VERSION ""

NS_ :

BS_:

BU_: SBW iBooster IMG ESB EBB TM ACC SRS SMART NAVI AHU FCM EPS HDS SS30 METER CVT STR ENG ABS VSA EAT RTC PUH EPT2 EPT1 EPB ASC ACM BCM E4WD ANC TPMS APS

BO_ 3221225472 VECTOR__INDEPENDENT_SIG_MSG: 0 Vector__XXX
 SG_ VSA_MAC_FVSTYLE1_1EF8AA15_1 : 0|4@0+ (1,0) [0|15] "" Vector__XXX
 SG_ SRS_RESET_FLAG_05E_1 : 0|1@0+ (1,0) [0|1] "-" Vector__XXX
 SG_ VSA_FAIL_MC_PRESS_SENSOR_05D_1 : 0|1@1- (1,0) [0|0] "" Vector__XXX
 SG_ VSA_ACC_INHBIT_ACC_BRK_PAD_TMP_1 : 0|1@0+ (1,0) [0|1] "" Vector__XXX
 SG_ VSA_INH_MODE6_1 : 0|1@0+ (1,0) [0|1] "" Vector__XXX
 SG_ VSA_INH_MODE5_1 : 0|1@0+ (1,0) [0|1] "" Vector__XXX
 SG_ VSA_INH_MODE4_1 : 0|1@0+ (1,0) [0|1] "" Vector__XXX
 SG_ VSA_CHECKSUM_1E8_1 : 0|4@0+ (1,0) [0|15] "" Vector__XXX
 SG_ VSA_ALIVE_COUNTER_1E8_1 : 0|2@0+ (1,0) [0|3] "" Vector__XXX
 SG_ VSA_INH_MODE_CHANGE_1 : 0|1@0+ (1,0) [0|1] "" Vector__XXX
 SG_ VSA_INH_MODE0_1 : 0|1@0+ (1,0) [0|1] "" Vector__XXX
 SG_ VSA_INH_MODE1_1 : 0|1@0+ (1,0) [0|1] "" Vector__XXX
 SG_ VSA_INH_MODE2_1 : 0|1@0+ (1,0) [0|1] "" Vector__XXX
 SG_ VSA_INH_MODE3_1 : 0|1@0+ (1,0) [0|1] "" Vector__XXX
 SG_ VSA_INH_MODE7_1 : 0|1@0+ (1,0) [0|1] "" Vector__XXX
 SG_ ENG_CAS_REQ_1 : 0|1@0+ (1,0) [0|1] "" Vector__XXX
 SG_ IMG_REQ_BRKRELAY_STATUS_1 : 0|1@0+ (1,0) [0|1] "" Vector__XXX

BO_ 2209174799 VSA_03AD550F_CH1: 3 VSA
 SG_ VSA_ALIVE_COUNTER_03AD550F_1 : 21|2@0+ (1,0) [0|3] ""  EPS
 SG_ VSA_CHECKSUM_03AD550F_1 : 19|4@0+ (1,0) [0|15] ""  EPS
 SG_ VSA_MAC_stRegMacKey_1 : 15|3@0+ (1,0) [0|7] ""  EPS
 SG_ VSA_MAC_stGenMac_1 : 2|3@0+ (1,0) [0|7] ""  EPS
 SG_ VSA_MAC_stCompMacCont_1 : 5|3@0+ (1,0) [0|7] ""  EPS
 SG_ VSA_MAC_stCompMacAccum_1 : 7|2@0+ (1,0) [0|3] ""  EPS

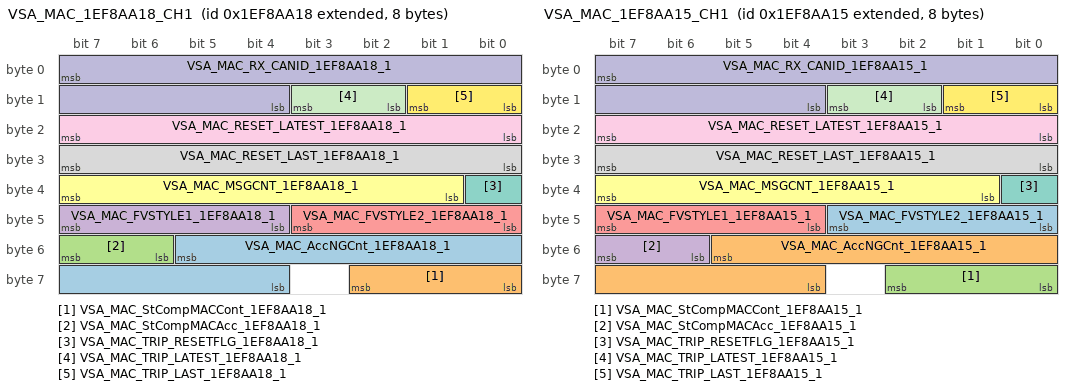
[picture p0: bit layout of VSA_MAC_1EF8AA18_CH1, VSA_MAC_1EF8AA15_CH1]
BO_ 2667096600 VSA_MAC_1EF8AA18_CH1: 8 Vector__XXX
 SG_ VSA_MAC_AccNGCnt_1EF8AA18_1 : 53|10@0+ (1,0) [0|1023] "" Vector__XXX
 SG_ VSA_MAC_StCompMACCont_1EF8AA18_1 : 58|3@0+ (1,0) [0|7] "" Vector__XXX
 SG_ VSA_MAC_StCompMACAcc_1EF8AA18_1 : 55|2@0+ (1,0) [0|3] "" Vector__XXX
 SG_ VSA_MAC_FVSTYLE1_1EF8AA18_1 : 47|4@0+ (1,0) [0|15] "" Vector__XXX
 SG_ VSA_MAC_FVSTYLE2_1EF8AA18_1 : 43|4@0+ (1,0) [0|15] "" Vector__XXX
 SG_ VSA_MAC_MSGCNT_1EF8AA18_1 : 39|7@0+ (1,0) [0|127] "" Vector__XXX
 SG_ VSA_MAC_TRIP_RESETFLG_1EF8AA18_1 : 32|1@0+ (1,0) [0|1] "" Vector__XXX
 SG_ VSA_MAC_RESET_LAST_1EF8AA18_1 : 31|8@0+ (1,0) [0|255] "" Vector__XXX
 SG_ VSA_MAC_RESET_LATEST_1EF8AA18_1 : 23|8@0+ (1,0) [0|255] "" Vector__XXX
 SG_ VSA_MAC_RX_CANID_1EF8AA18_1 : 7|12@0+ (1,0) [0|4095] "" Vector__XXX
 SG_ VSA_MAC_TRIP_LATEST_1EF8AA18_1 : 11|2@0+ (1,0) [0|3] "" Vector__XXX
 SG_ VSA_MAC_TRIP_LAST_1EF8AA18_1 : 9|2@0+ (1,0) [0|3] "" Vector__XXX

BO_ 2667096597 VSA_MAC_1EF8AA15_CH1: 8 Vector__XXX
 SG_ VSA_MAC_FVSTYLE2_1EF8AA15_1 : 43|4@0+ (1,0) [0|15] "" Vector__XXX
 SG_ VSA_MAC_AccNGCnt_1EF8AA15_1 : 53|10@0+ (1,0) [0|1023] "" Vector__XXX
 SG_ VSA_MAC_StCompMACCont_1EF8AA15_1 : 58|3@0+ (1,0) [0|7] "" Vector__XXX
 SG_ VSA_MAC_StCompMACAcc_1EF8AA15_1 : 55|2@0+ (1,0) [0|3] "" Vector__XXX
 SG_ VSA_MAC_FVSTYLE1_1EF8AA15_1 : 47|4@0+ (1,0) [0|15] "" Vector__XXX
 SG_ VSA_MAC_MSGCNT_1EF8AA15_1 : 39|7@0+ (1,0) [0|127] "" Vector__XXX
 SG_ VSA_MAC_TRIP_RESETFLG_1EF8AA15_1 : 32|1@0+ (1,0) [0|1] "" Vector__XXX
 SG_ VSA_MAC_RESET_LAST_1EF8AA15_1 : 31|8@0+ (1,0) [0|255] "" Vector__XXX
 SG_ VSA_MAC_RESET_LATEST_1EF8AA15_1 : 23|8@0+ (1,0) [0|255] "" Vector__XXX
 SG_ VSA_MAC_RX_CANID_1EF8AA15_1 : 7|12@0+ (1,0) [0|4095] "" Vector__XXX
 SG_ VSA_MAC_TRIP_LATEST_1EF8AA15_1 : 11|2@0+ (1,0) [0|3] "" Vector__XXX
 SG_ VSA_MAC_TRIP_LAST_1EF8AA15_1 : 9|2@0+ (1,0) [0|3] "" Vector__XXX

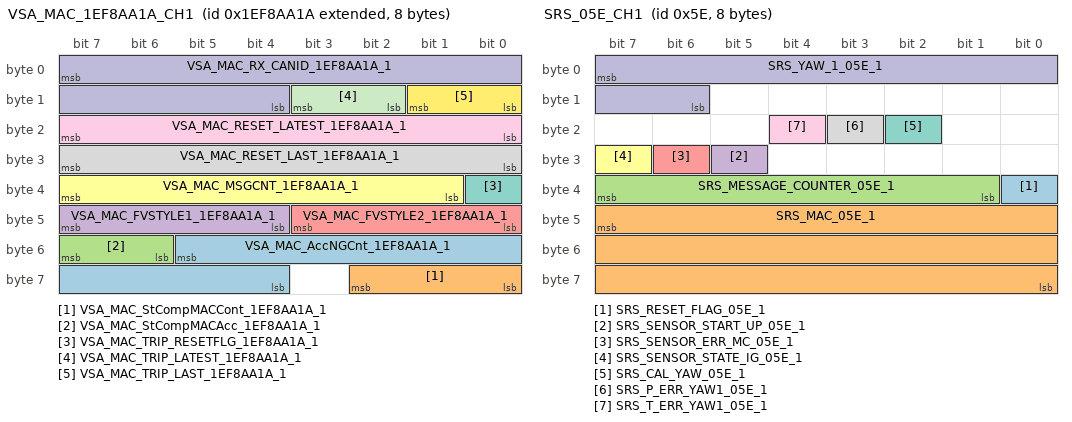
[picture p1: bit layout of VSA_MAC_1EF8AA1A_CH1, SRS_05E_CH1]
BO_ 2667096602 VSA_MAC_1EF8AA1A_CH1: 8 Vector__XXX
 SG_ VSA_MAC_AccNGCnt_1EF8AA1A_1 : 53|10@0+ (1,0) [0|1023] "" Vector__XXX
 SG_ VSA_MAC_StCompMACCont_1EF8AA1A_1 : 58|3@0+ (1,0) [0|7] "" Vector__XXX
 SG_ VSA_MAC_StCompMACAcc_1EF8AA1A_1 : 55|2@0+ (1,0) [0|3] "" Vector__XXX
 SG_ VSA_MAC_FVSTYLE1_1EF8AA1A_1 : 47|4@0+ (1,0) [0|15] "" Vector__XXX
 SG_ VSA_MAC_FVSTYLE2_1EF8AA1A_1 : 43|4@0+ (1,0) [0|15] "" Vector__XXX
 SG_ VSA_MAC_MSGCNT_1EF8AA1A_1 : 39|7@0+ (1,0) [0|127] "" Vector__XXX
 SG_ VSA_MAC_TRIP_RESETFLG_1EF8AA1A_1 : 32|1@0+ (1,0) [0|1] "" Vector__XXX
 SG_ VSA_MAC_RESET_LAST_1EF8AA1A_1 : 31|8@0+ (1,0) [0|255] "" Vector__XXX
 SG_ VSA_MAC_RESET_LATEST_1EF8AA1A_1 : 23|8@0+ (1,0) [0|255] "" Vector__XXX
 SG_ VSA_MAC_RX_CANID_1EF8AA1A_1 : 7|12@0+ (1,0) [0|4095] "" Vector__XXX
 SG_ VSA_MAC_TRIP_LATEST_1EF8AA1A_1 : 11|2@0+ (1,0) [0|3] "" Vector__XXX
 SG_ VSA_MAC_TRIP_LAST_1EF8AA1A_1 : 9|2@0+ (1,0) [0|3] "" Vector__XXX

BO_ 94 SRS_05E_CH1: 8 SRS
 SG_ SRS_RESET_FLAG_05E_1 : 32|1@0+ (1,0) [0|1] "-"  VSA
 SG_ SRS_MAC_05E_1 : 47|24@0+ (1,0) [0|16777215] ""  VSA
 SG_ SRS_MESSAGE_COUNTER_05E_1 : 39|7@0+ (1,0) [0|127] "-"  VSA
 SG_ SRS_SENSOR_START_UP_05E_1 : 29|1@0+ (1,0) [0|1] ""  VSA
 SG_ SRS_SENSOR_ERR_MC_05E_1 : 30|1@0+ (1,0) [0|1] "-"  VSA
 SG_ SRS_SENSOR_STATE_IG_05E_1 : 31|1@0+ (1,0) [0|1] ""  VSA
 SG_ SRS_CAL_YAW_05E_1 : 18|1@0+ (1,0) [0|1] "-"  VSA
 SG_ SRS_P_ERR_YAW1_05E_1 : 19|1@0+ (1,0) [0|1] "-"  VSA
 SG_ SRS_T_ERR_YAW1_05E_1 : 20|1@0+ (1,0) [0|1] "-"  VSA
 SG_ SRS_YAW_1_05E_1 : 7|10@0+ (0.244140625,-125) [0|1024] "deg/sec"  VSA

BO_ 524 EBB_20C_CH1: 8 iBooster
 SG_ EBB_MAC_20C_1 : 47|24@0+ (1,0) [0|16777216] ""  VSA
 SG_ EBB_MESSAGE_COUNTER_20C_1 : 39|7@0+ (1,0) [0|127] ""  VSA
 SG_ EBB_RESET_FLAG_20C_1 : 32|1@0+ (1,0) [0|1] "" Vector__XXX
 SG_ EBB_TARGET_PRESSURE_1 : 15|10@0+ (1,0) [0|1023] ""  VSA
 SG_ EBB_BRKMODE_STATUS_20C_1 : 7|3@0+ (1,0) [0|7] ""  VSA
 SG_ EBB_STATUS_20C_1 : 2|3@0+ (1,0) [0|7] ""  VSA

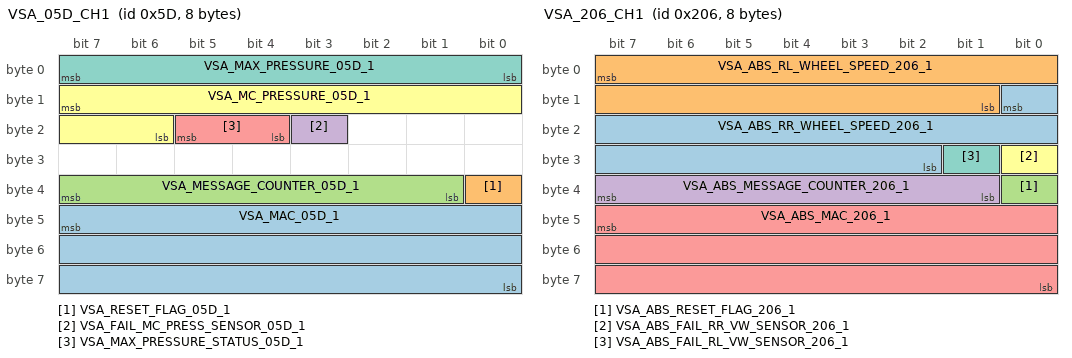
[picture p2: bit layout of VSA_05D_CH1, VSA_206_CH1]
BO_ 93 VSA_05D_CH1: 8 VSA
 SG_ VSA_MAC_05D_1 : 47|24@0+ (1,0) [0|0] "" Vector__XXX
 SG_ VSA_RESET_FLAG_05D_1 : 32|1@0+ (1,0) [0|0] ""  iBooster
 SG_ VSA_MESSAGE_COUNTER_05D_1 : 39|7@0+ (1,0) [0|127] ""  iBooster
 SG_ VSA_FAIL_MC_PRESS_SENSOR_05D_1 : 19|1@0+ (1,0) [0|1] ""  iBooster
 SG_ VSA_MAX_PRESSURE_STATUS_05D_1 : 21|2@0+ (1,0) [0|3] ""  iBooster
 SG_ VSA_MC_PRESSURE_05D_1 : 15|10@0+ (30,-3000) [-3000|27690] "KPa"  iBooster
 SG_ VSA_MAX_PRESSURE_05D_1 : 7|8@0+ (100,0) [0|25500] ""  iBooster

BO_ 777 METER_309_CH1: 8 METER
 SG_ METER_ALIVE_COUNTER_309_1 : 61|2@0+ (1,0) [0|0] ""  VSA
 SG_ METER_CHECKSUM_309_1 : 59|4@0+ (1,0) [0|0] ""  VSA
 SG_ METER_SPEED_UNIT_1 : 63|1@0+ (1,0) [0|0] ""  VSA
 SG_ METER_DIGITAL_SPEED_DISPLAY_1 : 31|8@0+ (1,0) [0|0] "km/h or mph"  VSA

BO_ 2588256839 VSA_1A45AA47_CH1: 8 VSA
 SG_ VSA_SUBRECO_UPDATE_1 : 19|2@0+ (1,0) [0|3] "" Vector__XXX
 SG_ VSA_OBS_UPDATE_1 : 3|2@0+ (1,0) [0|3] "" Vector__XXX
 SG_ VSA_FREEZE_UPDATE_1 : 17|2@0+ (1,0) [0|0] "" Vector__XXX
 SG_ VSA_DTC_UPDATE_1 : 1|2@0+ (1,0) [0|3] "" Vector__XXX
 SG_ VSA_CHECKSUM_1A45AA47_1 : 59|4@0+ (1,0) [0|15] "" Vector__XXX
 SG_ VSA_ALIVE_COUNTER_1A45AA47_1 : 61|2@0+ (1,0) [0|3] "" Vector__XXX

BO_ 315 ENG_13B_CH1: 7 ENG
 SG_ VSA_CHECKSUM_13B_1 : 51|4@0+ (1,0) [0|15] ""  VSA
 SG_ VSA_ALIVE_COUNTER_13B_1 : 53|2@0+ (1,0) [0|3] ""  VSA
 SG_ ENG_POWER_PLANT_SPEED_1 : 7|15@0+ (1,0) [0|32767] "rpm"  VSA

BO_ 179 IMG_0B3_CH1: 8 IMG
 SG_ IMG_CHECKSUM_0B3_1 : 59|4@0+ (1,0) [0|15] ""  VSA
 SG_ IMG_ALIVE_COUNTER_0B3_1 : 61|2@0+ (1,0) [0|4] ""  VSA
 SG_ EBB_BRKMODE_STATUS_0B3_1 : 12|3@0+ (1,0) [0|8] ""  VSA
 SG_ EBB_TARGET_PRESSURE_0B3_1 : 7|10@0+ (25,0) [0|25575] "Kpa"  VSA

BO_ 780 ACC_30C_CH1: 8 ACC
 SG_ ACC_CHECKSUM_30C_1 : 59|4@0+ (1,0) [0|15] ""  VSA
 SG_ ACC_ALIVE_COUNTER_30C_1 : 61|2@0+ (1,0) [0|3] ""  VSA
 SG_ ACC_INFO_IND_ACCLSF_ENGAGE_1 : 32|1@0+ (1,0) [0|1] ""  VSA

BO_ 856 SBW_358_CH1: 7 SBW
 SG_ SBW_CHECKSUM_358_1 : 51|4@0+ (1,0) [0|15] ""  VSA
 SG_ SBW_ALIVE_COUNTER_358_1 : 53|2@0+ (1,0) [0|3] ""  VSA
 SG_ SBW_MID_N_HOLD_1 : 20|1@0+ (1,0) [0|1] ""  VSA

BO_ 669 VSA_29D_CH1: 8 VSA
 SG_ VSA_RESET_COUNTER_29D_1 : 7|24@0+ (1,0) [0|16777215] "-" Vector__XXX
 SG_ VSA_MAC_29D_1 : 31|40@0+ (1,0) [0|1099511627775] "-" Vector__XXX

BO_ 668 VSA_29C_CH1: 8 VSA
 SG_ VSA_TRIP_COUNTER_29C_1 : 7|24@0+ (1,0) [0|16777215] "-" Vector__XXX
 SG_ VSA_MAC_29C_1 : 31|40@0+ (1,0) [0|1099511627775] "-" Vector__XXX

BO_ 518 VSA_206_CH1: 8 VSA
 SG_ VSA_ABS_RR_WHEEL_SPEED_206_1 : 8|15@0+ (0.01,0) [0|327.67] "km/h" Vector__XXX
 SG_ VSA_ABS_RL_WHEEL_SPEED_206_1 : 7|15@0+ (0.01,0) [0|327.67] "km/h" Vector__XXX
 SG_ VSA_ABS_RESET_FLAG_206_1 : 32|1@0+ (1,0) [0|1] "" Vector__XXX
 SG_ VSA_ABS_MESSAGE_COUNTER_206_1 : 39|7@0+ (1,0) [0|127] "" Vector__XXX
 SG_ VSA_ABS_MAC_206_1 : 47|24@0+ (1,0) [0|16777215] "" Vector__XXX
 SG_ VSA_ABS_FAIL_RR_VW_SENSOR_206_1 : 24|1@0+ (1,0) [0|1] "" Vector__XXX
 SG_ VSA_ABS_FAIL_RL_VW_SENSOR_206_1 : 25|1@0+ (1,0) [0|1] "" Vector__XXX

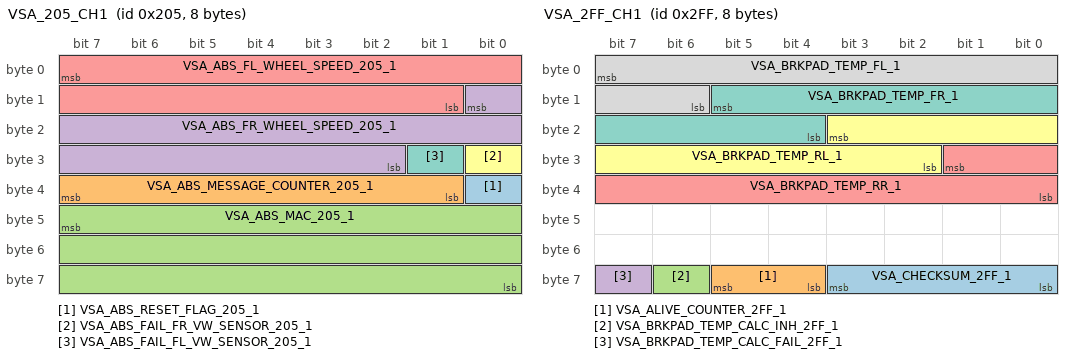
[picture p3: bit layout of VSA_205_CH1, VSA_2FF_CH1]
BO_ 517 VSA_205_CH1: 8 VSA
 SG_ VSA_ABS_RESET_FLAG_205_1 : 32|1@0+ (1,0) [0|1] "-" Vector__XXX
 SG_ VSA_ABS_MESSAGE_COUNTER_205_1 : 39|7@0+ (1,0) [0|127] "" Vector__XXX
 SG_ VSA_ABS_MAC_205_1 : 47|24@0+ (1,0) [0|16777215] "-" Vector__XXX
 SG_ VSA_ABS_FR_WHEEL_SPEED_205_1 : 8|15@0+ (0.01,0) [0|327.67] "km/h" Vector__XXX
 SG_ VSA_ABS_FL_WHEEL_SPEED_205_1 : 7|15@0+ (0.01,0) [0|327.67] "" Vector__XXX
 SG_ VSA_ABS_FAIL_FR_VW_SENSOR_205_1 : 24|1@0+ (1,0) [0|1] "" Vector__XXX
 SG_ VSA_ABS_FAIL_FL_VW_SENSOR_205_1 : 25|1@0+ (1,0) [0|1] "" Vector__XXX

BO_ 425 VSA_1A9_CH1: 8 VSA
 SG_ VSA_FZR_LIM_B_1 : 0|1@0+ (1,0) [0|1] ""  E4WD
 SG_ VSA_FZR_CTCS_B_1 : 4|1@0+ (1,0) [0|1] ""  E4WD
 SG_ VSA_E4WD_TRQ_UP_REQ_1 : 31|8@0+ (10,0) [0|2550] "Nm"  E4WD
 SG_ VSA_E4WD_TRQ_LIMITER_REQ_1 : 15|8@0+ (10,0) [0|2550] "Nm"  E4WD
 SG_ VSA_CHECKSUM_1A9_1 : 59|4@0+ (1,0) [0|15] ""  E4WD
 SG_ VSA_ALIVE_COUNTER_1A9_1 : 61|2@0+ (1,0) [0|3] ""  E4WD

BO_ 332 ESB_14C_CH1: 8 ESB
 SG_ ESB_RESET_FLAG_14C_1 : 32|1@0+ (1,0) [0|1] ""  VSA
 SG_ ESB_REQ_HBC_14C_1 : 7|1@0+ (1,0) [0|1] ""  VSA
 SG_ ESB_MESSAGE_COUNTER_14C_1 : 39|7@0+ (1,0) [0|127] ""  VSA
 SG_ ESB_MAC_14C_1 : 47|24@0+ (1,0) [0|16777215] ""  VSA

BO_ 767 VSA_2FF_CH1: 8 VSA
 SG_ VSA_CHECKSUM_2FF_1 : 59|4@0+ (1,0) [0|15] "" Vector__XXX
 SG_ VSA_ALIVE_COUNTER_2FF_1 : 61|2@0+ (1,0) [0|3] "" Vector__XXX
 SG_ VSA_BRKPAD_TEMP_CALC_INH_2FF_1 : 62|1@0+ (1,0) [0|1] "" Vector__XXX
 SG_ VSA_BRKPAD_TEMP_CALC_FAIL_2FF_1 : 63|1@0+ (1,0) [0|1] "" Vector__XXX
 SG_ VSA_BRKPAD_TEMP_RR_1 : 25|10@0+ (1,0) [0|1023] "degc" Vector__XXX
 SG_ VSA_BRKPAD_TEMP_RL_1 : 19|10@0+ (1,0) [0|1023] "degc" Vector__XXX
 SG_ VSA_BRKPAD_TEMP_FR_1 : 13|10@0+ (1,0) [0|1023] "degc" Vector__XXX
 SG_ VSA_BRKPAD_TEMP_FL_1 : 7|10@0+ (1,0) [0|1023] "degc" Vector__XXX

BO_ 555 IMG_22B_CH1: 8 IMG
 SG_ IMG_CHECKSUM_22B_1 : 59|4@0+ (1,0) [0|15] ""  VSA
 SG_ IMG_ALIVE_COUNTER_22B_1 : 61|2@0+ (1,0) [0|3] ""  VSA
 SG_ IMG_IDS_GRP_A3_MODE_1 : 15|4@0+ (1,0) [0|15] ""  VSA

BO_ 562 APS_232_CH1: 4 APS
 SG_ APS_ALIVE_COUNTER_232_1 : 29|2@0+ (1,0) [0|3] "" Vector__XXX
 SG_ APS_CHECKSUM_232_1 : 27|4@0+ (1,0) [0|16] "" Vector__XXX
 SG_ APS_SYSTEM_ACTIVE_1 : 2|1@0+ (1,0) [0|1] "" Vector__XXX

BO_ 1646 VSA_66E_CH1: 8 VSA
 SG_ VSA_CHECKSUM_66E_1 : 59|4@0+ (1,0) [0|15] ""  NAVI
 SG_ VSA_ALIVE_COUNTER_66E_1 : 61|2@0+ (1,0) [0|3] ""  NAVI
 SG_ VSA_OBS_OVERWRITE_1 : 62|1@0+ (1,0) [0|1] ""  NAVI
 SG_ VSA_OBS_TRIGGER_1 : 63|1@0+ (1,0) [0|1] ""  NAVI
 SG_ VSA_MCPS_OFFSET_1 : 35|4@0+ (100,-700) [0|0] ""  NAVI
 SG_ VSA_CALIB_STATUS_STR_1 : 36|1@0+ (1,0) [0|1] ""  NAVI
 SG_ VSA_CALIB_STATUS_LONG_1 : 37|1@0+ (1,0) [0|1] ""  NAVI
 SG_ VSA_CALIB_STATUS_LATG_1 : 38|1@0+ (1,0) [0|1] ""  NAVI
 SG_ VSA_CALIB_STATUS_YAW_1 : 39|1@0+ (1,0) [0|1] ""  NAVI
 SG_ VSA_ADDFUNC_ACT_1 : 27|4@0+ (1,0) [0|15] ""  NAVI
 SG_ VSA_MAINFUNC_ACT_AHA_1 : 31|1@0+ (1,0) [0|1] ""  NAVI
 SG_ VSA_MAINFUNC_ACT_ABH_1 : 16|1@0+ (1,0) [0|1] ""  NAVI
 SG_ VSA_MAINFUNC_ACT_HSA_1 : 17|1@0+ (1,0) [0|1] ""  NAVI
 SG_ VSA_MAINFUNC_ACT_AYC_1 : 18|1@0+ (1,0) [0|1] ""  NAVI
 SG_ VSA_MAINFUNC_ACT_ETCS_1 : 19|1@0+ (1,0) [0|1] ""  NAVI
 SG_ VSA_MAINFUNC_ACT_BTCS_1 : 20|1@0+ (1,0) [0|1] ""  NAVI
 SG_ VSA_MAINFUNC_ACT_BAS_1 : 21|1@0+ (1,0) [0|1] ""  NAVI
 SG_ VSA_MAINFUNC_ACT_ABS_1 : 22|1@0+ (1,0) [0|1] ""  NAVI
 SG_ VSA_MAINFUNC_ACT_EBD_1 : 23|1@0+ (1,0) [0|1] ""  NAVI
 SG_ VSA_OFFMODE_INFO_1 : 11|2@0+ (1,0) [0|3] ""  NAVI
 SG_ VSA_VEHICLE_MODE_INFO_1 : 15|4@0+ (1,0) [0|15] ""  NAVI
 SG_ VSA_IG_VOLTAGE_1 : 7|8@0+ (0.1,0) [0|25.5] ""  NAVI

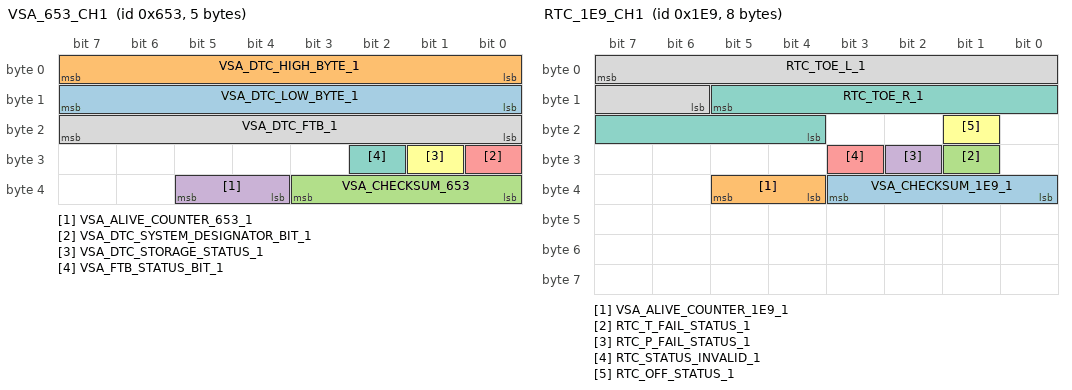
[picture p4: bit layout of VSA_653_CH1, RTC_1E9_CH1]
BO_ 1619 VSA_653_CH1: 5 VSA
 SG_ VSA_DTC_LOW_BYTE_1 : 15|8@0+ (1,0) [0|0] "" Vector__XXX
 SG_ VSA_DTC_HIGH_BYTE_1 : 7|8@0+ (1,0) [0|0] "" Vector__XXX
 SG_ VSA_CHECKSUM_653 : 35|4@0+ (1,0) [0|15] "" Vector__XXX
 SG_ VSA_ALIVE_COUNTER_653_1 : 37|2@0+ (1,0) [0|3] "" Vector__XXX
 SG_ VSA_DTC_SYSTEM_DESIGNATOR_BIT_1 : 24|1@0+ (1,0) [0|1] "" Vector__XXX
 SG_ VSA_DTC_STORAGE_STATUS_1 : 25|1@0+ (1,0) [0|1] "" Vector__XXX
 SG_ VSA_FTB_STATUS_BIT_1 : 26|1@0+ (1,0) [0|1] "" Vector__XXX
 SG_ VSA_DTC_FTB_1 : 23|8@0+ (1,0) [0|0] "" Vector__XXX

BO_ 546 METER_222_CH1: 3 METER
 SG_ METER_CHECKSUM_222_1 : 19|4@0+ (1,0) [0|15] ""  VSA
 SG_ METER_ALIVE_COUNTER_222 : 21|2@0+ (1,0) [0|3] ""  VSA
 SG_ METER_IDS_MODE_1 : 7|2@0+ (1,0) [0|3] ""  VSA

BO_ 845 VSA_34D_CH1: 2 VSA
 SG_ VSA_CHECKSUM_34D_1 : 11|4@0+ (1,0) [0|15] "" Vector__XXX
 SG_ VSA_ALIVE_COUNTER_34D_1 : 13|2@0+ (1,0) [0|3] "" Vector__XXX
 SG_ VSA_VSA_MODE_STATUS_1 : 2|3@0+ (1,0) [0|7] "" Vector__XXX

BO_ 489 RTC_1E9_CH1: 8 RTC
 SG_ VSA_CHECKSUM_1E9_1 : 35|4@0+ (1,0) [0|15] ""  VSA
 SG_ VSA_ALIVE_COUNTER_1E9_1 : 37|2@0+ (1,0) [0|3] ""  VSA
 SG_ RTC_T_FAIL_STATUS_1 : 25|1@0+ (1,0) [0|1] ""  VSA
 SG_ RTC_P_FAIL_STATUS_1 : 26|1@0+ (1,0) [0|1] ""  VSA
 SG_ RTC_STATUS_INVALID_1 : 27|1@0+ (1,0) [0|1] ""  VSA
 SG_ RTC_OFF_STATUS_1 : 17|1@0+ (1,0) [0|1] ""  VSA
 SG_ RTC_TOE_R_1 : 13|10@0- (0.0043,0) [-2.2016|2.2016] "deg"  VSA
 SG_ RTC_TOE_L_1 : 7|10@0- (0.0043,0) [-2.2016|2.2016] "deg"  VSA

BO_ 493 ENG_1ED_CH1: 8 ENG
 SG_ ENG_CHECKSUM_1ED_1 : 43|4@0+ (1,0) [0|15] ""  VSA
 SG_ ENG_ALIVE_COUNTER_1ED_1 : 45|2@0+ (1,0) [0|3] ""  VSA
 SG_ ENG_POWER_PLANT_SPEED_1 : 29|15@0+ (1,0) [0|32767] "rpm"  VSA

BO_ 446 EBB_1BE_CH1: 3 EBB
 SG_ EBB_BRAKE_PEDAL_ON_STATUS : 3|2@0+ (1,0) [0|0] "" Vector__XXX
 SG_ EBB_IG_ON_1 : 1|1@0+ (1,0) [0|1] ""  VSA
 SG_ EBB_BRAKE_PEDAL_ON : 4|1@0+ (1,0) [0|1] ""  VSA
 SG_ EBB_CHECKSUM_1BE_1 : 19|4@0+ (1,0) [0|15] ""  VSA
 SG_ EBB_ALIVE_COUNTER_1BE_1 : 21|2@0+ (1,0) [0|3] ""  VSA
 SG_ EBB_STATUS_1BE_1 : 7|3@0+ (1,0) [0|7] ""  VSA

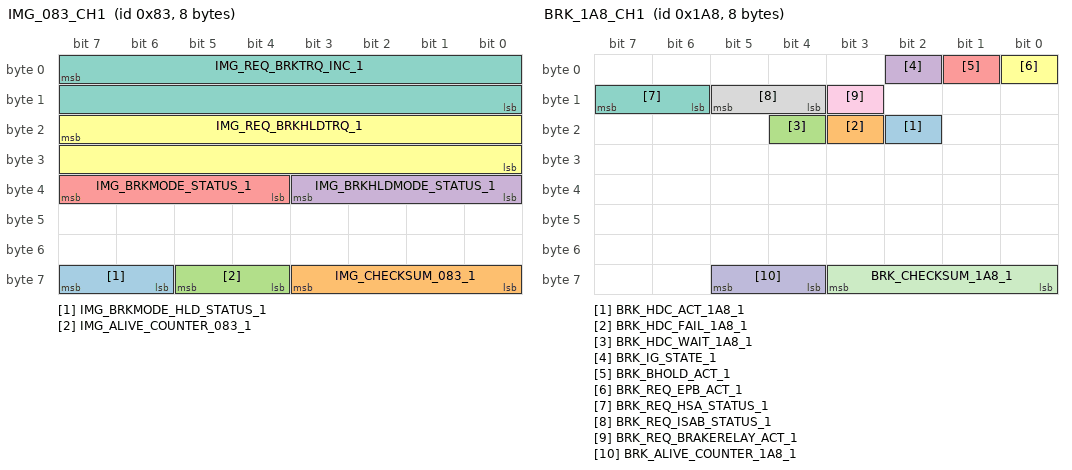
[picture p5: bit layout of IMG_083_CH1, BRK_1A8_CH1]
BO_ 131 IMG_083_CH1: 8 IMG
 SG_ IMG_BRKMODE_HLD_STATUS_1 : 63|2@0+ (1,0) [0|3] ""  VSA
 SG_ IMG_CHECKSUM_083_1 : 59|4@0+ (1,0) [0|15] ""  VSA
 SG_ IMG_ALIVE_COUNTER_083_1 : 61|2@0+ (1,0) [0|3] ""  VSA
 SG_ IMG_BRKHLDMODE_STATUS_1 : 35|4@0+ (1,0) [0|15] ""  VSA
 SG_ IMG_BRKMODE_STATUS_1 : 39|4@0+ (1,0) [0|15] ""  VSA
 SG_ IMG_REQ_BRKHLDTRQ_1 : 23|16@0+ (0.1,0) [0|6553.5] "Nm"  VSA
 SG_ IMG_REQ_BRKTRQ_INC_1 : 7|16@0+ (1,0) [0|65535] "Nm"  VSA

BO_ 424 BRK_1A8_CH1: 8 IMG
 SG_ BRK_HDC_ACT_1A8_1 : 18|1@0+ (1,0) [0|1] "" Vector__XXX
 SG_ BRK_HDC_FAIL_1A8_1 : 19|1@0+ (1,0) [0|1] "" Vector__XXX
 SG_ BRK_HDC_WAIT_1A8_1 : 20|1@0+ (1,0) [0|1] "" Vector__XXX
 SG_ BRK_IG_STATE_1 : 2|1@0+ (1,0) [0|1] ""  VSA
 SG_ BRK_BHOLD_ACT_1 : 1|1@0+ (1,0) [0|1] ""  VSA
 SG_ BRK_REQ_EPB_ACT_1 : 0|1@0+ (1,0) [0|1] ""  VSA
 SG_ BRK_REQ_HSA_STATUS_1 : 15|2@0+ (1,0) [0|3] ""  VSA
 SG_ BRK_REQ_ISAB_STATUS_1 : 13|2@0+ (1,0) [0|3] ""  VSA
 SG_ BRK_REQ_BRAKERELAY_ACT_1 : 11|1@0+ (1,0) [0|1] ""  VSA
 SG_ BRK_ALIVE_COUNTER_1A8_1 : 61|2@0+ (1,0) [0|3] ""  VSA
 SG_ BRK_CHECKSUM_1A8_1 : 59|4@0+ (1,0) [0|15] ""  VSA

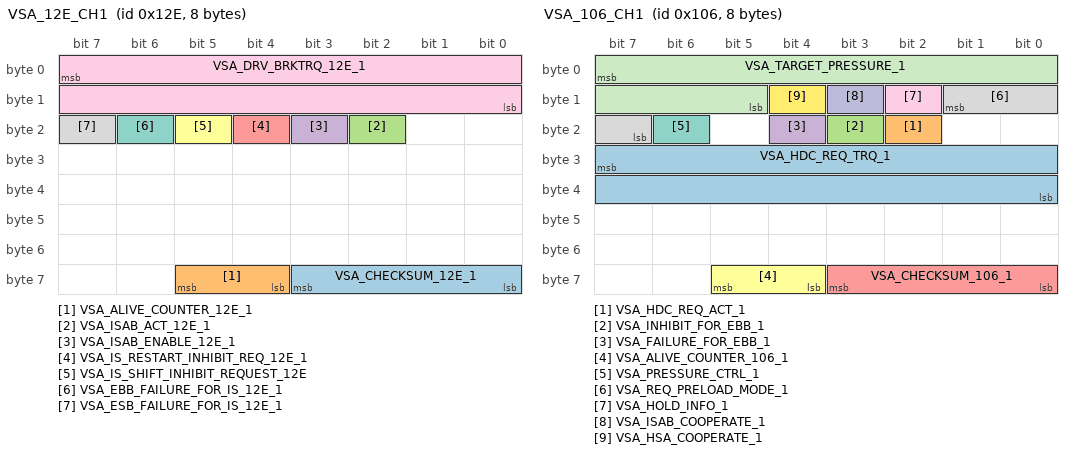
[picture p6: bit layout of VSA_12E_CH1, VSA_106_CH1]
BO_ 302 VSA_12E_CH1: 8 VSA
 SG_ VSA_CHECKSUM_12E_1 : 59|4@0+ (1,0) [0|15] "" Vector__XXX
 SG_ VSA_ALIVE_COUNTER_12E_1 : 61|2@0+ (1,0) [0|3] "" Vector__XXX
 SG_ VSA_ISAB_ACT_12E_1 : 18|1@0+ (1,0) [0|1] "" Vector__XXX
 SG_ VSA_ISAB_ENABLE_12E_1 : 19|1@0+ (1,0) [0|1] "" Vector__XXX
 SG_ VSA_IS_RESTART_INHIBIT_REQ_12E_1 : 20|1@0+ (1,0) [0|1] "" Vector__XXX
 SG_ VSA_IS_SHIFT_INHIBIT_REQUEST_12E : 21|1@0+ (1,0) [0|1] "" Vector__XXX
 SG_ VSA_EBB_FAILURE_FOR_IS_12E_1 : 22|1@0+ (1,0) [0|1] "" Vector__XXX
 SG_ VSA_ESB_FAILURE_FOR_IS_12E_1 : 23|1@0+ (1,0) [0|1] "" Vector__XXX
 SG_ VSA_DRV_BRKTRQ_12E_1 : 7|16@0+ (1,0) [0|65535] "Nm" Vector__XXX

BO_ 262 VSA_106_CH1: 8 VSA
 SG_ VSA_HDC_REQ_TRQ_1 : 31|16@0+ (1,0) [0|65535] "" Vector__XXX
 SG_ VSA_HDC_REQ_ACT_1 : 18|1@0+ (1,0) [0|1] "" Vector__XXX
 SG_ VSA_INHIBIT_FOR_EBB_1 : 19|1@0+ (1,0) [0|1] "" Vector__XXX
 SG_ VSA_FAILURE_FOR_EBB_1 : 20|1@0+ (1,0) [0|1] "" Vector__XXX
 SG_ VSA_CHECKSUM_106_1 : 59|4@0+ (1,0) [0|15] "" Vector__XXX
 SG_ VSA_ALIVE_COUNTER_106_1 : 61|2@0+ (1,0) [0|3] "" Vector__XXX
 SG_ VSA_PRESSURE_CTRL_1 : 22|1@0+ (1,0) [0|1] "" Vector__XXX
 SG_ VSA_REQ_PRELOAD_MODE_1 : 9|3@0+ (1,0) [0|7] "" Vector__XXX
 SG_ VSA_HOLD_INFO_1 : 10|1@0+ (1,0) [0|1] "" Vector__XXX
 SG_ VSA_ISAB_COOPERATE_1 : 11|1@0+ (1,0) [0|1] "" Vector__XXX
 SG_ VSA_TARGET_PRESSURE_1 : 7|11@0+ (23.96,0) [0|49046.12] "kPa" Vector__XXX
 SG_ VSA_HSA_COOPERATE_1 : 12|1@0+ (1,0) [0|1] "" Vector__XXX

BO_ 1108 ENG_454_CH1: 8 ENG
 SG_ ENG_CHECKSUM_454_1 : 59|4@0+ (1,0) [0|15] ""  VSA
 SG_ ENG_ALIVE_COUNTER_454_1 : 61|2@0+ (1,0) [0|3] ""  VSA
 SG_ ENG_FAIL_PA_1 : 20|1@0+ (1,0) [0|1] ""  VSA
 SG_ ENG_ATMOSPHERIC_PRESSURE_1 : 15|8@0+ (2.685,91.4) [91.4|776.075] "mmHg"  VSA

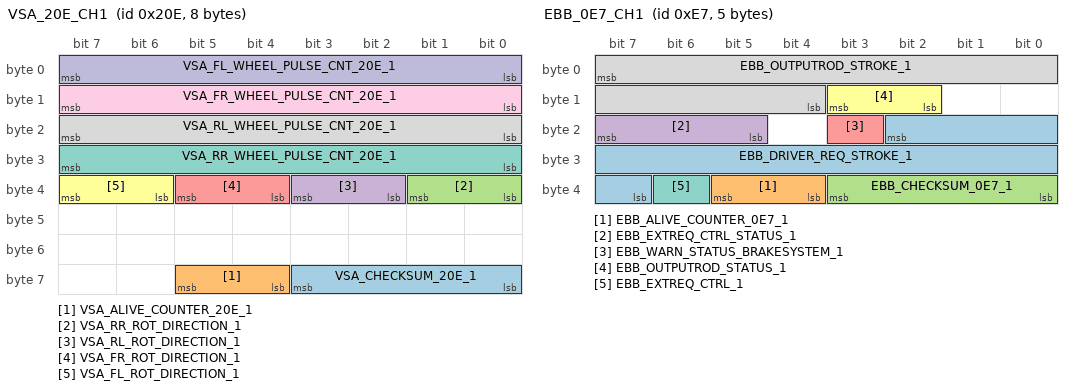
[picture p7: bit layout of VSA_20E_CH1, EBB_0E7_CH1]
BO_ 526 VSA_20E_CH1: 8 VSA
 SG_ VSA_CHECKSUM_20E_1 : 59|4@0+ (1,0) [0|15] "" Vector__XXX
 SG_ VSA_ALIVE_COUNTER_20E_1 : 61|2@0+ (1,0) [0|3] "" Vector__XXX
 SG_ VSA_RR_ROT_DIRECTION_1 : 33|2@0+ (1,0) [0|3] "" Vector__XXX
 SG_ VSA_RL_ROT_DIRECTION_1 : 35|2@0+ (1,0) [0|3] "" Vector__XXX
 SG_ VSA_FR_ROT_DIRECTION_1 : 37|2@0+ (1,0) [0|3] "" Vector__XXX
 SG_ VSA_FL_ROT_DIRECTION_1 : 39|2@0+ (1,0) [0|3] "" Vector__XXX
 SG_ VSA_RR_WHEEL_PULSE_CNT_20E_1 : 31|8@0+ (1,0) [0|255] "" Vector__XXX
 SG_ VSA_RL_WHEEL_PULSE_CNT_20E_1 : 23|8@0+ (1,0) [0|255] "" Vector__XXX
 SG_ VSA_FR_WHEEL_PULSE_CNT_20E_1 : 15|8@0+ (1,0) [0|255] "" Vector__XXX
 SG_ VSA_FL_WHEEL_PULSE_CNT_20E_1 : 7|8@0+ (1,0) [0|255] "" Vector__XXX

BO_ 1571 VSA_623_CH1: 3 VSA
 SG_ VSA_CHECKSUM_623_1 : 19|4@0+ (1,0) [0|0] "" Vector__XXX
 SG_ VSA_ALIVE_COUNTER_623_1 : 21|2@0+ (1,0) [0|0] "" Vector__XXX
 SG_ VSA_ID_1 : 7|16@0+ (1,0) [0|0] ""  BCM

BO_ 1302 METER_516_CH1: 8 METER
 SG_ METER_UNDER10V_516_1 : 42|1@0+ (1,0) [0|1] ""  VSA
 SG_ METER_CHECKSUM_516_1 : 59|4@0+ (1,0) [0|15] ""  VSA
 SG_ METER_ALIVE_COUNTER_516_1 : 61|2@0+ (1,0) [0|3] ""  VSA
 SG_ METER_ODO_DATA_1 : 7|24@0+ (1,0) [0|16777215] "Km"  VSA

BO_ 1568 BCM_620_CH1: 2 BCM
 SG_ BCM_CHECKSUM_620_1 : 11|4@0+ (1,0) [0|0] ""  VSA
 SG_ BCM_ALIVE_COUNTER_620_1 : 13|2@0+ (1,0) [0|0] ""  VSA
 SG_ BCM_ID_REQ_VSA_REC_1 : 3|1@0+ (1,0) [0|0] ""  VSA
 SG_ BCM_ID_REQ_VSA_1 : 6|1@0+ (1,0) [0|0] ""  VSA

BO_ 231 EBB_0E7_CH1: 5 EBB
 SG_ EBB_DRIVER_REQ_STROKE_1 : 18|12@0+ (0.015625,-5) [-5|58.984375] "mm"  VSA
 SG_ EBB_ALIVE_COUNTER_0E7_1 : 37|2@0+ (1,0) [0|3] ""  VSA
 SG_ EBB_CHECKSUM_0E7_1 : 35|4@0+ (1,0) [0|15] ""  VSA
 SG_ EBB_EXTREQ_CTRL_STATUS_1 : 23|3@0+ (1,0) [0|7] ""  VSA
 SG_ EBB_WARN_STATUS_BRAKESYSTEM_1 : 19|1@0+ (1,0) [0|1] ""  VSA
 SG_ EBB_OUTPUTROD_STATUS_1 : 11|2@0+ (1,0) [0|3] ""  VSA
 SG_ EBB_EXTREQ_CTRL_1 : 38|1@0+ (1,0) [0|1] ""  VSA
 SG_ EBB_OUTPUTROD_STROKE_1 : 7|12@0+ (0.015625,-5) [-5|58.9844] "mm"  VSA

BO_ 929 METER_3A1_CH1: 8 METER
 SG_ METER_CHECKSUM_3A1_1 : 59|4@0+ (1,0) [0|15] ""  VSA
 SG_ METER_ALIVE_COUNTER_3A1_1 : 61|2@0+ (1,0) [0|3] ""  VSA
 SG_ METER_DWS_INIT_REQ_SW_1 : 18|1@0+ (1,0) [0|1] ""  VSA
 SG_ METER_DWS_INIT_REQ_1 : 19|1@0+ (1,0) [0|1] ""  VSA

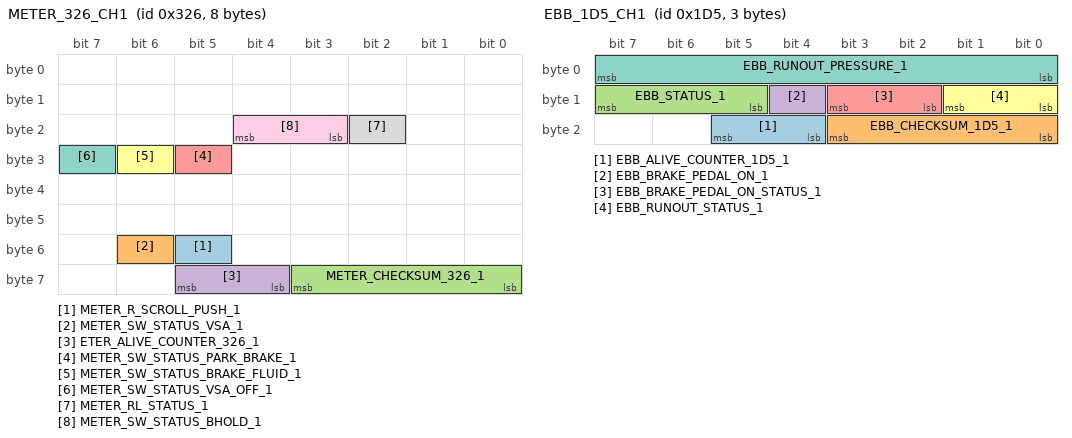
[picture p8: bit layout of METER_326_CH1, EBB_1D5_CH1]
BO_ 806 METER_326_CH1: 8 METER
 SG_ METER_R_SCROLL_PUSH_1 : 53|1@0+ (1,0) [0|1] ""  VSA
 SG_ METER_SW_STATUS_VSA_1 : 54|1@0+ (1,0) [0|1] ""  VSA
 SG_ METER_CHECKSUM_326_1 : 59|4@0+ (1,0) [0|15] ""  VSA
 SG_ ETER_ALIVE_COUNTER_326_1 : 61|2@0+ (1,0) [0|3] ""  VSA
 SG_ METER_SW_STATUS_PARK_BRAKE_1 : 29|1@0+ (1,0) [0|1] ""  VSA
 SG_ METER_SW_STATUS_BRAKE_FLUID_1 : 30|1@0+ (1,0) [0|1] ""  VSA
 SG_ METER_SW_STATUS_VSA_OFF_1 : 31|1@0+ (1,0) [0|1] ""  VSA
 SG_ METER_RL_STATUS_1 : 18|1@0+ (1,0) [0|1] ""  VSA
 SG_ METER_SW_STATUS_BHOLD_1 : 20|2@0+ (1,0) [0|3] ""  VSA

BO_ 469 EBB_1D5_CH1: 3 EBB
 SG_ EBB_ALIVE_COUNTER_1D5_1 : 21|2@0+ (1,0) [0|3] ""  VSA
 SG_ EBB_CHECKSUM_1D5_1 : 19|4@0+ (1,0) [0|15] ""  VSA
 SG_ EBB_STATUS_1 : 15|3@0+ (1,0) [0|7] ""  VSA
 SG_ EBB_BRAKE_PEDAL_ON_1 : 12|1@0+ (1,0) [0|1] ""  VSA
 SG_ EBB_BRAKE_PEDAL_ON_STATUS_1 : 11|2@0+ (1,0) [0|3] ""  VSA
 SG_ EBB_RUNOUT_STATUS_1 : 9|2@0+ (1,0) [0|3] ""  VSA
 SG_ EBB_RUNOUT_PRESSURE_1 : 7|8@0+ (100,0) [0|25500] "KPa"  VSA

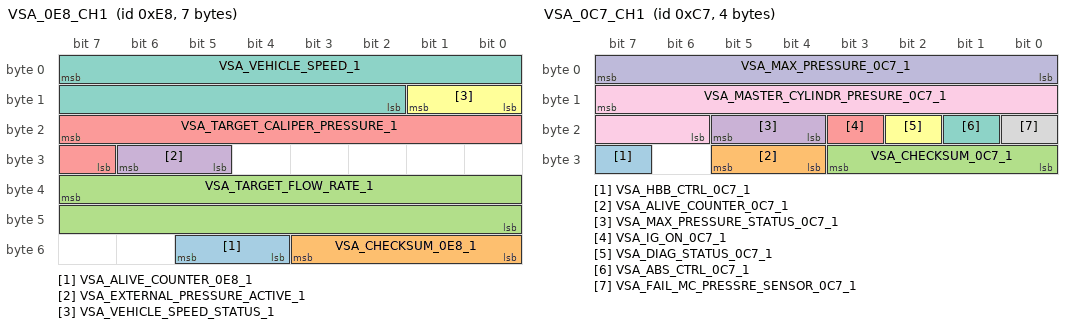
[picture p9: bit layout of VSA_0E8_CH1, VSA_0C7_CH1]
BO_ 232 VSA_0E8_CH1: 7 VSA
 SG_ VSA_ALIVE_COUNTER_0E8_1 : 53|2@0+ (1,0) [0|3] ""  ENG
 SG_ VSA_CHECKSUM_0E8_1 : 51|4@0+ (1,0) [0|15] "" Vector__XXX
 SG_ VSA_TARGET_FLOW_RATE_1 : 39|16@0+ (0.0078125,-252) [-252|252] "ml/s" Vector__XXX
 SG_ VSA_EXTERNAL_PRESSURE_ACTIVE_1 : 30|2@0+ (1,0) [0|3] "" Vector__XXX
 SG_ VSA_TARGET_CALIPER_PRESSURE_1 : 23|9@0+ (12.5,0) [0|6387.5] "KPa" Vector__XXX
 SG_ VSA_VEHICLE_SPEED_STATUS_1 : 9|2@0+ (1,0) [0|3] "" Vector__XXX
 SG_ VSA_VEHICLE_SPEED_1 : 7|14@0+ (0.015625,0) [0|255.984375] "m/s" Vector__XXX

BO_ 199 VSA_0C7_CH1: 4 VSA
 SG_ VSA_HBB_CTRL_0C7_1 : 31|1@0+ (1,0) [0|1] ""  EBB
 SG_ VSA_ALIVE_COUNTER_0C7_1 : 29|2@0+ (1,0) [0|3] ""  EBB
 SG_ VSA_CHECKSUM_0C7_1 : 27|4@0+ (1,0) [0|15] ""  EBB
 SG_ VSA_MAX_PRESSURE_STATUS_0C7_1 : 21|2@0+ (1,0) [0|3] ""  EBB
 SG_ VSA_IG_ON_0C7_1 : 19|1@0+ (1,0) [0|1] ""  EBB
 SG_ VSA_DIAG_STATUS_0C7_1 : 18|1@0+ (1,0) [0|1] ""  EBB
 SG_ VSA_ABS_CTRL_0C7_1 : 17|1@0+ (1,0) [0|1] ""  EBB
 SG_ VSA_FAIL_MC_PRESSRE_SENSOR_0C7_1 : 16|1@0+ (1,0) [0|1] ""  EBB
 SG_ VSA_MASTER_CYLINDR_PRESURE_0C7_1 : 15|10@0+ (30,-3000) [-3000|27690] "KPa"  EBB
 SG_ VSA_MAX_PRESSURE_0C7_1 : 7|8@0+ (100,0) [0|25000] "KPa"  EBB

BO_ 465 VSA_1D1_CH1: 4 VSA
 SG_ VSA_MP_PRESSURE_START_UP_1 : 12|1@0+ (1,0) [0|1] ""  ENG
 SG_ VSA_MP_PRESSURE_ERR_1_1 : 13|1@0+ (1,0) [0|1] ""  ENG
 SG_ VSA_MP_PRESSURE_1_1 : 7|10@0+ (0.1,0) [-102.3|0] "kPa"  ENG
 SG_ VSA_CHECKSUM_1D1_1 : 27|4@0+ (1,0) [0|15] ""  ENG
 SG_ VSA_ALIVE_COUNTER_1D1_1 : 29|2@0+ (1,0) [0|3] ""  ENG

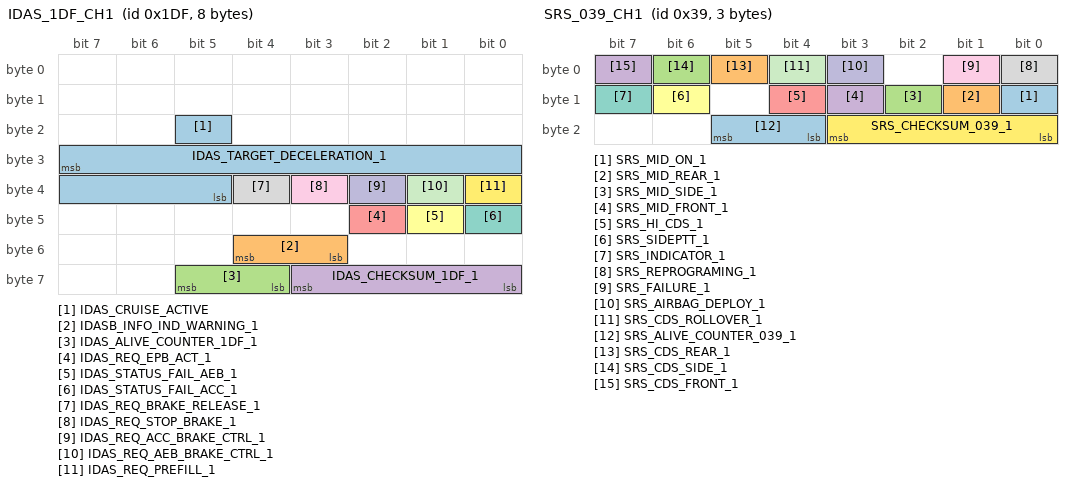
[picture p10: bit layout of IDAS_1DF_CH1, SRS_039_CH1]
BO_ 479 IDAS_1DF_CH1: 8 ACC
 SG_ IDAS_CRUISE_ACTIVE : 21|1@0+ (1,0) [0|1] ""  VSA
 SG_ IDASB_INFO_IND_WARNING_1 : 52|2@0+ (1,0) [0|3] ""  VSA
 SG_ IDAS_ALIVE_COUNTER_1DF_1 : 61|2@0+ (1,0) [0|3] ""  VSA
 SG_ IDAS_CHECKSUM_1DF_1 : 59|4@0+ (1,0) [0|15] ""  VSA
 SG_ IDAS_REQ_EPB_ACT_1 : 42|1@0+ (1,0) [0|1] ""  VSA
 SG_ IDAS_STATUS_FAIL_AEB_1 : 41|1@0+ (1,0) [0|1] ""  VSA
 SG_ IDAS_STATUS_FAIL_ACC_1 : 40|1@0+ (1,0) [0|1] ""  VSA
 SG_ IDAS_REQ_BRAKE_RELEASE_1 : 36|1@0+ (1,0) [0|1] ""  VSA
 SG_ IDAS_REQ_STOP_BRAKE_1 : 35|1@0+ (1,0) [0|1] ""  VSA
 SG_ IDAS_REQ_ACC_BRAKE_CTRL_1 : 34|1@0+ (1,0) [0|1] ""  VSA
 SG_ IDAS_REQ_AEB_BRAKE_CTRL_1 : 33|1@0+ (1,0) [0|1] ""  VSA
 SG_ IDAS_REQ_PREFILL_1 : 32|1@0+ (1,0) [0|1] ""  VSA
 SG_ IDAS_TARGET_DECELERATION_1 : 31|11@0- (0.01,0) [-10.24|10.23] "m/s2"  VSA

BO_ 423 EAT_1A7_CH1: 2 EAT
 SG_ EAT_CHECKSUM_1A7_1 : 11|4@0+ (1,0) [0|15] ""  VSA
 SG_ EAT_ALIVE_COUNTER_1A7_1 : 13|2@0+ (1,0) [0|3] ""  VSA
 SG_ EAT_FAILURE_FOR_EPB_1 : 5|1@0+ (1,0) [0|1] ""  VSA
 SG_ EAT_ATRVS_SW_STATUS_1 : 6|1@0+ (1,0) [0|1] ""  VSA
 SG_ EAT_ATFWD_SW_STATUS_1 : 7|1@0+ (1,0) [0|1] ""  VSA

BO_ 57 SRS_039_CH1: 3 SRS
 SG_ SRS_MID_ON_1 : 8|1@0+ (1,0) [0|1] ""  VSA
 SG_ SRS_MID_REAR_1 : 9|1@0+ (1,0) [0|1] ""  VSA
 SG_ SRS_MID_SIDE_1 : 10|1@0+ (1,0) [0|1] ""  VSA
 SG_ SRS_MID_FRONT_1 : 11|1@0+ (1,0) [0|1] ""  VSA
 SG_ SRS_HI_CDS_1 : 12|1@0+ (1,0) [0|1] ""  VSA
 SG_ SRS_SIDEPTT_1 : 14|1@0+ (1,0) [0|1] ""  VSA
 SG_ SRS_INDICATOR_1 : 15|1@0+ (1,0) [0|1] ""  VSA
 SG_ SRS_REPROGRAMING_1 : 0|1@0+ (1,0) [0|1] ""  VSA
 SG_ SRS_FAILURE_1 : 1|1@0+ (1,0) [0|1] ""  VSA
 SG_ SRS_AIRBAG_DEPLOY_1 : 3|1@0+ (1,0) [0|1] ""  VSA
 SG_ SRS_CDS_ROLLOVER_1 : 4|1@0+ (1,0) [0|1] ""  VSA
 SG_ SRS_CHECKSUM_039_1 : 19|4@0+ (1,0) [0|15] ""  VSA
 SG_ SRS_ALIVE_COUNTER_039_1 : 21|2@0+ (1,0) [0|3] ""  VSA
 SG_ SRS_CDS_REAR_1 : 5|1@0+ (1,0) [0|1] ""  VSA
 SG_ SRS_CDS_SIDE_1 : 6|1@0+ (1,0) [0|1] ""  VSA
 SG_ SRS_CDS_FRONT_1 : 7|1@0+ (1,0) [0|1] ""  VSA

BO_ 773 SRS_305_CH1: 7 SRS
 SG_ SRS_CHECKSUM_305_1 : 51|4@0+ (1,0) [0|15] ""  VSA
 SG_ SRS_ALIVE_COUNTER_305_1 : 53|2@0+ (1,0) [0|3] ""  VSA
 SG_ SRS_DR_BELT_STATUS_1 : 13|2@0+ (1,0) [0|3] ""  VSA
 SG_ SRS_DR_BELT_1 : 7|1@0+ (1,0) [0|1] ""  VSA

BO_ 320 ENG_140_CH1: 8 ENG
 SG_ ENG_REQUEST_EPB_ACT : 6|1@0+ (1,0) [0|1] ""  VSA
 SG_ ENG_DEC_NSS_BHOLD_1 : 7|1@0+ (1,0) [0|1] ""  VSA,SMART,METER,EPS
 SG_ ENG_CHECKSUM_140_1 : 59|4@0+ (1,0) [0|15] ""  VSA,SMART,METER,EPS
 SG_ ENG_ALIVE_COUNTER_140_1 : 61|2@0+ (1,0) [0|3] ""  VSA,SMART,METER,EPS

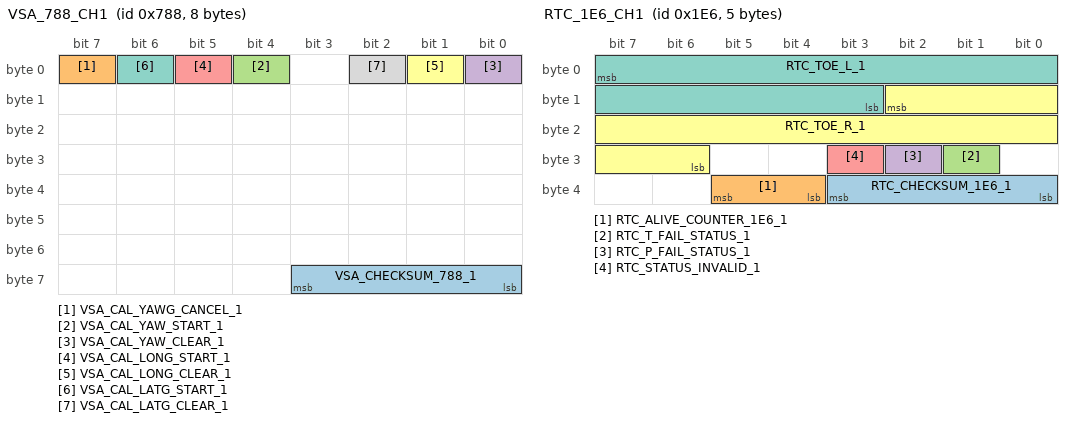
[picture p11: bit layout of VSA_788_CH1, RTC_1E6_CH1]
BO_ 1928 VSA_788_CH1: 8 VSA
 SG_ VSA_CHECKSUM_788_1 : 59|4@0+ (1,0) [0|15] "" Vector__XXX
 SG_ VSA_CAL_YAWG_CANCEL_1 : 7|1@0+ (1,0) [0|1] "" Vector__XXX
 SG_ VSA_CAL_YAW_START_1 : 4|1@0+ (1,0) [0|1] "" Vector__XXX
 SG_ VSA_CAL_YAW_CLEAR_1 : 0|1@0+ (1,0) [0|1] "" Vector__XXX
 SG_ VSA_CAL_LONG_START_1 : 5|1@0+ (1,0) [0|1] "" Vector__XXX
 SG_ VSA_CAL_LONG_CLEAR_1 : 1|1@0+ (1,0) [0|1] "" Vector__XXX
 SG_ VSA_CAL_LATG_START_1 : 6|1@0+ (1,0) [0|1] ""  SRS
 SG_ VSA_CAL_LATG_CLEAR_1 : 2|1@0+ (1,0) [0|1] "" Vector__XXX

BO_ 148 SRS_094_CH1: 8 SRS
 SG_ SRS_STATE_MAC_KEY_1 : 43|1@0+ (1,0) [0|1] "" Vector__XXX
 SG_ SRS_POST_COLLISION_BRK_FAILURE_1 : 40|1@0+ (1,0) [0|1] ""  VSA
 SG_ SRS_POST_COLLISION_BRK_1 : 42|2@0+ (1,0) [0|3] ""  VSA
 SG_ SRS_SENSOR_STATE_IG_1 : 49|1@0+ (1,0) [0|1] ""  VSA,EPS,CVT
 SG_ SRS_SENSOR_START_UP_1 : 63|1@0+ (1,0) [0|1] ""  VSA,SS30,EPS,CVT
 SG_ SRS_SENSOR_ERR_MC_1 : 48|1@0+ (1,0) [0|1] ""  VSA,EPS,CVT
 SG_ SRS_YAW_1_1 : 7|10@0+ (0.244140625,-125) [-125|124.75585938] "deg/sec"  VSA,SS30,EPS
 SG_ SRS_T_ERR_YAW1_1 : 47|1@0+ (1,0) [0|1] ""  VSA,EPS
 SG_ SRS_T_ERR_LON_G_1 : 44|1@0+ (1,0) [0|1] ""  VSA,CVT
 SG_ SRS_T_ERR_LAT_G_1 : 45|1@0+ (1,0) [0|1] ""  VSA,EPS
 SG_ SRS_T_ERR_DEGC_1 : 46|1@0+ (1,0) [0|1] ""  VSA
 SG_ SRS_P_ERR_YAW1_1 : 55|1@0+ (1,0) [0|1] ""  VSA,EPS
 SG_ SRS_P_ERR_LON_G_1 : 52|1@0+ (1,0) [0|1] ""  VSA,CVT
 SG_ SRS_P_ERR_LAT_G_1 : 53|1@0+ (1,0) [0|1] ""  VSA,EPS
 SG_ SRS_P_ERR_DEGC_1 : 54|1@0+ (1,0) [0|1] ""  VSA
 SG_ SRS_LON_G_1 : 25|10@0+ (0.047851563,-24.5) [-24.5|24.452148949] "m/sec^2"  VSA,CVT
 SG_ SRS_LAT_G_1 : 19|10@0+ (0.047851563,-24.5) [-24.5|24.452148949] "m/sec^2"  VSA,SS30,EPS
 SG_ SRS_DEGC_1 : 13|8@0+ (1,-103) [-103|152] ""  VSA
 SG_ SRS_CAL_YAW_1 : 62|1@0+ (1,0) [0|1] ""  VSA
 SG_ SRS_CAL_LON_G_1 : 50|1@0+ (1,0) [0|1] ""  VSA
 SG_ SRS_CAL_LAT_G_1 : 51|1@0+ (1,0) [0|1] ""  VSA
 SG_ SRS_CHECKSUM_094_1 : 59|4@0+ (1,0) [0|15] ""  VSA,SS30,FCM,EPS,CVT
 SG_ SRS_ALIVE_COUNTER_094_1 : 61|2@0+ (1,0) [0|3] ""  VSA,SS30,FCM,EPS,CVT

BO_ 486 RTC_1E6_CH1: 5 RTC
 SG_ RTC_CHECKSUM_1E6_1 : 35|4@0+ (1,0) [0|15] ""  VSA
 SG_ RTC_ALIVE_COUNTER_1E6_1 : 37|2@0+ (1,0) [0|3] ""  VSA
 SG_ RTC_T_FAIL_STATUS_1 : 25|1@0+ (1,0) [0|1] ""  VSA
 SG_ RTC_P_FAIL_STATUS_1 : 26|1@0+ (1,0) [0|1] ""  VSA
 SG_ RTC_STATUS_INVALID_1 : 27|1@0+ (1,0) [0|1] ""  VSA
 SG_ RTC_TOE_R_1 : 10|13@0- (0.0015,0) [-6.144|6.1425] "deg"  VSA
 SG_ RTC_TOE_L_1 : 7|13@0- (0.0015,0) [-6.144|6.1425] "deg"  VSA

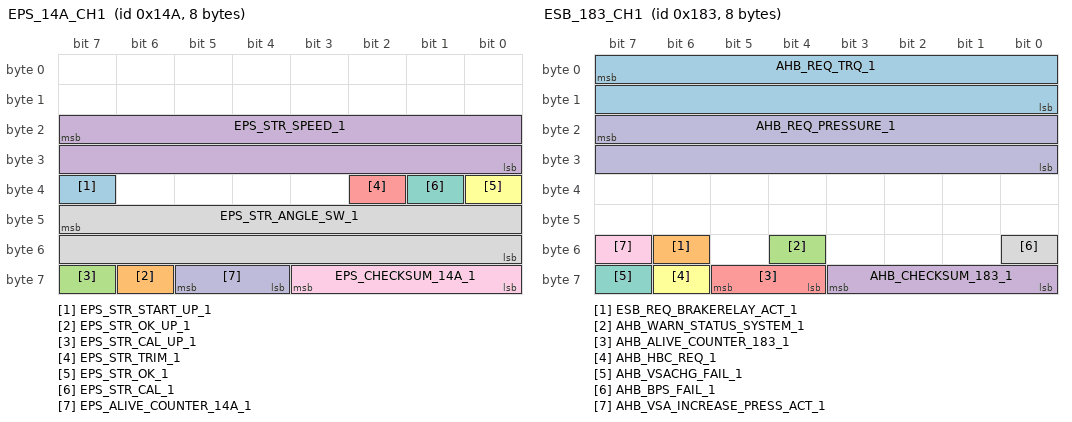
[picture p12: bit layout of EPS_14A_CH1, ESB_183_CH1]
BO_ 330 EPS_14A_CH1: 8 EPS
 SG_ EPS_STR_START_UP_1 : 39|1@0+ (1,0) [0|1] ""  VSA
 SG_ EPS_STR_OK_UP_1 : 62|1@0+ (1,0) [0|1] ""  VSA
 SG_ EPS_STR_CAL_UP_1 : 63|1@0+ (1,0) [0|1] ""  VSA
 SG_ EPS_STR_SPEED_1 : 23|16@0- (1,0) [-2000|2000] "deg/sec"  VSA
 SG_ EPS_STR_TRIM_1 : 34|1@0+ (1,0) [0|1] ""  VSA,SS30,SRS,METER,EPS
 SG_ EPS_STR_OK_1 : 32|1@0+ (1,0) [0|1] ""  VSA,SS30,SRS,METER,EPS
 SG_ EPS_STR_CAL_1 : 33|1@0+ (1,0) [0|1] ""  VSA,SS30,METER,EPS
 SG_ EPS_STR_ANGLE_SW_1 : 47|16@0- (0.1,0) [-3276.8|3276.7] "deg"  VSA,SS30,SRS,METER,EPS
 SG_ EPS_CHECKSUM_14A_1 : 59|4@0+ (1,0) [0|15] ""  VSA,SS30,SRS,METER,FCM,EPS
 SG_ EPS_ALIVE_COUNTER_14A_1 : 61|2@0+ (1,0) [0|3] ""  VSA,SS30,SRS,METER,FCM,EPS

BO_ 441 VSA_1B9_CH1: 5 VSA
 SG_ VSA_CHECKSUM_1B9_1 : 35|4@0+ (1,0) [0|15] "" Vector__XXX
 SG_ VSA_ALIVE_COUNTER_1B9_1 : 37|2@0+ (1,0) [0|3] "" Vector__XXX
 SG_ VSA_ABS_RR_WHEEL_PULSE_CNT_1B9_1 : 31|8@0+ (1,0) [0|255] "" Vector__XXX
 SG_ VSA_ABS_RL_WHEEL_PULSE_CNT_1B9_1 : 23|8@0+ (1,0) [0|255] "" Vector__XXX
 SG_ VSA_ABS_FR_WHEEL_PULSE_CNT_1B9_1 : 15|8@0+ (1,0) [0|255] "" Vector__XXX
 SG_ VSA_ABS_FL_WHEEL_PULSE_CNT_1B9_1 : 7|8@0+ (1,0) [0|255] ""  ABS

BO_ 795 VSA_31B_CH1: 8 VSA
 SG_ VSA_SYSTEM_STATUS_1 : 42|1@0+ (1,0) [0|0] "" Vector__XXX
 SG_ VSA_MID_WARN_STATUS_DWS_INIT_1 : 32|1@0+ (1,0) [0|1] "" Vector__XXX
 SG_ VSA_REJECT_OFF_SW_OPTN_MID_1 : 63|1@0+ (1,0) [0|1] "" Vector__XXX
 SG_ VSA_DWS_AUTOJUDGE_1 : 36|1@0+ (1,0) [0|1] "" Vector__XXX
 SG_ VSA_MID_REQ_HDC_SW_STATUS_1 : 20|2@0+ (1,0) [0|0] "" Vector__XXX
 SG_ VSA_HDC_CONTROL_STATUS_1 : 22|2@0+ (1,0) [0|0] "" Vector__XXX
 SG_ VSA_HDC_SPEED_UNIT_1 : 23|1@0+ (1,0) [0|0] "" Vector__XXX
 SG_ VSA_HDC_DISPLAY_SPEED_TARGET_1 : 12|5@0+ (1,0) [0|0] "kph/mph" Vector__XXX
 SG_ VSA_MID_REQ_MAINTENANCE_MODE_1 : 62|1@0+ (1,0) [0|1] "" Vector__XXX
 SG_ VSA_MID_HDC_OP_GUIDE_1 : 18|3@0+ (1,0) [0|7] "" Vector__XXX
 SG_ VSA_MID_REQUEST_IDS_1 : 47|4@0+ (1,0) [0|15] "" Vector__XXX
 SG_ VSA_MID_REQUEST_VSA_OFF_1 : 37|1@0+ (1,0) [0|1] "" Vector__XXX
 SG_ VSA_MID_REQUEST_TCS_OFF_1 : 38|1@0+ (1,0) [0|1] "" Vector__XXX
 SG_ VSA_MID_REQ_EPB_MISOP_GUIDE_1 : 35|2@0+ (1,0) [0|3] "" Vector__XXX
 SG_ VSA_MID_LMP_STATS_OPRTE_BHOLD_1 : 26|1@0+ (1,0) [0|1] "" Vector__XXX
 SG_ VSA_MID_LAMP_STATUS_HDC_OFF_1 : 29|1@0+ (1,0) [0|1] "" Vector__XXX
 SG_ VSA_WARN_STATUS_HDC_1 : 13|1@0+ (1,0) [0|1] "" Vector__XXX
 SG_ VSA_MID_WARN_STATUS_TSA_1 : 2|1@0+ (1,0) [0|1] "" Vector__XXX
 SG_ VSA_MID_WARN_STATUS_BRAKESYSTM_1 : 4|1@0+ (1,0) [0|1] "" Vector__XXX
 SG_ VSA_CHECKSUM_31B_1 : 59|4@0+ (1,0) [0|15] "" Vector__XXX
 SG_ VSA_ALIVE_COUNTER_31B_1 : 61|2@0+ (1,0) [0|3] "" Vector__XXX
 SG_ VSA_WARN_STATUS_HSA_31B_1 : 3|1@0+ (1,0) [0|1] "" Vector__XXX
 SG_ VSA_MID_WARN_STATUS_BRAKE_1 : 5|1@0+ (1,0) [0|1] "" Vector__XXX
 SG_ VSA_MID_WARN_STATUS_ABS_1 : 7|1@0+ (1,0) [0|1] "" Vector__XXX
 SG_ VSA_MID_REQUEST_VSA_31B_1 : 6|1@0+ (1,0) [0|1] "" Vector__XXX
 SG_ VSA_MID_LAMP_STATUS_VSA_OFF_1 : 39|1@0+ (1,0) [0|1] ""  ACC
 SG_ VSA_MID_REQ_BHOLD_STANDBY_1 : 31|1@0+ (1,0) [0|0] "" Vector__XXX
 SG_ VSA_MID_REQ_BHOLD_EPB_OP_INFO_1 : 30|1@0+ (1,0) [0|0] "" Vector__XXX
 SG_ VSA_MID_REQ_BHOLD_MISOP_GUIDE_1 : 28|2@0+ (1,0) [0|3] "" Vector__XXX
 SG_ VSA_MID_REQ_BHOLD_APPLY_BRAKE_1 : 15|1@0+ (1,0) [0|0] "" Vector__XXX
 SG_ VSA_WARN_STATUS_BHOLD_1 : 14|1@0+ (1,0) [0|0] "" Vector__XXX
 SG_ VSA_MID_WARN_STATUS_DWS_1 : 1|1@0+ (1,0) [0|0] "" Vector__XXX
 SG_ VSA_MID_WARN_STATUS_PUNCTURE_1 : 0|1@0+ (1,0) [0|0] "" Vector__XXX

BO_ 387 ESB_183_CH1: 8 E4WD
 SG_ AHB_REQ_TRQ_1 : 7|16@0+ (0.1,0) [0|6553.5] "Nm"  VSA
 SG_ ESB_REQ_BRAKERELAY_ACT_1 : 54|1@0+ (1,0) [0|0] ""  VSA
 SG_ AHB_WARN_STATUS_SYSTEM_1 : 52|1@0+ (1,0) [0|0] ""  VSA
 SG_ AHB_CHECKSUM_183_1 : 59|4@0+ (1,0) [0|15] ""  VSA
 SG_ AHB_ALIVE_COUNTER_183_1 : 61|2@0+ (1,0) [0|3] ""  VSA
 SG_ AHB_HBC_REQ_1 : 62|1@0+ (1,0) [0|1] ""  VSA
 SG_ AHB_VSACHG_FAIL_1 : 63|1@0+ (1,0) [0|1] ""  VSA
 SG_ AHB_BPS_FAIL_1 : 48|1@0+ (1,0) [0|1] ""  VSA
 SG_ AHB_VSA_INCREASE_PRESS_ACT_1 : 55|1@0+ (1,0) [0|1] ""  VSA
 SG_ AHB_REQ_PRESSURE_1 : 23|16@0- (1,0) [-32768|32767] "kpa"  VSA

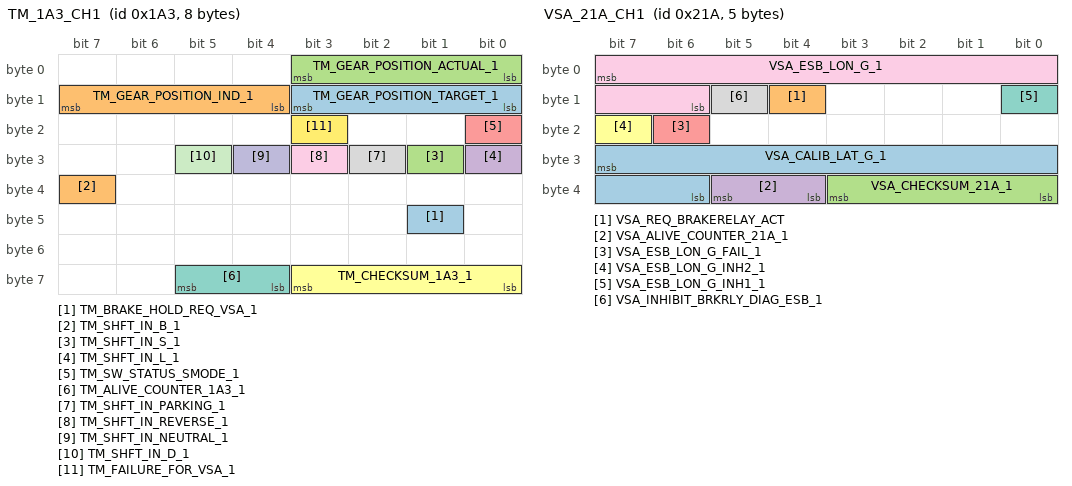
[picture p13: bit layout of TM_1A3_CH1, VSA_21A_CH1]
BO_ 419 TM_1A3_CH1: 8 TM
 SG_ TM_BRAKE_HOLD_REQ_VSA_1 : 41|1@0+ (1,0) [0|1] ""  VSA
 SG_ TM_SHFT_IN_B_1 : 39|1@0+ (1,0) [0|0] ""  VSA
 SG_ TM_SHFT_IN_S_1 : 25|1@0+ (1,0) [0|0] ""  VSA
 SG_ TM_SHFT_IN_L_1 : 24|1@0+ (1,0) [0|1] ""  VSA
 SG_ TM_SW_STATUS_SMODE_1 : 16|1@0+ (1,0) [0|1] ""  VSA
 SG_ TM_CHECKSUM_1A3_1 : 59|4@0+ (1,0) [0|15] ""  VSA
 SG_ TM_ALIVE_COUNTER_1A3_1 : 61|2@0+ (1,0) [0|3] ""  VSA
 SG_ TM_SHFT_IN_PARKING_1 : 26|1@0+ (1,0) [0|1] ""  VSA
 SG_ TM_SHFT_IN_REVERSE_1 : 27|1@0+ (1,0) [0|1] ""  VSA
 SG_ TM_SHFT_IN_NEUTRAL_1 : 28|1@0+ (1,0) [0|1] ""  VSA
 SG_ TM_SHFT_IN_D_1 : 29|1@0+ (1,0) [0|1] ""  VSA
 SG_ TM_FAILURE_FOR_VSA_1 : 19|1@0+ (1,0) [0|1] ""  VSA
 SG_ TM_GEAR_POSITION_TARGET_1 : 11|4@0+ (1,0) [0|15] ""  VSA
 SG_ TM_GEAR_POSITION_IND_1 : 15|4@0+ (1,0) [0|15] ""  VSA
 SG_ TM_GEAR_POSITION_ACTUAL_1 : 3|4@0+ (1,0) [0|15] ""  VSA

BO_ 538 VSA_21A_CH1: 5 VSA
 SG_ VSA_CALIB_LAT_G_1 : 31|10@0+ (0.0478,-24.5) [-24.5|24.3994] "m/s^2" Vector__XXX
 SG_ VSA_REQ_BRAKERELAY_ACT : 12|1@0+ (1,0) [0|1] "" Vector__XXX
 SG_ VSA_CHECKSUM_21A_1 : 35|4@0+ (1,0) [0|15] "" Vector__XXX
 SG_ VSA_ALIVE_COUNTER_21A_1 : 37|2@0+ (1,0) [0|3] "" Vector__XXX
 SG_ VSA_ESB_LON_G_FAIL_1 : 22|1@0+ (1,0) [0|1] "" Vector__XXX
 SG_ VSA_ESB_LON_G_INH2_1 : 23|1@0+ (1,0) [0|1] "" Vector__XXX
 SG_ VSA_ESB_LON_G_INH1_1 : 8|1@0+ (1,0) [0|1] "" Vector__XXX
 SG_ VSA_INHIBIT_BRKRLY_DIAG_ESB_1 : 13|1@0+ (1,0) [0|1] "" Vector__XXX
 SG_ VSA_ESB_LON_G_1 : 7|10@0+ (0.047851563,-24.5) [-24.5|24.452148949] ""  ESB

BO_ 470 ENG_1D6_CH1: 2 ENG
 SG_ ENG_IS_BRK_PRESSURE_1D6_1 : 7|8@0+ (10,0) [0|2550] "KPa"  VSA
 SG_ ENG_ALIVE_COUNTER_1D6_1 : 13|2@0+ (1,0) [0|3] ""  VSA
 SG_ ENG_CHECKSUM_1D6_1 : 11|4@0+ (1,0) [0|15] ""  VSA
 SG_ ENG_ISAB_REQUEST_1D6_1 : 15|1@0+ (1,0) [0|1] ""  VSA

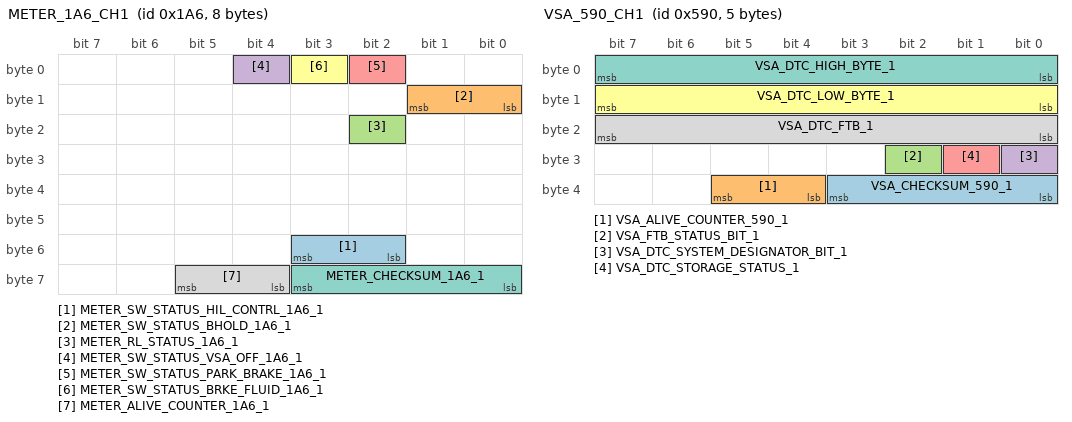
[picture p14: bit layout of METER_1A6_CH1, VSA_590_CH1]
BO_ 422 METER_1A6_CH1: 8 METER
 SG_ METER_SW_STATUS_HIL_CONTRL_1A6_1 : 51|2@0+ (1,0) [0|3] ""  VSA
 SG_ METER_SW_STATUS_BHOLD_1A6_1 : 9|2@0+ (1,0) [0|3] ""  VSA
 SG_ METER_RL_STATUS_1A6_1 : 18|1@0+ (1,0) [0|1] ""  VSA
 SG_ METER_SW_STATUS_VSA_OFF_1A6_1 : 4|1@0+ (1,0) [0|1] ""  VSA
 SG_ METER_SW_STATUS_PARK_BRAKE_1A6_1 : 2|1@0+ (1,0) [0|1] ""  VSA
 SG_ METER_SW_STATUS_BRKE_FLUID_1A6_1 : 3|1@0+ (1,0) [0|1] ""  VSA
 SG_ METER_CHECKSUM_1A6_1 : 59|4@0+ (1,0) [0|15] ""  VSA
 SG_ METER_ALIVE_COUNTER_1A6_1 : 61|2@0+ (1,0) [0|3] ""  VSA

BO_ 884 METER_374_CH1: 8 METER
 SG_ METER_STRG_SW_PUSH_FOR_VSA_OFF_1 : 8|1@0+ (1,0) [0|0] "" Vector__XXX
 SG_ METER_CHECKSUM_374_1 : 59|4@0+ (1,0) [0|15] ""  VSA
 SG_ METER_ALIVE_COUNTER_374_1 : 61|2@0+ (1,0) [0|3] ""  VSA
 SG_ METER_OUTTEMP_1 : 7|8@0+ (1,-40) [-40|215] ""  VSA

BO_ 1424 VSA_590_CH1: 5 VSA
 SG_ VSA_CHECKSUM_590_1 : 35|4@0+ (1,0) [0|15] "" Vector__XXX
 SG_ VSA_ALIVE_COUNTER_590_1 : 37|2@0+ (1,0) [0|3] "" Vector__XXX
 SG_ VSA_FTB_STATUS_BIT_1 : 26|1@0+ (1,0) [0|1] "" Vector__XXX
 SG_ VSA_DTC_SYSTEM_DESIGNATOR_BIT_1 : 24|1@0+ (1,0) [0|1] "" Vector__XXX
 SG_ VSA_DTC_STORAGE_STATUS_1 : 25|1@0+ (1,0) [0|1] "" Vector__XXX
 SG_ VSA_DTC_LOW_BYTE_1 : 15|8@0+ (1,0) [0|255] "" Vector__XXX
 SG_ VSA_DTC_HIGH_BYTE_1 : 7|8@0+ (1,0) [0|255] ""  NAVI
 SG_ VSA_DTC_FTB_1 : 23|8@0+ (1,0) [0|255] "" Vector__XXX

BO_ 661 METER_295_CH1: 4 METER
 SG_ METER_SW_STATUS_HIL_CONTRL_295_1 : 31|2@0+ (1,0) [0|3] ""  VSA
 SG_ METER_DWS_INIT_REQ_SW_1 : 12|1@0+ (1,0) [0|1] ""  VSA
 SG_ METER_CHECKSUM_295_1 : 27|4@0+ (1,0) [0|15] ""  VSA
 SG_ METER_ALIVE_COUNTER_295_1 : 29|2@0+ (1,0) [0|3] ""  VSA
 SG_ METER_DWS_INIT_REQ_1 : 13|1@0+ (1,0) [0|1] ""  VSA

BO_ 660 METER_294_CH1: 8 METER
 SG_ METER_CHECKSUM_294_1 : 59|4@0+ (1,0) [0|15] ""  VSA
 SG_ METER_ALIVE_COUNTER_294_1 : 61|2@0+ (1,0) [0|3] ""  VSA
 SG_ METER_ODO_DATA_1 : 31|24@0+ (1,0) [0|16777215] "km"  VSA

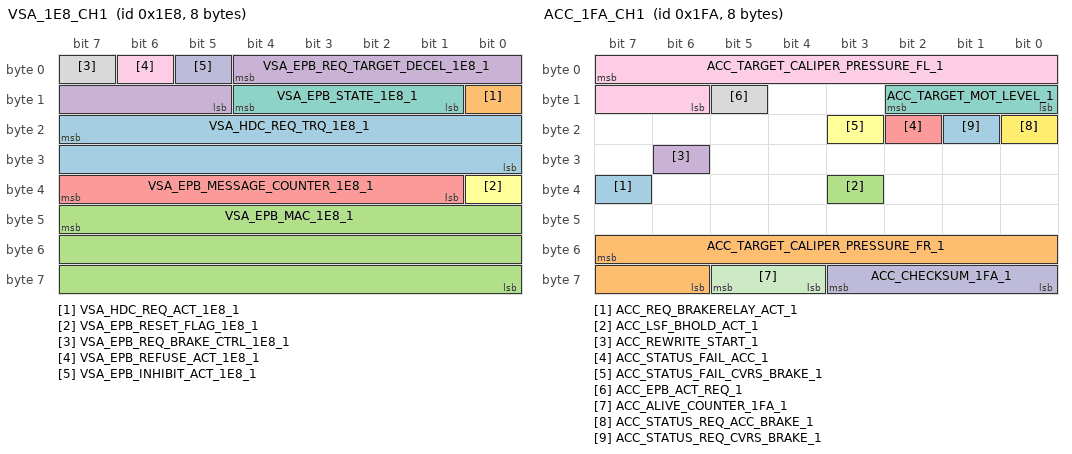
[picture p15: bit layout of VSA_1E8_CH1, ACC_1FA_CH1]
BO_ 488 VSA_1E8_CH1: 8 VSA
 SG_ VSA_HDC_REQ_TRQ_1E8_1 : 23|16@0+ (1,0) [0|65535] "" Vector__XXX
 SG_ VSA_HDC_REQ_ACT_1E8_1 : 8|1@0+ (1,0) [0|1] "" Vector__XXX
 SG_ VSA_EPB_MAC_1E8_1 : 47|24@0+ (1,0) [0|16777215] "" Vector__XXX
 SG_ VSA_EPB_REQ_TARGET_DECEL_1E8_1 : 4|8@0+ (1,0) [0|255] "" Vector__XXX
 SG_ VSA_EPB_MESSAGE_COUNTER_1E8_1 : 39|7@0+ (1,0) [0|127] "" Vector__XXX
 SG_ VSA_EPB_RESET_FLAG_1E8_1 : 32|1@0+ (1,0) [0|1] "" Vector__XXX
 SG_ VSA_EPB_STATE_1E8_1 : 12|4@0+ (1,0) [0|15] "" Vector__XXX
 SG_ VSA_EPB_REQ_BRAKE_CTRL_1E8_1 : 7|1@0+ (1,0) [0|1] "" Vector__XXX
 SG_ VSA_EPB_REFUSE_ACT_1E8_1 : 6|1@0+ (1,0) [0|1] "" Vector__XXX
 SG_ VSA_EPB_INHIBIT_ACT_1E8_1 : 5|1@0+ (1,0) [0|1] "" Vector__XXX

BO_ 426 VSA_1AA_CH1: 8 VSA
 SG_ VSA_IG_ON_1 : 55|1@0+ (1,0) [0|1] "" Vector__XXX
 SG_ VSA_IDS_INHIBIT_DISABLED_STATE_1 : 44|1@0+ (1,0) [0|1] "" Vector__XXX
 SG_ VSA_IDS_INHIBIT_ACT_1 : 45|1@0+ (1,0) [0|1] "" Vector__XXX
 SG_ VSA_EBB_FAILURE_FOR_IS_1 : 41|1@0+ (1,0) [0|1] "" Vector__XXX
 SG_ VSA_HAC_CUT_REQ_1 : 32|1@0+ (1,0) [0|1] "" Vector__XXX
 SG_ VSA_HBB_IS_REFUSE_REQ_1 : 33|1@0+ (1,0) [0|1] "" Vector__XXX
 SG_ VSA_LOW_VAC_IS_SHFT_INHBIT_REQ_1 : 34|1@0+ (1,0) [0|1] "" Vector__XXX
 SG_ VSA_HBB_IS_SHIFT_INHIBIT_REQ_1 : 35|1@0+ (1,0) [0|1] "" Vector__XXX
 SG_ VSA_MNTMODE_STATUS_1 : 24|1@0+ (1,0) [0|1] "" Vector__XXX
 SG_ VSA_REVERSE_SWITCH_FAIL_1 : 25|1@0+ (1,0) [0|1] "" Vector__XXX
 SG_ VSA_SHFT_IN_REVERSE_1 : 26|1@0+ (1,0) [0|1] "" Vector__XXX
 SG_ VSA_ECD_ACT_1 : 27|1@0+ (1,0) [0|1] "" Vector__XXX
 SG_ VSA_FAIL_FOR_EPB_1 : 28|1@0+ (1,0) [0|1] "" Vector__XXX
 SG_ VSA_REQUEST_EPB_ACT_1 : 29|1@0+ (1,0) [0|1] "" Vector__XXX
 SG_ VSA_EPB_INHIBIT_BRAKE_1 : 30|1@0+ (1,0) [0|1] "" Vector__XXX
 SG_ VSA_EPB_REFUSE_BRAKE_1 : 31|1@0+ (1,0) [0|1] "" Vector__XXX
 SG_ VSA_TM_SUPPORT_BRKE_REFUSE_1AA_1 : 40|1@0+ (1,0) [0|1] "" Vector__XXX
 SG_ VSA_IS_RESTART_INHIBIT_REQ_1AA_1 : 46|1@0+ (1,0) [0|1] ""  EPB
 SG_ VSA_ISAB_ACT_1AA_1 : 42|1@0+ (1,0) [0|1] "" Vector__XXX
 SG_ VSA_BTCS_ACT_1AA_1 : 63|1@0+ (1,0) [0|0] "" Vector__XXX
 SG_ VSA_ISAB_ENABLE_1AA_1 : 43|1@0+ (1,0) [0|1] "" Vector__XXX
 SG_ VSA_IS_SHFT_INHBIT_REQUEST_1AA_1 : 47|1@0+ (1,0) [0|1] "" Vector__XXX
 SG_ VSA_SHIFT_REQ_1AA_1 : 19|2@0+ (1,0) [0|3] "" Vector__XXX
 SG_ VSA_TRQ_DOWN_REQ_FUEL_CUT_1AA_1 : 23|4@0+ (1,0) [0|15] "" Vector__XXX
 SG_ VSA_ALIVE_COUNTER_1AA_1 : 61|2@0+ (1,0) [0|3] "" Vector__XXX
 SG_ VSA_CHECKSUM_1AA_1 : 59|4@0+ (1,0) [0|15] "" Vector__XXX
 SG_ VSA_REQ_MSR_PLUS_TRQ_1AA_1 : 62|1@0+ (1,0) [0|1] "" Vector__XXX
 SG_ VSA_TRQ_CONTROL_MODE_1AA_1 : 17|2@0+ (1,0) [0|3] "" Vector__XXX
 SG_ VSA_REQ_TRQ_1AA_1 : 7|16@0- (0.2,0) [-6553.6|6553.4] "Nm" Vector__XXX

BO_ 506 ACC_1FA_CH1: 8 ACC
 SG_ ACC_REQ_BRAKERELAY_ACT_1 : 39|1@0+ (1,0) [0|1] ""  VSA
 SG_ ACC_TARGET_CALIPER_PRESSURE_FR_1 : 55|10@0+ (12.5,0) [0|12787.5] "kPa"  VSA
 SG_ ACC_LSF_BHOLD_ACT_1 : 35|1@0+ (1,0) [0|1] ""  VSA
 SG_ ACC_REWRITE_START_1 : 30|1@0+ (1,0) [0|1] ""  VSA
 SG_ ACC_STATUS_FAIL_ACC_1 : 18|1@0+ (1,0) [0|1] ""  VSA
 SG_ ACC_STATUS_FAIL_CVRS_BRAKE_1 : 19|1@0+ (1,0) [0|1] ""  VSA
 SG_ ACC_TARGET_MOT_LEVEL_1 : 10|3@0+ (1,0) [0|7] ""  VSA
 SG_ ACC_EPB_ACT_REQ_1 : 13|1@0+ (1,0) [0|1] ""  VSA
 SG_ ACC_TARGET_CALIPER_PRESSURE_FL_1 : 7|10@0+ (12.5,0) [0|12787.5] "kPa"  VSA
 SG_ ACC_CHECKSUM_1FA_1 : 59|4@0+ (1,0) [0|15] ""  VSA
 SG_ ACC_ALIVE_COUNTER_1FA_1 : 61|2@0+ (1,0) [0|3] ""  VSA
 SG_ ACC_STATUS_REQ_ACC_BRAKE_1 : 16|1@0+ (1,0) [0|1] ""  VSA
 SG_ ACC_STATUS_REQ_CVRS_BRAKE_1 : 17|1@0+ (1,0) [0|1] ""  VSA

BO_ 316 ENG_13C_CH1: 8 ENG
 SG_ ENG_IG1_10V_STATUS_1 : 52|1@0+ (1,0) [0|1] ""  VSA
 SG_ ENG_CLUTCH_SW_SIL_1 : 51|1@0+ (1,0) [0|1] ""  VSA
 SG_ ENG_BRK_ACCELE_PEDAL_ON_13C_1 : 44|1@0+ (1,0) [0|1] ""  VSA
 SG_ ENG_CAS_REQ_13C_1 : 53|1@0+ (1,0) [0|0] ""  VSA
 SG_ ENG_NEUTRAL_SENSOR_FAIL_13C_1 : 62|1@0+ (1,0) [0|1] ""  VSA
 SG_ ENG_SHFT_IN_NEUTRAL_13C_1 : 48|1@0+ (1,0) [0|1] ""  VSA
 SG_ ENG_SHFT_IN_REVERSE_13C_1 : 49|1@0+ (1,0) [0|1] ""  VSA
 SG_ ENG_CLUTCH_SW_CC_13C_1 : 50|1@0+ (1,0) [0|1] ""  VSA
 SG_ ENG_VSA_ACK1_13C_1 : 43|4@0+ (1,0) [0|15] ""  VSA
 SG_ ENG_VSA_PERMIT_PLUS_TRQ_13C_1 : 45|1@0+ (1,0) [0|1] ""  VSA
 SG_ ENG_ALIVE_COUNTER_13C_1 : 61|2@0+ (1,0) [0|3] ""  VSA
 SG_ ENG_CHECKSUM_13C_1 : 59|4@0+ (1,0) [0|15] ""  VSA
 SG_ ENG_RECEIVE_ERROR_1AA_1 : 63|1@0+ (1,0) [0|1] ""  VSA
 SG_ ENG_VSA_INHIBIT_VSA_CONTRL_13C_1 : 46|1@0+ (1,0) [0|1] ""  VSA
 SG_ ENG_VSA_REFUSED_VSA_CONTRL_13C_1 : 47|1@0+ (1,0) [0|1] ""  VSA
 SG_ ENG_SMART_ACCELE_PEDAL_POS_13C_1 : 39|8@0+ (0.39215686275,0) [0|100] "%"  VSA
 SG_ ENG_DRIVER_REQ_TRQ_13C_1 : 23|16@0- (0.2,0) [-6553.6|6553.4] "Nm"  VSA
 SG_ ENG_ENG_TRQ_13C_1 : 7|16@0- (0.2,0) [-6553.6|6553.4] "Nm"  VSA

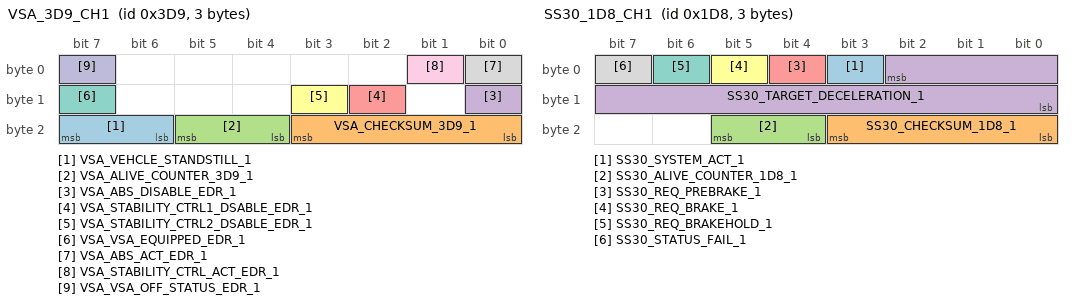
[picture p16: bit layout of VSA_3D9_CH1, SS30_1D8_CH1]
BO_ 985 VSA_3D9_CH1: 3 VSA
 SG_ VSA_VEHCLE_STANDSTILL_1 : 23|2@0+ (1,0) [0|3] "" Vector__XXX
 SG_ VSA_CHECKSUM_3D9_1 : 19|4@0+ (1,0) [0|15] ""  SRS
 SG_ VSA_ALIVE_COUNTER_3D9_1 : 21|2@0+ (1,0) [0|3] ""  SRS
 SG_ VSA_ABS_DISABLE_EDR_1 : 8|1@0+ (1,0) [0|1] ""  SRS
 SG_ VSA_STABILITY_CTRL1_DSABLE_EDR_1 : 10|1@0+ (1,0) [0|1] ""  SRS
 SG_ VSA_STABILITY_CTRL2_DSABLE_EDR_1 : 11|1@0+ (1,0) [0|1] ""  SRS
 SG_ VSA_VSA_EQUIPPED_EDR_1 : 15|1@0+ (1,0) [0|1] ""  SRS
 SG_ VSA_ABS_ACT_EDR_1 : 0|1@0+ (1,0) [0|1] ""  SRS
 SG_ VSA_STABILITY_CTRL_ACT_EDR_1 : 1|1@0+ (1,0) [0|1] ""  SRS
 SG_ VSA_VSA_OFF_STATUS_EDR_1 : 7|1@0+ (1,0) [0|1] ""  SRS

BO_ 2564550641 HDS_18DBEFF1_CH1: 8 HDS
 SG_ HDS_HDC_CAN_1 : 7|64@0+ (1,0) [0|1.8446744074E+019] ""  VSA,NAVI,METER,ENG,CVT,AHU

BO_ 808 ENG_328_CH1: 8 ENG
 SG_ ENG_CHECKSUM_328_1 : 59|4@0+ (1,0) [0|15] ""  VSA,SMART,METER,EPS
 SG_ ENG_ALIVE_COUNTER_328_1 : 61|2@0+ (1,0) [0|3] ""  VSA,SMART,METER,EPS
 SG_ ENG_STRNNEND_1 : 47|1@0+ (1,0) [0|1] ""  VSA,SMART,METER,EPS

BO_ 804 ENG_324_CH1: 8 ENG
 SG_ ENG_ENG_COOLANT_TEMP_1 : 7|8@0+ (1,-40) [0|0] ""  VSA
 SG_ ENG_EM_TEST_MODE_ENABLE_1 : 62|1@0+ (1,0) [0|1] ""  VSA
 SG_ ENG_CHECKSUM_324_1 : 59|4@0+ (1,0) [0|15] ""  VSA,SS30,SRS,METER,FCM,EPS,ABS
 SG_ ENG_ALIVE_COUNTER_324_1 : 61|2@0+ (1,0) [0|3] ""  VSA,SS30,SRS,METER,FCM,EPS,ABS
 SG_ ENG_SW_STATUS_SCS_1 : 48|1@0+ (1,0) [0|1] ""  VSA,SS30,SRS,METER,EPS,ABS

BO_ 472 SS30_1D8_CH1: 3 SS30
 SG_ SS30_SYSTEM_ACT_1 : 3|1@0+ (1,0) [0|1] ""  VSA
 SG_ SS30_CHECKSUM_1D8_1 : 19|4@0+ (1,0) [0|15] ""  VSA
 SG_ SS30_ALIVE_COUNTER_1D8_1 : 21|2@0+ (1,0) [0|3] ""  VSA
 SG_ SS30_TARGET_DECELERATION_1 : 2|11@0- (0.01,0) [-10.24|10.23] "m/s2"  VSA
 SG_ SS30_REQ_PREBRAKE_1 : 4|1@0+ (1,0) [0|1] ""  VSA
 SG_ SS30_REQ_BRAKE_1 : 5|1@0+ (1,0) [0|1] ""  VSA
 SG_ SS30_REQ_BRAKEHOLD_1 : 6|1@0+ (1,0) [0|1] ""  VSA
 SG_ SS30_STATUS_FAIL_1 : 7|1@0+ (1,0) [0|1] ""  VSA

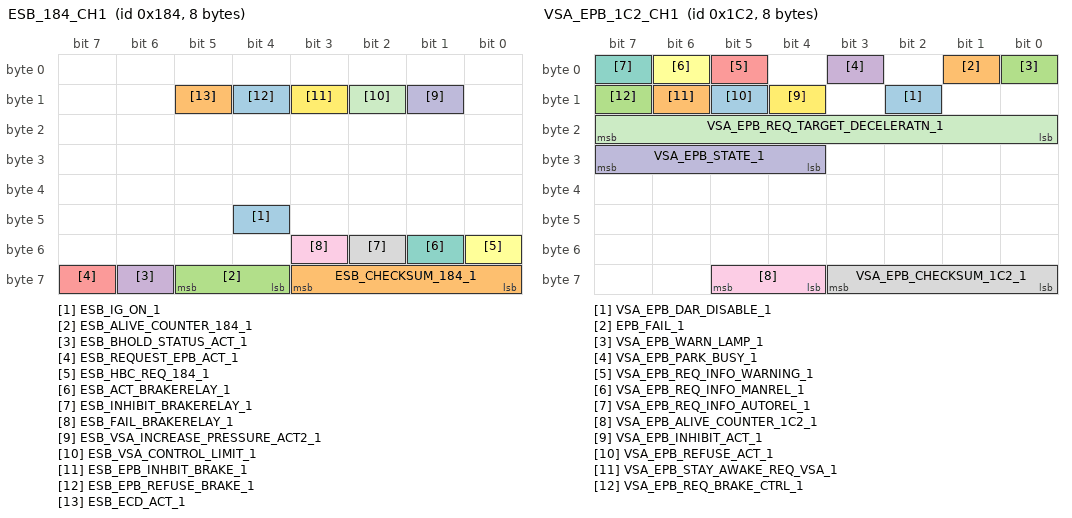
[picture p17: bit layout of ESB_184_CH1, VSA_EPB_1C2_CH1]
BO_ 388 ESB_184_CH1: 8 E4WD
 SG_ ESB_IG_ON_1 : 44|1@0+ (1,0) [0|1] ""  VSA
 SG_ ESB_CHECKSUM_184_1 : 59|4@0+ (1,0) [0|15] ""  VSA
 SG_ ESB_ALIVE_COUNTER_184_1 : 61|2@0+ (1,0) [0|3] ""  VSA
 SG_ ESB_BHOLD_STATUS_ACT_1 : 62|1@0+ (1,0) [0|1] ""  VSA
 SG_ ESB_REQUEST_EPB_ACT_1 : 63|1@0+ (1,0) [0|1] ""  VSA
 SG_ ESB_HBC_REQ_184_1 : 48|1@0+ (1,0) [0|1] ""  VSA
 SG_ ESB_ACT_BRAKERELAY_1 : 49|1@0+ (1,0) [0|1] ""  VSA
 SG_ ESB_INHIBIT_BRAKERELAY_1 : 50|1@0+ (1,0) [0|1] ""  VSA
 SG_ ESB_FAIL_BRAKERELAY_1 : 51|1@0+ (1,0) [0|1] ""  VSA
 SG_ ESB_VSA_INCREASE_PRESSURE_ACT2_1 : 9|1@0+ (1,0) [0|1] ""  VSA
 SG_ ESB_VSA_CONTROL_LIMIT_1 : 10|1@0+ (1,0) [0|1] ""  VSA
 SG_ ESB_EPB_INHBIT_BRAKE_1 : 11|1@0+ (1,0) [0|1] ""  VSA
 SG_ ESB_EPB_REFUSE_BRAKE_1 : 12|1@0+ (1,0) [0|1] ""  VSA
 SG_ ESB_ECD_ACT_1 : 13|1@0+ (1,0) [0|1] ""  VSA

BO_ 450 VSA_EPB_1C2_CH1: 8 VSA
 SG_ VSA_EPB_DAR_DISABLE_1 : 10|1@0+ (1,0) [0|0] "" Vector__XXX
 SG_ EPB_FAIL_1 : 1|1@0+ (1,0) [0|0] "" Vector__XXX
 SG_ VSA_EPB_WARN_LAMP_1 : 0|1@0+ (1,0) [0|1] "" Vector__XXX
 SG_ VSA_EPB_PARK_BUSY_1 : 3|1@0+ (1,0) [0|1] "" Vector__XXX
 SG_ VSA_EPB_REQ_INFO_WARNING_1 : 5|1@0+ (1,0) [0|1] "" Vector__XXX
 SG_ VSA_EPB_REQ_INFO_MANREL_1 : 6|1@0+ (1,0) [0|1] "" Vector__XXX
 SG_ VSA_EPB_REQ_INFO_AUTOREL_1 : 7|1@0+ (1,0) [0|1] "" Vector__XXX
 SG_ VSA_EPB_CHECKSUM_1C2_1 : 59|4@0+ (1,0) [0|15] "" Vector__XXX
 SG_ VSA_EPB_ALIVE_COUNTER_1C2_1 : 61|2@0+ (1,0) [0|3] "" Vector__XXX
 SG_ VSA_EPB_STATE_1 : 31|4@0+ (1,0) [0|15] "" Vector__XXX
 SG_ VSA_EPB_REQ_TARGET_DECELERATN_1 : 23|8@0+ (0.03125,0) [0|7.96875] "m/s2" Vector__XXX
 SG_ VSA_EPB_INHIBIT_ACT_1 : 12|1@0+ (1,0) [0|1] "" Vector__XXX
 SG_ VSA_EPB_REFUSE_ACT_1 : 13|1@0+ (1,0) [0|1] "" Vector__XXX
 SG_ VSA_EPB_STAY_AWAKE_REQ_VSA_1 : 14|1@0+ (1,0) [0|1] "" Vector__XXX
 SG_ VSA_EPB_REQ_BRAKE_CTRL_1 : 15|1@0+ (1,0) [0|1] ""  EPB

BO_ 274 VSA_EPB_112_CH1: 3 VSA
 SG_ VSA_EPB_CLUTCH_PEDAL_STROKE_1 : 7|8@0+ (0.39215686275,0) [0|100] "%" Vector__XXX
 SG_ VSA_EPB_CLUTCH_PEDAL_FAIL_1 : 23|1@0+ (1,0) [0|1] ""  EPB
 SG_ VSA_EPB_CHECKSUM_112_1 : 19|4@0+ (1,0) [0|15] "" Vector__XXX
 SG_ VSA_EPB_ALIVE_COUNTER_112_1 : 21|2@0+ (1,0) [0|3] "" Vector__XXX

BO_ 356 METER_164_CH1: 8 METER
 SG_ METER_SW_STATUS_BHOLD_SENKOSYA_1 : 62|1@0+ (1,0) [0|1] ""  VSA
 SG_ METER_CHECKSUM_164_1 : 59|4@0+ (1,0) [0|15] ""  VSA,SRS,ENG
 SG_ METER_ALIVE_COUNTER_164_1 : 61|2@0+ (1,0) [0|3] ""  VSA,SRS,ENG
 SG_ METER_SW_STATUS_PARK_BRAKE_1 : 2|1@0+ (1,0) [0|1] ""  VSA,SRS
 SG_ METER_SW_STATUS_BRAKE_FLUID_1 : 3|1@0+ (1,0) [0|1] ""  VSA
 SG_ METER_SW_STATUS_VSA_OFF_1 : 4|1@0+ (1,0) [0|1] ""  VSA

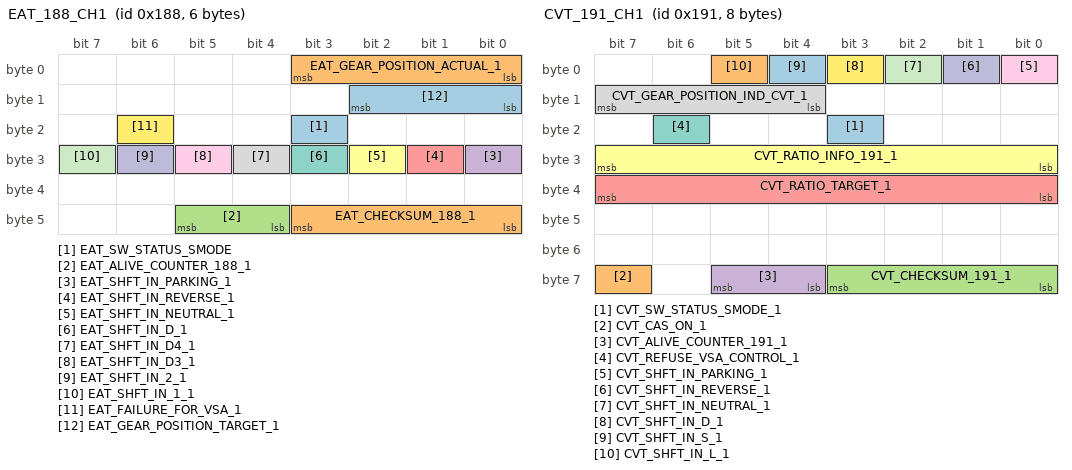
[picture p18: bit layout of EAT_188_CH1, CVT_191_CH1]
BO_ 392 EAT_188_CH1: 6 EAT
 SG_ EAT_SW_STATUS_SMODE : 19|1@0+ (1,0) [0|1] ""  VSA
 SG_ EAT_CHECKSUM_188_1 : 43|4@0+ (1,0) [0|15] ""  VSA,RTC,PUH,METER,EPT2,EPT1,EPS,EPB,ASC,ACM,ACC
 SG_ EAT_ALIVE_COUNTER_188_1 : 45|2@0+ (1,0) [0|3] ""  VSA,RTC,PUH,METER,EPT2,EPT1,EPS,EPB,ASC,ACM,ACC
 SG_ EAT_SHFT_IN_PARKING_1 : 24|1@0+ (1,0) [0|1] ""  VSA,METER,EPS,EPB,ASC,ACM,ACC
 SG_ EAT_SHFT_IN_REVERSE_1 : 25|1@0+ (1,0) [0|1] ""  VSA,METER,EPB,ACM,ACC
 SG_ EAT_SHFT_IN_NEUTRAL_1 : 26|1@0+ (1,0) [0|1] ""  VSA,METER,EPS,EPB,ACM,ACC
 SG_ EAT_SHFT_IN_D_1 : 27|1@0+ (1,0) [0|1] ""  VSA,METER,EPB,ACM,ACC
 SG_ EAT_SHFT_IN_D4_1 : 28|1@0+ (1,0) [0|1] ""  VSA,EPB,ACM,ACC
 SG_ EAT_SHFT_IN_D3_1 : 29|1@0+ (1,0) [0|1] ""  VSA,EPB,ACM,ACC
 SG_ EAT_SHFT_IN_2_1 : 30|1@0+ (1,0) [0|1] ""  VSA,EPB,ACM,ACC
 SG_ EAT_SHFT_IN_1_1 : 31|1@0+ (1,0) [0|1] ""  VSA,EPB,ACM,ACC
 SG_ EAT_FAILURE_FOR_VSA_1 : 22|1@0+ (1,0) [0|1] ""  VSA
 SG_ EAT_GEAR_POSITION_TARGET_1 : 10|3@0+ (1,0) [0|7] ""  VSA,EPB
 SG_ EAT_GEAR_POSITION_ACTUAL_1 : 3|4@0+ (1,0) [0|15] ""  VSA,EPT2,EPT1,EPB,ASC,ACC

BO_ 401 CVT_191_CH1: 8 CVT
 SG_ CVT_SW_STATUS_SMODE_1 : 19|1@0+ (1,0) [0|1] ""  VSA
 SG_ CVT_CAS_ON_1 : 63|1@0+ (1,0) [0|1] ""  VSA
 SG_ CVT_CHECKSUM_191_1 : 59|4@0+ (1,0) [0|15] ""  VSA,METER,FCM,EPS
 SG_ CVT_ALIVE_COUNTER_191_1 : 61|2@0+ (1,0) [0|3] ""  VSA,METER,FCM,EPS
 SG_ CVT_RATIO_TARGET_1 : 39|8@0+ (0.015625,0) [0|3.984375] ""  VSA
 SG_ CVT_RATIO_INFO_191_1 : 31|8@0+ (0.015625,0) [0|3.984375] ""  VSA
 SG_ CVT_REFUSE_VSA_CONTROL_1 : 22|1@0+ (1,0) [0|1] ""  VSA
 SG_ CVT_GEAR_POSITION_IND_CVT_1 : 15|4@0+ (1,0) [0|15] ""  VSA,METER
 SG_ CVT_SHFT_IN_PARKING_1 : 0|1@0+ (1,0) [0|1] ""  VSA,METER,EPS
 SG_ CVT_SHFT_IN_REVERSE_1 : 1|1@0+ (1,0) [0|1] ""  VSA,METER
 SG_ CVT_SHFT_IN_NEUTRAL_1 : 2|1@0+ (1,0) [0|1] ""  VSA,METER
 SG_ CVT_SHFT_IN_D_1 : 3|1@0+ (1,0) [0|1] ""  VSA
 SG_ CVT_SHFT_IN_S_1 : 4|1@0+ (1,0) [0|1] ""  VSA,METER
 SG_ CVT_SHFT_IN_L_1 : 5|1@0+ (1,0) [0|1] ""  VSA,METER

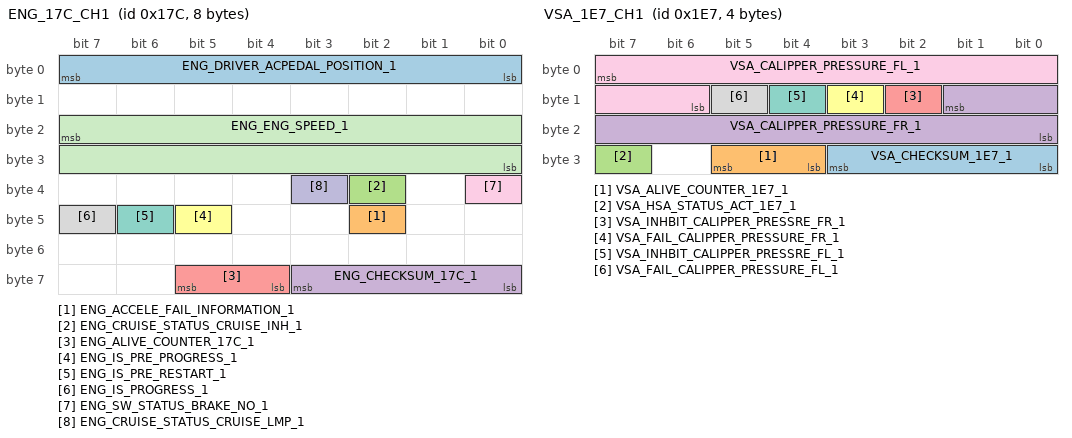
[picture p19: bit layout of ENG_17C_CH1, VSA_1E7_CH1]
BO_ 380 ENG_17C_CH1: 8 ENG
 SG_ ENG_DRIVER_ACPEDAL_POSITION_1 : 7|8@0+ (0.39215686275,0) [0|100] "%"  VSA
 SG_ ENG_ACCELE_FAIL_INFORMATION_1 : 42|1@0+ (1,0) [0|1] ""  VSA
 SG_ ENG_CRUISE_STATUS_CRUISE_INH_1 : 34|1@0+ (1,0) [0|1] ""  VSA
 SG_ ENG_CHECKSUM_17C_1 : 59|4@0+ (1,0) [0|15] ""  VSA,SS30,SRS,SMART,METER,FCM,EPS
 SG_ ENG_ALIVE_COUNTER_17C_1 : 61|2@0+ (1,0) [0|3] ""  VSA,SS30,SRS,SMART,METER,FCM,EPS
 SG_ ENG_IS_PRE_PROGRESS_1 : 45|1@0+ (1,0) [0|1] ""  VSA,EPS
 SG_ ENG_IS_PRE_RESTART_1 : 46|1@0+ (1,0) [0|1] ""  VSA,SMART,METER,EPS
 SG_ ENG_IS_PROGRESS_1 : 47|1@0+ (1,0) [0|1] ""  VSA,SMART,METER,EPS
 SG_ ENG_SW_STATUS_BRAKE_NO_1 : 32|1@0+ (1,0) [0|1] ""  VSA,SRS,NAVI,AHU
 SG_ ENG_CRUISE_STATUS_CRUISE_LMP_1 : 35|1@0+ (1,0) [0|1] ""  VSA,METER
 SG_ ENG_ENG_SPEED_1 : 23|16@0+ (1,0) [0|15000] "rpm"  VSA,SRS,NAVI,EPS,AHU

BO_ 342 STR_156_CH1: 6 STR
 SG_ STR_TRIM_1 : 34|1@0+ (1,0) [0|1] ""  VSA
 SG_ STR_CHECKSUM_156_1 : 43|4@0+ (1,0) [0|15] ""  VSA,SS30,SRS,METER,FCM,EPS
 SG_ STR_ALIVE_COUNTER_156_1 : 45|2@0+ (1,0) [0|3] ""  VSA,SS30,SRS,METER,FCM,EPS
 SG_ STR_OK_1 : 32|1@0+ (1,0) [0|1] ""  VSA,SS30,SRS,METER,EPS
 SG_ STR_CAL_1 : 33|1@0+ (1,0) [0|1] ""  VSA,SS30,METER,EPS
 SG_ STR_SPEED_1 : 23|16@0- (1,0) [-32768|32767] "deg/s"  VSA,SS30,METER,EPS
 SG_ STR_ANGLE_1 : 7|16@0- (0.1,0) [-3276.8|3276.7] "deg"  VSA,SS30,SRS,METER,EPS

BO_ 304 ENG_130_CH1: 8 ENG
 SG_ ENG_PP_DISABLE_1 : 43|1@0+ (1,0) [0|1] "" Vector__XXX
 SG_ ENG_PPTRQSTB_STANDBY_1 : 53|1@0+ (1,0) [0|1] "" Vector__XXX
 SG_ ENG_CLUTCH_SW_SIL_1 : 51|1@0+ (1,0) [0|1] ""  VSA
 SG_ ENG_EV_DRIVE_STATE_1 : 55|1@0+ (1,0) [0|1] ""  VSA
 SG_ ENG_BRK_ACCELE_PEDAL_ON_1 : 44|1@0+ (1,0) [0|1] ""  VSA
 SG_ ENG_SHFT_IN_REVERSE_1 : 49|1@0+ (1,0) [0|1] ""  VSA
 SG_ ENG_CHECKSUM_130_1 : 59|4@0+ (1,0) [0|15] ""  VSA,SRS,EPS
 SG_ ENG_ALIVE_COUNTER_130_1 : 61|2@0+ (1,0) [0|3] ""  VSA,SRS,EPS
 SG_ ENG_NEUTRAL_SENSOR_FAIL_1 : 62|1@0+ (1,0) [0|1] ""  VSA
 SG_ ENG_RECEIVE_ERROR_1AC_1 : 63|1@0+ (1,0) [0|1] ""  VSA
 SG_ ENG_SHFT_IN_NEUTRAL_1 : 48|1@0+ (1,0) [0|1] ""  VSA,EPS
 SG_ ENG_CLUTCH_SW_CC_1 : 50|1@0+ (1,0) [0|1] ""  VSA
 SG_ ENG_VSA_ACK1_1 : 41|2@0+ (1,0) [0|15] ""  VSA
 SG_ ENG_VSA_PERMIT_PLUS_TRQ_1 : 45|1@0+ (1,0) [0|1] ""  VSA
 SG_ ENG_VSA_INHIBIT_VSA_CONTROL_1_1 : 46|1@0+ (1,0) [0|1] ""  VSA
 SG_ ENG_VSA_REFUSED_VSA_CONTROL_1_1 : 47|1@0+ (1,0) [0|1] ""  VSA
 SG_ ENG_SMART_ACCELE_PEDAL_POS_1 : 39|8@0+ (0.39215686275,0) [0|100] "%"  VSA,SRS
 SG_ ENG_DRIVER_REQ_TRQ_130_1 : 23|16@0- (1,0) [-32768|32767] "Nm"  VSA
 SG_ ENG_ENG_TRQ_130_1 : 7|16@0- (1,0) [-32768|32767] "Nm"  VSA

BO_ 545 METER_221_CH1: 6 METER
 SG_ METER_ECONSW_ON_1 : 23|1@0+ (1,0) [0|1] ""  VSA
 SG_ METER_SW_STATUS_MODE_1 : 39|4@0+ (1,0) [0|15] ""  VSA
 SG_ METER_CHECKSUM_221_1 : 43|4@0+ (1,0) [0|15] ""  VSA
 SG_ METER_ALIVE_COUNTER_221_1 : 45|2@0+ (1,0) [0|3] ""  VSA

BO_ 578 E4WD_242_CH1: 2 E4WD
 SG_ E4WD_REAR_DISTRIBUTION_242_1 : 7|4@0+ (1,0) [0|15] "Nm"  VSA,E4WD
 SG_ E4WD_CHECKSUM_242_1 : 11|4@0+ (1,0) [0|15] ""  VSA
 SG_ E4WD_ALIVE_COUNTER_242_1 : 13|2@0+ (1,0) [0|3] ""  VSA

BO_ 1934 VSA_78E_CH1: 8 VSA
 SG_ VSA_CHECKSUM_78E_1 : 59|4@0+ (1,0) [0|15] ""  STR
 SG_ VSA_ALIVE_COUNTER_78E_1 : 61|2@0+ (1,0) [0|3] ""  STR
 SG_ VSA_COMMAND_CODE_1 : 7|8@0+ (1,0) [0|255] ""  STR

BO_ 476 ENG_1DC_CH1: 5 ENG
 SG_ ENG_CHECKSUM_1DC_1 : 35|4@0+ (1,0) [0|0] ""  VSA
 SG_ ENG_ALIVE_COUNTER_1DC_1 : 37|2@0+ (1,0) [0|0] ""  VSA
 SG_ ENG_IDS_MODE_TARGET_1 : 27|4@0+ (1,0) [0|0] ""  VSA
 SG_ ENG_IDS_MODE_CONTROL_1 : 31|4@0+ (1,0) [0|0] ""  VSA

BO_ 1030 VSA_406_CH1: 5 VSA
 SG_ VSA_CHECKSUM_406_1 : 35|4@0+ (1,0) [0|15] "" Vector__XXX
 SG_ VSA_ALIVE_COUNTER_406_1 : 37|2@0+ (1,0) [0|3] "" Vector__XXX
 SG_ VSA_SPECIFY_CODE_SYS_1 : 24|1@0+ (1,0) [0|1] "" Vector__XXX
 SG_ VSA_DTC_STORAGE_1 : 25|1@0+ (1,0) [0|1] "" Vector__XXX
 SG_ VSA_DTC_LOW_1 : 15|8@0+ (1,0) [0|255] ""  NAVI,AHU
 SG_ VSA_DTC_HIGH_1 : 7|8@0+ (1,0) [0|255] ""  NAVI,AHU

BO_ 597 VSA_255_CH1: 8 VSA
 SG_ VSA_ABS_CHECKSUM_255_1 : 63|8@0+ (1,0) [0|255] ""  SMART,METER
 SG_ VSA_ABS_ALIVE_COUNTER_255_1 : 55|8@0+ (1,0) [0|255] ""  SMART,METER
 SG_ VSA_ABS_SPEED_FIXED_NUMBER2_1 : 47|8@0+ (1,0) [0|255] ""  SMART,METER
 SG_ VSA_ABS_SPEED_FIXED_NUMBER1_1 : 39|8@0+ (1,0) [0|255] ""  SMART,METER
 SG_ VSA_ABS_RR_WHEEL_SPEED_255_1 : 31|8@0+ (1,0) [0|255] "km/h"  SMART,METER
 SG_ VSA_ABS_RL_WHEEL_SPEED_255_1 : 23|8@0+ (1,0) [0|255] "km/h"  SMART,METER
 SG_ VSA_ABS_FR_WHEEL_SPEED_255_1 : 15|8@0+ (1,0) [0|255] "km/h"  SMART,METER
 SG_ VSA_ABS_FL_WHEEL_SPEED_255_1 : 7|8@0+ (1,0) [0|255] "km/h"  SMART,METER,ENG

BO_ 490 VSA_1EA_CH1: 8 VSA
 SG_ VSA_CHECKSUM_1EA_1 : 59|4@0+ (1,0) [0|15] ""  EPS
 SG_ VSA_ALIVE_COUNTER_1EA_1 : 61|2@0+ (1,0) [0|3] ""  EPS
 SG_ VSA_MAEPS_REVERSE_F_1 : 48|1@0+ (1,0) [0|1] ""  EPS
 SG_ VSA_SYSTEM_F_1 : 50|1@0+ (1,0) [0|1] ""  EPS
 SG_ VSA_MAEPS_MYU_VALUE_1 : 39|16@0- (3.90625E-005,0) [-1.28|1.2799609375] ""  EPS
 SG_ VSA_MAEPS_GX_VALUE_1 : 23|16@0- (0.00015258789063,0) [-5|4.9998474121] "G"  EPS
 SG_ VSA_MAEPS_US_VALUE_1 : 7|16@0- (0.0038146972656,0) [-125|124.9961853] "deg/s"  EPS

BO_ 334 E4WD_14E_CH1: 8 E4WD
 SG_ E4WD_ERROR_STATUS_14E_1 : 35|1@0+ (1,0) [0|1] ""  VSA
 SG_ E4WD_CHECKSUM_14E_1 : 59|4@0+ (1,0) [0|15] ""  VSA
 SG_ E4WD_ALIVECOUNTER_14E_1 : 61|2@0+ (1,0) [0|3] ""  VSA
 SG_ E4WD_MDTR_1 : 15|8@0+ (10,0) [0|2550] "Nm"  VSA
 SG_ E4WD_MDTL_1 : 7|8@0+ (10,0) [0|2550] "Nm"  VSA

BO_ 1029 METER_405_CH1: 8 METER
 SG_ METER_CHECKSUM_405_1 : 59|4@0+ (1,0) [0|15] ""  VSA,NAVI,ANC
 SG_ METER_ALIVE_COUNTER_405_1 : 61|2@0+ (1,0) [0|3] ""  VSA,NAVI,ANC
 SG_ METER_WARN_STATUS_TIRE_PRESS_1 : 12|1@0+ (1,0) [0|1] ""  VSA,NAVI
 SG_ METER_WARN_STATUS_TPMS_SYSTEM_1 : 13|1@0+ (1,0) [0|1] ""  VSA,NAVI

BO_ 819 TPMS_333_CH1: 7 TPMS
 SG_ TPMS_WARN_STATUS_ISO_1 : 0|1@0+ (1,0) [0|1] ""  VSA
 SG_ TPMS_WARN_STATUS_SYSTEM_1 : 1|1@0+ (1,0) [0|1] ""  VSA
 SG_ TPMS_ALIVE_COUNTER_333_1 : 53|2@0+ (1,0) [0|0] ""  VSA
 SG_ TPMS_CHECKSUM_333_1 : 51|4@0+ (1,0) [0|0] ""  VSA

BO_ 487 VSA_1E7_CH1: 4 VSA
 SG_ VSA_CHECKSUM_1E7_1 : 27|4@0+ (1,0) [0|15] "" Vector__XXX
 SG_ VSA_ALIVE_COUNTER_1E7_1 : 29|2@0+ (1,0) [0|3] "" Vector__XXX
 SG_ VSA_HSA_STATUS_ACT_1E7_1 : 31|1@0+ (1,0) [0|1] "" Vector__XXX
 SG_ VSA_CALIPPER_PRESSURE_FR_1 : 9|10@0+ (23.96,-2443.92) [-2443.92|22067.16] "kPa" Vector__XXX
 SG_ VSA_INHBIT_CALIPPER_PRESSRE_FR_1 : 10|1@0+ (1,0) [0|1] "" Vector__XXX
 SG_ VSA_FAIL_CALIPPER_PRESSURE_FR_1 : 11|1@0+ (1,0) [0|1] "" Vector__XXX
 SG_ VSA_INHBIT_CALIPPER_PRESSRE_FL_1 : 12|1@0+ (1,0) [0|1] "" Vector__XXX
 SG_ VSA_FAIL_CALIPPER_PRESSURE_FL_1 : 13|1@0+ (1,0) [0|1] "" Vector__XXX
 SG_ VSA_CALIPPER_PRESSURE_FL_1 : 7|10@0+ (23.96,-2443.92) [-2443.92|22067.16] "kPa"  ABS

BO_ 464 VSA_1D0_CH1: 8 VSA
 SG_ VSA_ABS_CHECKSUM_1D0_1 : 59|4@0+ (1,0) [0|15] ""  SS30,EPS,ENG,CVT
 SG_ VSA_ABS_RR_WHEEL_SPEED_1 : 42|15@0+ (0.01,0) [0|327.67] "km/h"  SS30,EPS,ENG,CVT
 SG_ VSA_ABS_RL_WHEEL_SPEED_1 : 25|15@0+ (0.01,0) [0|327.67] "km/h"  SS30,EPS,ENG,CVT
 SG_ VSA_ABS_FR_WHEEL_SPEED_1 : 8|15@0+ (0.01,0) [0|327.67] "km/h"  SS30,EPS,ENG,CVT
 SG_ VSA_ABS_FL_WHEEL_SPEED_1 : 7|15@0+ (0.01,0) [0|327.67] "km/h"  SS30,EPS,ENG,CVT

BO_ 432 VSA_1B0_CH1: 7 VSA
 SG_ VSA_PLANT_INSPECTION_STATUS_1 : 25|1@0+ (1,0) [0|1] "" Vector__XXX
 SG_ VSA_INHIBIT_BRKRELAY_FOR_CMBS_1 : 16|1@0+ (1,0) [0|1] "" Vector__XXX
 SG_ VSA_BRKPAD_TEMP_CALC_FAIL_1B0_1 : 19|1@0+ (1,0) [0|1] "" Vector__XXX
 SG_ VSA_BRKPAD_TEMP_STATE_STOP_1B0_1 : 20|1@0+ (1,0) [0|1] "" Vector__XXX
 SG_ VSA_BRKPAD_TEMP_STATE_WAIT_1B0_1 : 21|1@0+ (1,0) [0|1] "" Vector__XXX
 SG_ VSA_BRKPAD_TEMP_CALC_INH_1B0_1 : 18|1@0+ (1,0) [0|1] "" Vector__XXX
 SG_ VSA_ABS_BUSY_1 : 55|1@0+ (1,0) [0|1] "" Vector__XXX
 SG_ VSA_EPT_COMFORT_TRIG_1 : 22|1@0+ (1,0) [0|1] "" Vector__XXX
 SG_ VSA_EPT_PRECRASH_TRIG_1 : 23|1@0+ (1,0) [0|1] "" Vector__XXX
 SG_ VSA_ABS_ENB_VW_SENSOR_ACT_1 : 54|1@0+ (1,0) [0|1] "" Vector__XXX
 SG_ VSA_INHBIT_LONG_G_SENSOR_1 : 2|1@0+ (1,0) [0|1] "" Vector__XXX
 SG_ VSA_FAIL_LONG_G_SENSOR_1 : 4|1@0+ (1,0) [0|1] "" Vector__XXX
 SG_ VSA_ACC_REFUSE_ACC_BRAKE_1 : 9|1@0+ (1,0) [0|1] "" Vector__XXX
 SG_ VSA_ACC_INHIBIT_ACC_BRAKE_1 : 8|1@0+ (1,0) [0|1] "" Vector__XXX
 SG_ VSA_ABS_VW_SENSOR_START_UP_1 : 15|1@0+ (1,0) [0|1] "" Vector__XXX
 SG_ VSA_INHIBIT_BRAKERELAY_1 : 5|1@0+ (1,0) [0|1] "" Vector__XXX
 SG_ VSA_INHBIT_LAT_G_SENSOR_1 : 1|1@0+ (1,0) [0|1] "" Vector__XXX
 SG_ VSA_FAIL_LAT_G_SENSOR_1 : 3|1@0+ (1,0) [0|1] "" Vector__XXX
 SG_ VSA_ACT_BRAKERELAY_1 : 0|1@0+ (1,0) [0|1] "" Vector__XXX
 SG_ VSA_CHECKSUM_1B0_1 : 51|4@0+ (1,0) [0|15] ""  SS30,METER,FCM,EPS,CVT
 SG_ VSA_ALIVE_COUNTER_1B0_1 : 53|2@0+ (1,0) [0|3] ""  SS30,METER,FCM,EPS,CVT
 SG_ VSA_REQ_CVT_TCS_1 : 40|1@0+ (1,0) [0|1] ""  CVT
 SG_ VSA_REQ_CVT_PRS_1 : 41|1@0+ (1,0) [0|1] ""  CVT
 SG_ VSA_CONTROL_MODE_CVT_1 : 43|2@0+ (1,0) [0|3] ""  CVT
 SG_ VSA_ABS_STATUS_FR_ABS_EBD_ACT_1 : 44|1@0+ (1,0) [0|1] "" Vector__XXX
 SG_ VSA_ABS_STATUS_FL_ABS_EBD_ACT_1 : 45|1@0+ (1,0) [0|1] "" Vector__XXX
 SG_ VSA_ABS_STATUS_RR_ABS_EBD_ACT_1 : 46|1@0+ (1,0) [0|1] "" Vector__XXX
 SG_ VSA_ABS_STATUS_RL_ABS_EBD_ACT_1 : 47|1@0+ (1,0) [0|1] "" Vector__XXX
 SG_ VSA_FAIL_STEERING_SENSOR_1 : 32|1@0+ (1,0) [0|1] "" Vector__XXX
 SG_ VSA_FAIL_YAW_RATE_SENSOR_1 : 33|1@0+ (1,0) [0|1] ""  SS30
 SG_ VSA_FAIL_MC_PRESSRE_SENSOR_1B0_1 : 34|1@0+ (1,0) [0|1] "" Vector__XXX
 SG_ VSA_ABS_FAIL_FR_VW_SENSOR_1 : 35|1@0+ (1,0) [0|1] ""  SS30,EPS,CVT
 SG_ VSA_ABS_FAIL_FL_VW_SENSOR_1 : 36|1@0+ (1,0) [0|1] ""  SS30,EPS,CVT
 SG_ VSA_ABS_FAIL_RR_VW_SENSOR_1 : 37|1@0+ (1,0) [0|1] ""  SS30,EPS,CVT
 SG_ VSA_ABS_FAIL_RL_VW_SENSOR_1 : 38|1@0+ (1,0) [0|1] ""  SS30,EPS,CVT
 SG_ VSA_ABS_INHBIT_VW_SENSOR_1 : 39|1@0+ (1,0) [0|1] ""  SS30,EPS
 SG_ VSA_ACC_INHIBIT_CVRS_BRAKE_1 : 10|1@0+ (1,0) [0|1] ""  SS30
 SG_ VSA_INHBIT_STEERING_SENSOR_1 : 13|1@0+ (1,0) [0|1] "" Vector__XXX
 SG_ VSA_ACC_REFUSE_CVRS_BRAKE_1 : 11|1@0+ (1,0) [0|1] ""  SS30
 SG_ VSA_VW_PULSE_CAPTURED_1 : 12|1@0+ (1,0) [0|1] ""  SS30
 SG_ VSA_INHBIT_YAW_RATE_SENSOR_1 : 14|1@0+ (1,0) [0|1] "-"  SS30
 SG_ VSA_FAIL_BRAKERELAY_1 : 6|1@0+ (1,0) [0|1] ""  SS30
 SG_ VSA_SS30_BRAKE_ACT_1 : 7|1@0+ (1,0) [0|1] ""  SS30

BO_ 150 VSA_096_CH1: 8 VSA
 SG_ VSA_CHECKSUM_096_1 : 59|4@0+ (1,0) [0|15] "" Vector__XXX
 SG_ VSA_ALIVE_COUNTER_096_1 : 61|2@0+ (1,0) [0|3] "" Vector__XXX
 SG_ VSA_YAW_2_1 : 7|10@0+ (0.244140625,-125) [0|922] "deg/sec"  STR

BO_ 428 VSA_1AC_CH1: 8 VSA
 SG_ VSA_BTCS_ACT_1AC_1 : 53|1@0+ (1,0) [0|1] "-" Vector__XXX
 SG_ VSA_IDS_TEMP_INHIBIT_1 : 54|1@0+ (1,0) [0|1] "" Vector__XXX
 SG_ VSA_IG_ON_1 : 55|1@0+ (1,0) [0|1] "" Vector__XXX
 SG_ VSA_EBB_FAILURE_FOR_IS_1 : 41|1@0+ (1,0) [0|1] "" Vector__XXX
 SG_ VSA_IDS_INHIBIT_DISABLED_STATE_1 : 44|1@0+ (1,0) [0|1] "" Vector__XXX
 SG_ VSA_IDS_INHIBIT_ACT_1 : 45|1@0+ (1,0) [0|1] "" Vector__XXX
 SG_ VSA_HAC_CUT_REQ_1 : 32|1@0+ (1,0) [0|1] "" Vector__XXX
 SG_ VSA_HBB_IS_REFUSE_REQ_1 : 33|1@0+ (1,0) [0|1] "" Vector__XXX
 SG_ VSA_LOW_VAC_IS_SHFT_INHBIT_REQ_1 : 34|1@0+ (1,0) [0|1] "" Vector__XXX
 SG_ VSA_MNTMODE_STATUS_1 : 24|1@0+ (1,0) [0|1] "" Vector__XXX
 SG_ VSA_REVERSE_SWITCH_FAIL_1 : 25|1@0+ (1,0) [0|1] "" Vector__XXX
 SG_ VSA_SHFT_IN_REVERSE_1 : 26|1@0+ (1,0) [0|1] "" Vector__XXX
 SG_ VSA_ECD_ACT_1 : 27|1@0+ (1,0) [0|1] "" Vector__XXX
 SG_ VSA_FAIL_FOR_EPB_1 : 28|1@0+ (1,0) [0|1] "" Vector__XXX
 SG_ VSA_REQUEST_EPB_ACT_1 : 29|1@0+ (1,0) [0|1] "" Vector__XXX
 SG_ VSA_EPB_INHIBIT_BRAKE_1 : 30|1@0+ (1,0) [0|1] "" Vector__XXX
 SG_ VSA_HBB_IS_SHIFT_INHIBIT_REQ_1 : 35|1@0+ (1,0) [0|1] "" Vector__XXX
 SG_ VSA_EPB_REFUSE_BRAKE_1 : 31|1@0+ (1,0) [0|1] "" Vector__XXX
 SG_ VSA_TSA_ACT_1 : 63|1@0+ (1,0) [0|1] "" Vector__XXX
 SG_ VSA_ISAB_ACT_1 : 42|1@0+ (1,0) [0|1] "" Vector__XXX
 SG_ VSA_IS_RESTART_INHIBIT_REQUEST_1 : 46|1@0+ (1,0) [0|1] "" Vector__XXX
 SG_ VSA_ISAB_ENABLE_1 : 43|1@0+ (1,0) [0|1] "" Vector__XXX
 SG_ VSA_IS_SHIFT_INHIBIT_REQUEST_1_1 : 47|1@0+ (1,0) [0|1] "" Vector__XXX
 SG_ VSA_SHIFT_REQ_1AC_1 : 19|2@0+ (1,0) [0|3] ""  EPB,ENG
 SG_ VSA_ALIVE_COUNTER_1AC_1 : 61|2@0+ (1,0) [0|3] "" Vector__XXX
 SG_ VSA_CHECKSUM_1AC_1 : 59|4@0+ (1,0) [0|15] "" Vector__XXX
 SG_ VSA_REQ_TRQ_1AC_1 : 7|16@0- (1,0) [-32768|32767] "Nm" Vector__XXX
 SG_ VSA_REQ_MSR_PLUS_TRQ_1 : 62|1@0+ (1,0) [0|1] "" Vector__XXX
 SG_ VSA_TRQ_CONTROL_MODE_1 : 17|2@0+ (1,0) [0|3] "" Vector__XXX
 SG_ VSA_TRQ_DOWN_REQ_FUEL_CUT_1 : 23|4@0+ (1,0) [0|15] "" Vector__XXX

BO_ 420 VSA_1A4_CH1: 8 VSA
 SG_ VSA_VSA_OS_CTRL_1 : 54|1@0+ (1,0) [0|1] "" Vector__XXX
 SG_ VSA_ESB_INCREASE_PRESS_ACT_1 : 55|1@0+ (1,0) [0|1] "" Vector__XXX
 SG_ VSA_WARN_STATUS_BHOLD_1 : 47|1@0+ (1,0) [0|0] "" Vector__XXX
 SG_ VSA_MID_REQ_BHOLD_STANDBY_1 : 41|1@0+ (1,0) [0|0] "" Vector__XXX
 SG_ VSA_MID_REQ_BHOLD_MISOP_GUIDE_1 : 43|2@0+ (1,0) [0|3] "" Vector__XXX
 SG_ VSA_MID_REQ_BHOLD_EPB_OP_INFO_1 : 44|1@0+ (1,0) [0|0] "" Vector__XXX
 SG_ VSA_MID_REQ_BHOLD_APPLY_BRAKE_1 : 40|1@0+ (1,0) [0|0] "" Vector__XXX
 SG_ VSA_LAMP_STATUS_VSA_OFF_TFT_1 : 33|1@0+ (1,0) [0|1] "" Vector__XXX
 SG_ VSA_WARN_STATUS_BRAKESYSTEM_1 : 36|1@0+ (1,0) [0|1] "" Vector__XXX
 SG_ VSA_LAMP_BHOLD_APPLY_BRAKE_1 : 53|1@0+ (1,0) [0|0] "" Vector__XXX
 SG_ VSA_BHOLD_STATUS_ACT_1 : 52|1@0+ (1,0) [0|0] "" Vector__XXX
 SG_ VSA_LAMP_STATUS_HDC_1 : 37|1@0+ (1,0) [0|1] "" Vector__XXX
 SG_ VSA_WARN_STATUS_HDC_1 : 38|1@0+ (1,0) [0|1] "" Vector__XXX
 SG_ VSA_LAMP_STATUS_OPERATE_BHOLD_1 : 46|1@0+ (1,0) [0|0] "" Vector__XXX
 SG_ VSA_LAMP_STATUS_STANBY_BHOLD_1 : 45|1@0+ (1,0) [0|0] "" Vector__XXX
 SG_ VSA_AHA_CTRL_1 : 39|1@0+ (1,0) [0|1] "" Vector__XXX
 SG_ VSA_ACC_BRAKE_ACT_1 : 23|1@0+ (1,0) [0|1] "" Vector__XXX
 SG_ VSA_WARN_STATUS_PUNCTURE_1 : 25|1@0+ (1,0) [0|1] "" Vector__XXX
 SG_ VSA_WARN_STATUS_DWS_1 : 26|1@0+ (1,0) [0|1] "" Vector__XXX
 SG_ VSA_ANSWER_DWS_INIT_REQ_1 : 24|1@0+ (1,0) [0|1] "" Vector__XXX
 SG_ VSA_L_MODE_ABS_EBD_1 : 32|1@0+ (1,0) [0|1] "" Vector__XXX
 SG_ VSA_CHECKSUM_1A4_1 : 59|4@0+ (1,0) [0|15] ""  SS30,SMART,METER,FCM,EPS,ENG,CVT
 SG_ VSA_ALIVE_COUNTER_1A4_1 : 61|2@0+ (1,0) [0|3] ""  SS30,SMART,METER,FCM,EPS,ENG,CVT
 SG_ VSA_ABS_CTRL_1 : 62|1@0+ (1,0) [0|1] ""  SS30
 SG_ VSA_VSA_CTRL_1 : 63|1@0+ (1,0) [0|1] ""  SS30
 SG_ VSA_WARN_STATUS_HSA_1 : 48|1@0+ (1,0) [0|1] ""  METER
 SG_ VSA_HSA_STATUS_ACT_1 : 49|1@0+ (1,0) [0|1] "" Vector__XXX
 SG_ VSA_ESS_ACT4_1 : 50|1@0+ (1,0) [0|1] ""  METER
 SG_ VSA_ESS_ACT3_1 : 51|1@0+ (1,0) [0|1] ""  METER
 SG_ VSA_REWRITE_START_1 : 34|1@0+ (1,0) [0|1] ""  SMART,EPS
 SG_ VSA_BUZZER_STATUS_1 : 35|1@0+ (1,0) [0|1] ""  METER
 SG_ VSA_MID_REQUEST_VSA_1 : 27|1@0+ (1,0) [0|1] ""  METER
 SG_ VSA_LAMP_STATUS_VSA_OFF_1 : 28|1@0+ (1,0) [0|1] ""  METER
 SG_ VSA_WARN_STATUS_VSA_1 : 29|1@0+ (1,0) [0|1] ""  METER
 SG_ VSA_WARN_STATUS_ABS_1 : 30|1@0+ (1,0) [0|1] ""  METER,ENG,CVT
 SG_ VSA_WARN_STATUS_BRAKE_1 : 31|1@0+ (1,0) [0|1] ""  METER
 SG_ VSA_VSA_TCS_ACT_1 : 16|1@0+ (1,0) [0|1] ""  NAVI,EPS,ENG,CVT,AHU
 SG_ VSA_ABS_EBD_ACT_1 : 17|1@0+ (1,0) [0|1] ""  NAVI,EPS,CVT,AHU
 SG_ VSA_VSA_TCS_MIL_1 : 18|1@0+ (1,0) [0|1] "" Vector__XXX
 SG_ VSA_ABS_EBD_MIL_1 : 19|1@0+ (1,0) [0|1] ""  SS30,ENG
 SG_ VSA_CASEN_1 : 20|1@0+ (1,0) [0|1] ""  CVT
 SG_ VSA_CAS_ACT_1 : 21|1@0+ (1,0) [0|1] ""  CVT
 SG_ VSA_BA_ACT_1 : 22|1@0+ (1,0) [0|1] ""  SS30
 SG_ VSA_MASTER_CYLINDER_PRESSURE_1 : 3|12@0+ (23.96,-2443.92) [-2443.92|95672.28] "kPa"  SS30,ENG
 SG_ VSA_FAIL_MC_PRESSURE_SENSOR_1_1 : 4|1@0+ (1,0) [0|1] ""  SS30,ENG
 SG_ VSA_INHBIT_MC_PRESSURE_SENSOR_1 : 5|1@0+ (1,0) [0|1] ""  SS30,ENG
 SG_ VSA_ESS_ACT2_1 : 6|1@0+ (1,0) [0|1] ""  METER
 SG_ VSA_ESS_ACT1_1 : 7|1@0+ (1,0) [0|1] ""  METER

BO_ 411 VSA_19B_CH1: 5 VSA
 SG_ VSA_CHECKSUM_19B_1 : 35|4@0+ (1,0) [0|15] "" Vector__XXX
 SG_ VSA_ALIVE_COUNTER_19B_1 : 37|2@0+ (1,0) [0|3] "" Vector__XXX
 SG_ VSA_ABS_RR_WHEEL_PULSE_COUNTER_1 : 31|8@0+ (1,0) [0|255] "" Vector__XXX
 SG_ VSA_ABS_RL_WHEEL_PULSE_COUNTER_1 : 23|8@0+ (1,0) [0|255] "" Vector__XXX
 SG_ VSA_ABS_FR_WHEEL_PULSE_COUNTER_1 : 15|8@0+ (1,0) [0|255] "" Vector__XXX
 SG_ VSA_ABS_FL_WHEEL_PULSE_COUNTER_1 : 7|8@0+ (1,0) [0|255] ""  ABS

BO_ 145 VSA_091_CH1: 8 VSA
 SG_ VSA_CHECKSUM_091_1 : 59|4@0+ (1,0) [0|15] ""  SS30,FCM,EPS,CVT
 SG_ VSA_ALIVE_COUNTER_091_1 : 61|2@0+ (1,0) [0|3] ""  SS30,FCM,EPS,CVT
 SG_ VSA_SENSOR_START_UP_1 : 63|1@0+ (1,0) [0|1] ""  SS30,EPS,CVT
 SG_ VSA_SENSOR_ERR_MC_1 : 48|1@0+ (1,0) [0|1] ""  EPS,CVT
 SG_ VSA_SENSOR_STATE_IG_1 : 49|1@0+ (1,0) [0|1] ""  EPS,CVT
 SG_ VSA_P_ERR_LON_G_1 : 52|1@0+ (1,0) [0|1] ""  CVT
 SG_ VSA_P_ERR_LAT_G_1 : 53|1@0+ (1,0) [0|1] ""  EPS
 SG_ VSA_P_ERR_DEGC_1 : 54|1@0+ (1,0) [0|1] "" Vector__XXX
 SG_ VSA_P_ERR_YAW1_1 : 55|1@0+ (1,0) [0|1] ""  EPS
 SG_ VSA_T_ERR_LON_G_1 : 44|1@0+ (1,0) [0|1] ""  CVT
 SG_ VSA_T_ERR_LAT_G_1 : 45|1@0+ (1,0) [0|1] ""  EPS
 SG_ VSA_T_ERR_DEGC_1 : 46|1@0+ (1,0) [0|1] "" Vector__XXX
 SG_ VSA_T_ERR_YAW1_1 : 47|1@0+ (1,0) [0|1] ""  EPS
 SG_ VSA_LON_G_1 : 25|10@0+ (0.047851563,-24.5) [-17.66|17.66] "m/sec^2"  CVT
 SG_ VSA_LAT_G_1 : 19|10@0+ (0.047851563,-24.5) [-17.66|17.66] "m/sec^2"  SS30,EPS
 SG_ VSA_DEGC_1 : 13|8@0+ (1,-103) [-40|125] "" Vector__XXX
 SG_ VSA_YAW_1_1 : 7|10@0+ (0.244140625,-125) [-100.1|100.1] "deg/sec"  SS30,EPS

CM_ BO_ 3221225472 "This is a message for not used signals, created by Vector CANdb++ DBC OLE DB Provider.";
CM_ SG_ 795 VSA_DWS_AUTOJUDGE_1 "DWS/iDWS function application flag foe meter auto variant";
CM_ SG_ 304 ENG_PP_DISABLE_1 "Power Plant Disable Flag";
BA_DEF_ SG_  "ValueTableE" STRING ;
BA_DEF_ SG_  "DescriptionE" STRING ;
BA_DEF_ SG_  "DescriptionJ" STRING ;
BA_DEF_ SG_  "GenSigStartValue" INT 0 3000;
BA_DEF_ BO_  "PS" ENUM  "+B","ACC","IG1","IG2","*","vector_leerstring";
BA_DEF_ BO_  "FrameType" INT 0 2;
BA_DEF_ SG_  "GenSigSendType" ENUM  "Cyclic","OnWrite","OnWriteWithRepetition","OnChange","OnChangeWithRepetition","IfActive","IfActiveWithRepetition","NoSigSendType";
BA_DEF_ SG_  "GenSigInactiveValue" INT 0 0;
BA_DEF_ BO_  "GenMsgCycleTime" INT 0 0;
BA_DEF_ BO_  "GenMsgSendType" ENUM  "Cyclic","not_used","not_used","not_used","not_used","Cyclic","not_used","IfActive","NoMsgSendType";
BA_DEF_  "DBName" STRING ;
BA_DEF_  "BusType" STRING ;
BA_DEF_DEF_  "ValueTableE" "";
BA_DEF_DEF_  "DescriptionE" "";
BA_DEF_DEF_  "DescriptionJ" "";
BA_DEF_DEF_  "GenSigStartValue" 0;
BA_DEF_DEF_  "PS" "";
BA_DEF_DEF_  "FrameType" 2;
BA_DEF_DEF_  "GenSigSendType" "Cyclic";
BA_DEF_DEF_  "GenSigInactiveValue" 0;
BA_DEF_DEF_  "GenMsgCycleTime" 0;
BA_DEF_DEF_  "GenMsgSendType" "NoMsgSendType";
BA_DEF_DEF_  "DBName" "";
BA_DEF_DEF_  "BusType" "CAN";
BA_ "DBName" "Honda";
BA_ "GenMsgCycleTime" BO_ 94 10;
BA_ "GenMsgCycleTime" BO_ 93 10;
BA_ "GenMsgSendType" BO_ 93 0;
BA_ "GenMsgCycleTime" BO_ 777 100;
BA_ "GenMsgSendType" BO_ 777 0;
BA_ "GenMsgCycleTime" BO_ 2588256839 1000;
BA_ "GenMsgSendType" BO_ 2588256839 0;
BA_ "GenMsgCycleTime" BO_ 315 10;
BA_ "GenMsgSendType" BO_ 315 0;
BA_ "GenMsgSendType" BO_ 179 0;
BA_ "GenMsgCycleTime" BO_ 179 20;
BA_ "GenMsgSendType" BO_ 780 0;
BA_ "GenMsgCycleTime" BO_ 780 100;
BA_ "GenMsgCycleTime" BO_ 856 100;
BA_ "GenMsgSendType" BO_ 856 0;
BA_ "GenMsgSendType" BO_ 669 0;
BA_ "GenMsgCycleTime" BO_ 669 40;
BA_ "GenMsgSendType" BO_ 668 0;
BA_ "GenMsgCycleTime" BO_ 668 40;
BA_ "GenMsgSendType" BO_ 518 0;
BA_ "GenMsgSendType" BO_ 517 0;
BA_ "GenMsgCycleTime" BO_ 517 20;
BA_ "GenMsgSendType" BO_ 425 0;
BA_ "GenMsgCycleTime" BO_ 425 20;
BA_ "GenMsgSendType" BO_ 332 0;
BA_ "GenMsgCycleTime" BO_ 332 10;
BA_ "GenMsgCycleTime" BO_ 767 100;
BA_ "GenMsgSendType" BO_ 767 0;
BA_ "GenMsgSendType" BO_ 555 0;
BA_ "GenMsgCycleTime" BO_ 555 40;
BA_ "GenMsgSendType" BO_ 1646 0;
BA_ "GenMsgCycleTime" BO_ 1646 200;
BA_ "GenMsgCycleTime" BO_ 1619 1000;
BA_ "GenMsgCycleTime" BO_ 546 40;
BA_ "GenMsgCycleTime" BO_ 845 100;
BA_ "GenMsgSendType" BO_ 489 0;
BA_ "GenMsgCycleTime" BO_ 489 20;
BA_ "GenMsgSendType" BO_ 493 0;
BA_ "GenMsgCycleTime" BO_ 493 20;
BA_ "GenMsgSendType" BO_ 446 0;
BA_ "GenMsgCycleTime" BO_ 446 20;
BA_ "GenMsgCycleTime" BO_ 131 10;
BA_ "GenMsgSendType" BO_ 131 0;
BA_ "GenMsgCycleTime" BO_ 424 20;
BA_ "GenMsgSendType" BO_ 424 0;
BA_ "GenMsgCycleTime" BO_ 302 20;
BA_ "GenMsgSendType" BO_ 302 0;
BA_ "GenMsgCycleTime" BO_ 262 20;
BA_ "GenMsgSendType" BO_ 262 0;
BA_ "GenMsgSendType" BO_ 1108 0;
BA_ "GenMsgCycleTime" BO_ 1108 300;
BA_ "GenMsgCycleTime" BO_ 526 20;
BA_ "GenMsgSendType" BO_ 526 0;
BA_ "GenMsgSendType" BO_ 1302 0;
BA_ "GenMsgCycleTime" BO_ 1302 500;
BA_ "GenMsgSendType" BO_ 231 0;
BA_ "GenMsgCycleTime" BO_ 231 10;
BA_ "GenMsgSendType" BO_ 929 0;
BA_ "GenMsgCycleTime" BO_ 929 200;
BA_ "GenMsgSendType" BO_ 806 0;
BA_ "GenMsgCycleTime" BO_ 806 100;
BA_ "GenMsgSendType" BO_ 469 0;
BA_ "GenMsgCycleTime" BO_ 469 20;
BA_ "GenMsgSendType" BO_ 232 0;
BA_ "GenMsgCycleTime" BO_ 232 10;
BA_ "GenMsgSendType" BO_ 199 0;
BA_ "GenMsgCycleTime" BO_ 199 10;
BA_ "GenMsgSendType" BO_ 465 0;
BA_ "GenMsgCycleTime" BO_ 465 20;
BA_ "GenMsgSendType" BO_ 479 0;
BA_ "GenMsgCycleTime" BO_ 479 20;
BA_ "GenMsgSendType" BO_ 423 0;
BA_ "GenMsgCycleTime" BO_ 423 20;
BA_ "GenMsgSendType" BO_ 57 0;
BA_ "GenMsgCycleTime" BO_ 57 40;
BA_ "GenMsgCycleTime" BO_ 773 100;
BA_ "GenMsgSendType" BO_ 773 0;
BA_ "GenMsgCycleTime" BO_ 320 10;
BA_ "GenMsgSendType" BO_ 320 0;
BA_ "GenMsgSendType" BO_ 1928 0;
BA_ "GenMsgSendType" BO_ 148 0;
BA_ "GenMsgCycleTime" BO_ 148 10;
BA_ "GenMsgSendType" BO_ 486 0;
BA_ "GenMsgCycleTime" BO_ 486 20;
BA_ "GenMsgCycleTime" BO_ 330 10;
BA_ "GenMsgSendType" BO_ 330 0;
BA_ "GenMsgCycleTime" BO_ 441 20;
BA_ "GenMsgSendType" BO_ 441 0;
BA_ "PS" BO_ 795 5;
BA_ "GenMsgCycleTime" BO_ 795 100;
BA_ "GenMsgSendType" BO_ 795 0;
BA_ "GenMsgSendType" BO_ 387 0;
BA_ "GenMsgCycleTime" BO_ 387 10;
BA_ "GenMsgSendType" BO_ 419 0;
BA_ "GenMsgCycleTime" BO_ 419 20;
BA_ "GenMsgCycleTime" BO_ 538 40;
BA_ "GenMsgSendType" BO_ 538 0;
BA_ "GenMsgSendType" BO_ 470 0;
BA_ "GenMsgCycleTime" BO_ 470 20;
BA_ "PS" BO_ 422 5;
BA_ "GenMsgCycleTime" BO_ 422 20;
BA_ "GenMsgSendType" BO_ 422 0;
BA_ "GenMsgSendType" BO_ 884 0;
BA_ "GenMsgCycleTime" BO_ 884 100;
BA_ "PS" BO_ 884 5;
BA_ "GenMsgSendType" BO_ 1424 0;
BA_ "GenMsgCycleTime" BO_ 1424 1000;
BA_ "GenMsgSendType" BO_ 661 0;
BA_ "GenMsgCycleTime" BO_ 661 40;
BA_ "PS" BO_ 661 5;
BA_ "GenMsgSendType" BO_ 660 0;
BA_ "GenMsgCycleTime" BO_ 660 40;
BA_ "PS" BO_ 660 5;
BA_ "GenMsgSendType" BO_ 488 0;
BA_ "GenMsgCycleTime" BO_ 488 20;
BA_ "PS" BO_ 426 5;
BA_ "GenMsgCycleTime" BO_ 426 20;
BA_ "GenMsgSendType" BO_ 426 0;
BA_ "GenMsgCycleTime" BO_ 506 20;
BA_ "GenMsgSendType" BO_ 506 0;
BA_ "PS" BO_ 316 5;
BA_ "GenMsgCycleTime" BO_ 316 10;
BA_ "GenMsgSendType" BO_ 316 0;
BA_ "PS" BO_ 985 5;
BA_ "GenMsgCycleTime" BO_ 985 200;
BA_ "GenMsgSendType" BO_ 985 0;
BA_ "PS" BO_ 2564550641 5;
BA_ "GenMsgSendType" BO_ 2564550641 0;
BA_ "PS" BO_ 808 5;
BA_ "GenMsgCycleTime" BO_ 808 100;
BA_ "GenMsgSendType" BO_ 808 0;
BA_ "PS" BO_ 804 5;
BA_ "GenMsgCycleTime" BO_ 804 100;
BA_ "GenMsgSendType" BO_ 804 0;
BA_ "PS" BO_ 472 5;
BA_ "GenMsgCycleTime" BO_ 472 20;
BA_ "GenMsgSendType" BO_ 472 0;
BA_ "GenMsgSendType" BO_ 388 0;
BA_ "GenMsgCycleTime" BO_ 388 10;
BA_ "GenMsgSendType" BO_ 450 0;
BA_ "GenMsgCycleTime" BO_ 450 20;
BA_ "GenMsgSendType" BO_ 274 0;
BA_ "GenMsgCycleTime" BO_ 274 10;
BA_ "PS" BO_ 356 5;
BA_ "GenMsgCycleTime" BO_ 356 10;
BA_ "GenMsgSendType" BO_ 356 0;
BA_ "GenMsgSendType" BO_ 392 0;
BA_ "GenMsgCycleTime" BO_ 392 10;
BA_ "PS" BO_ 392 5;
BA_ "PS" BO_ 401 5;
BA_ "GenMsgCycleTime" BO_ 401 10;
BA_ "GenMsgSendType" BO_ 401 0;
BA_ "PS" BO_ 380 5;
BA_ "GenMsgCycleTime" BO_ 380 10;
BA_ "GenMsgSendType" BO_ 380 0;
BA_ "PS" BO_ 342 5;
BA_ "GenMsgCycleTime" BO_ 342 10;
BA_ "GenMsgSendType" BO_ 342 0;
BA_ "PS" BO_ 304 5;
BA_ "GenMsgCycleTime" BO_ 304 10;
BA_ "GenMsgSendType" BO_ 304 0;
BA_ "GenMsgSendType" BO_ 545 0;
BA_ "GenMsgCycleTime" BO_ 545 40;
BA_ "GenMsgSendType" BO_ 578 0;
BA_ "GenMsgCycleTime" BO_ 578 40;
BA_ "PS" BO_ 1934 5;
BA_ "GenMsgSendType" BO_ 1934 0;
BA_ "GenMsgSendType" BO_ 476 0;
BA_ "GenMsgCycleTime" BO_ 476 20;
BA_ "PS" BO_ 1030 5;
BA_ "GenMsgCycleTime" BO_ 1030 300;
BA_ "GenMsgSendType" BO_ 1030 0;
BA_ "PS" BO_ 597 5;
BA_ "GenMsgCycleTime" BO_ 597 40;
BA_ "GenMsgSendType" BO_ 597 0;
BA_ "PS" BO_ 490 5;
BA_ "GenMsgCycleTime" BO_ 490 20;
BA_ "GenMsgSendType" BO_ 490 0;
BA_ "GenMsgSendType" BO_ 334 0;
BA_ "GenMsgCycleTime" BO_ 334 10;
BA_ "GenMsgSendType" BO_ 1029 0;
BA_ "GenMsgCycleTime" BO_ 1029 300;
BA_ "GenMsgSendType" BO_ 819 0;
BA_ "GenMsgCycleTime" BO_ 819 100;
BA_ "GenMsgSendType" BO_ 487 0;
BA_ "GenMsgCycleTime" BO_ 487 20;
BA_ "PS" BO_ 464 5;
BA_ "GenMsgCycleTime" BO_ 464 20;
BA_ "GenMsgSendType" BO_ 464 0;
BA_ "PS" BO_ 432 5;
BA_ "GenMsgCycleTime" BO_ 432 20;
BA_ "GenMsgSendType" BO_ 432 0;
BA_ "GenMsgSendType" BO_ 150 0;
BA_ "GenMsgCycleTime" BO_ 150 10;
BA_ "PS" BO_ 428 5;
BA_ "GenMsgCycleTime" BO_ 428 20;
BA_ "GenMsgSendType" BO_ 428 0;
BA_ "PS" BO_ 420 5;
BA_ "GenMsgCycleTime" BO_ 420 20;
BA_ "GenMsgSendType" BO_ 420 0;
BA_ "GenMsgSendType" BO_ 411 0;
BA_ "GenMsgCycleTime" BO_ 411 10;
BA_ "PS" BO_ 411 5;
BA_ "PS" BO_ 145 5;
BA_ "GenMsgCycleTime" BO_ 145 10;
BA_ "GenMsgSendType" BO_ 145 0;
BA_ "GenSigInactiveValue" SG_ 3221225472 VSA_INH_MODE6_1 20;
BA_ "GenSigInactiveValue" SG_ 3221225472 VSA_INH_MODE5_1 20;
BA_ "GenSigInactiveValue" SG_ 3221225472 VSA_INH_MODE4_1 20;
BA_ "GenSigInactiveValue" SG_ 3221225472 ENG_CAS_REQ_1 10;
BA_ "GenSigStartValue" SG_ 94 SRS_YAW_1_05E_1 512;
BA_ "GenSigStartValue" SG_ 425 VSA_E4WD_TRQ_LIMITER_REQ_1 255;
BA_ "GenSigStartValue" SG_ 1646 VSA_MCPS_OFFSET_1 7;
BA_ "GenSigInactiveValue" SG_ 1619 VSA_DTC_LOW_BYTE_1 1000;
BA_ "GenSigInactiveValue" SG_ 1619 VSA_DTC_HIGH_BYTE_1 1000;
BA_ "GenSigInactiveValue" SG_ 1619 VSA_CHECKSUM_653 1000;
BA_ "GenSigInactiveValue" SG_ 1619 VSA_ALIVE_COUNTER_653_1 1000;
BA_ "GenSigInactiveValue" SG_ 1619 VSA_DTC_SYSTEM_DESIGNATOR_BIT_1 1000;
BA_ "GenSigInactiveValue" SG_ 1619 VSA_DTC_STORAGE_STATUS_1 1000;
BA_ "GenSigInactiveValue" SG_ 1619 VSA_FTB_STATUS_BIT_1 1000;
BA_ "GenSigInactiveValue" SG_ 1619 VSA_DTC_FTB_1 1000;
BA_ "GenSigInactiveValue" SG_ 546 METER_CHECKSUM_222_1 40;
BA_ "GenSigInactiveValue" SG_ 546 METER_ALIVE_COUNTER_222 40;
BA_ "GenSigInactiveValue" SG_ 546 METER_IDS_MODE_1 40;
BA_ "GenSigInactiveValue" SG_ 845 VSA_CHECKSUM_34D_1 100;
BA_ "GenSigInactiveValue" SG_ 845 VSA_ALIVE_COUNTER_34D_1 100;
BA_ "GenSigInactiveValue" SG_ 845 VSA_VSA_MODE_STATUS_1 100;
BA_ "GenSigInactiveValue" SG_ 446 EBB_IG_ON_1 20;
BA_ "GenSigInactiveValue" SG_ 446 EBB_BRAKE_PEDAL_ON 20;
BA_ "GenSigInactiveValue" SG_ 1108 ENG_CHECKSUM_454_1 300;
BA_ "GenSigInactiveValue" SG_ 1108 ENG_ALIVE_COUNTER_454_1 300;
BA_ "GenSigInactiveValue" SG_ 1108 ENG_FAIL_PA_1 300;
BA_ "GenSigInactiveValue" SG_ 1108 ENG_ATMOSPHERIC_PRESSURE_1 300;
BA_ "GenSigStartValue" SG_ 231 EBB_DRIVER_REQ_STROKE_1 320;
BA_ "GenSigInactiveValue" SG_ 231 EBB_DRIVER_REQ_STROKE_1 10;
BA_ "GenSigStartValue" SG_ 199 VSA_MASTER_CYLINDR_PRESURE_0C7_1 1023;
BA_ "GenSigInactiveValue" SG_ 479 IDAS_CRUISE_ACTIVE 20;
BA_ "GenSigInactiveValue" SG_ 320 ENG_REQUEST_EPB_ACT 10;
BA_ "GenSigInactiveValue" SG_ 148 SRS_POST_COLLISION_BRK_FAILURE_1 10;
BA_ "GenSigInactiveValue" SG_ 148 SRS_POST_COLLISION_BRK_1 10;
BA_ "GenSigStartValue" SG_ 330 EPS_STR_START_UP_1 1;
BA_ "GenSigInactiveValue" SG_ 330 EPS_STR_SPEED_1 10;
BA_ "GenSigInactiveValue" SG_ 795 VSA_REJECT_OFF_SW_OPTN_MID_1 100;
BA_ "GenSigStartValue" SG_ 795 VSA_HDC_DISPLAY_SPEED_TARGET_1 31;
BA_ "GenSigInactiveValue" SG_ 795 VSA_MID_REQUEST_IDS_1 100;
BA_ "GenSigInactiveValue" SG_ 795 VSA_MID_REQUEST_VSA_OFF_1 100;
BA_ "GenSigInactiveValue" SG_ 795 VSA_MID_REQUEST_TCS_OFF_1 100;
BA_ "GenSigInactiveValue" SG_ 795 VSA_MID_REQ_EPB_MISOP_GUIDE_1 100;
BA_ "GenSigInactiveValue" SG_ 795 VSA_MID_LMP_STATS_OPRTE_BHOLD_1 100;
BA_ "GenSigInactiveValue" SG_ 795 VSA_MID_LAMP_STATUS_HDC_OFF_1 100;
BA_ "GenSigInactiveValue" SG_ 795 VSA_WARN_STATUS_HDC_1 100;
BA_ "GenSigInactiveValue" SG_ 795 VSA_MID_WARN_STATUS_TSA_1 100;
BA_ "GenSigStartValue" SG_ 795 VSA_MID_WARN_STATUS_BRAKESYSTM_1 1;
BA_ "DescriptionE" SG_ 795 VSA_ALIVE_COUNTER_31B_1 "Incremented by 1 every time a packet is refreshed.

(0 to 3 ring counters)";
BA_ "GenSigStartValue" SG_ 795 VSA_WARN_STATUS_HSA_31B_1 1;
BA_ "GenSigStartValue" SG_ 795 VSA_MID_WARN_STATUS_BRAKE_1 1;
BA_ "GenSigStartValue" SG_ 795 VSA_MID_WARN_STATUS_ABS_1 1;
BA_ "GenSigStartValue" SG_ 795 VSA_MID_REQUEST_VSA_31B_1 1;
BA_ "GenSigStartValue" SG_ 795 VSA_MID_LAMP_STATUS_VSA_OFF_1 1;
BA_ "GenSigStartValue" SG_ 538 VSA_CALIB_LAT_G_1 512.55230126;
BA_ "GenSigInactiveValue" SG_ 538 VSA_REQ_BRAKERELAY_ACT 40;
BA_ "ValueTableE" SG_ 422 METER_SW_STATUS_HIL_CONTRL_1A6_1 "1: HDC SW ON";
BA_ "ValueTableE" SG_ 422 METER_RL_STATUS_1A6_1 "1: Parking brake SW ON";
BA_ "ValueTableE" SG_ 422 METER_SW_STATUS_VSA_OFF_1A6_1 "1: VSA-off SW ON";
BA_ "ValueTableE" SG_ 422 METER_SW_STATUS_PARK_BRAKE_1A6_1 "1: Parking brake SW ON";
BA_ "ValueTableE" SG_ 422 METER_SW_STATUS_BRKE_FLUID_1A6_1 "1: Brake fluid level SW ON";
BA_ "DescriptionE" SG_ 422 METER_ALIVE_COUNTER_1A6_1 "Incremented by 1 every time a packet is refreshed.

(0 to 3 ring counters)";
BA_ "DescriptionE" SG_ 884 METER_ALIVE_COUNTER_374_1 "Incremented by 1 every time a packet is refreshed.(0 to 3 ring counters)";
BA_ "ValueTableE" SG_ 661 METER_DWS_INIT_REQ_SW_1 "1: Request DWS initialization";
BA_ "ValueTableE" SG_ 661 METER_DWS_INIT_REQ_1 "1: Request DWS initialization";
BA_ "GenSigInactiveValue" SG_ 488 VSA_EPB_MAC_1E8_1 20;
BA_ "GenSigInactiveValue" SG_ 488 VSA_EPB_REQ_TARGET_DECEL_1E8_1 20;
BA_ "GenSigInactiveValue" SG_ 488 VSA_EPB_MESSAGE_COUNTER_1E8_1 20;
BA_ "GenSigInactiveValue" SG_ 488 VSA_EPB_RESET_FLAG_1E8_1 20;
BA_ "GenSigInactiveValue" SG_ 488 VSA_EPB_STATE_1E8_1 20;
BA_ "GenSigInactiveValue" SG_ 488 VSA_EPB_REQ_BRAKE_CTRL_1E8_1 20;
BA_ "GenSigInactiveValue" SG_ 488 VSA_EPB_REFUSE_ACT_1E8_1 20;
BA_ "GenSigInactiveValue" SG_ 488 VSA_EPB_INHIBIT_ACT_1E8_1 20;
BA_ "GenSigInactiveValue" SG_ 426 VSA_IG_ON_1 20;
BA_ "GenSigInactiveValue" SG_ 426 VSA_IDS_INHIBIT_DISABLED_STATE_1 20;
BA_ "GenSigInactiveValue" SG_ 426 VSA_IDS_INHIBIT_ACT_1 20;
BA_ "GenSigInactiveValue" SG_ 426 VSA_EBB_FAILURE_FOR_IS_1 20;
BA_ "GenSigInactiveValue" SG_ 426 VSA_HAC_CUT_REQ_1 20;
BA_ "GenSigInactiveValue" SG_ 426 VSA_HBB_IS_REFUSE_REQ_1 20;
BA_ "GenSigInactiveValue" SG_ 426 VSA_LOW_VAC_IS_SHFT_INHBIT_REQ_1 20;
BA_ "GenSigInactiveValue" SG_ 426 VSA_HBB_IS_SHIFT_INHIBIT_REQ_1 20;
BA_ "GenSigInactiveValue" SG_ 426 VSA_MNTMODE_STATUS_1 20;
BA_ "GenSigInactiveValue" SG_ 426 VSA_REVERSE_SWITCH_FAIL_1 20;
BA_ "GenSigInactiveValue" SG_ 426 VSA_SHFT_IN_REVERSE_1 20;
BA_ "GenSigInactiveValue" SG_ 426 VSA_ECD_ACT_1 20;
BA_ "GenSigInactiveValue" SG_ 426 VSA_FAIL_FOR_EPB_1 20;
BA_ "GenSigInactiveValue" SG_ 426 VSA_REQUEST_EPB_ACT_1 20;
BA_ "GenSigInactiveValue" SG_ 426 VSA_EPB_INHIBIT_BRAKE_1 20;
BA_ "GenSigInactiveValue" SG_ 426 VSA_EPB_REFUSE_BRAKE_1 20;
BA_ "DescriptionE" SG_ 426 VSA_IS_SHFT_INHBIT_REQUEST_1AA_1 "When a side collision is detected, '1' is sent with each message which is output 10 times continuously.";
BA_ "ValueTableE" SG_ 426 VSA_SHIFT_REQ_1AA_1 "0: No shift control request from VSA?(EAT?original control)

1: ?Request shift hold

2: Request upshift

3: Request downshift";
BA_ "DescriptionE" SG_ 426 VSA_SHIFT_REQ_1AA_1 "VSA shift control request

ID:?Valid only when the data of 1AAh 2.1-2.0 VSA_TRQ_CONTROL_MODE is '2.'";
BA_ "ValueTableE" SG_ 426 VSA_TRQ_DOWN_REQ_FUEL_CUT_1AA_1 "0: No fuel/ignition control (THL?control only)

1: Ignition retard

2: ?All cylinders F/C + Ignition?retard";
BA_ "DescriptionE" SG_ 426 VSA_TRQ_DOWN_REQ_FUEL_CUT_1AA_1 "Fuel control request signal

ID:?Valid only when the data of 1AAh 2.1-2.0 VSA_TRQ_CONTROL_MODE is '2.'";
BA_ "DescriptionE" SG_ 426 VSA_ALIVE_COUNTER_1AA_1 "Incremented by 1 every time a packet is refreshed.

(0 to 3 ring counters)";
BA_ "ValueTableE" SG_ 426 VSA_REQ_MSR_PLUS_TRQ_1AA_1 "1: ?Positive torque requested";
BA_ "DescriptionE" SG_ 426 VSA_REQ_MSR_PLUS_TRQ_1AA_1 "MSR?positive torque request flag";
BA_ "ValueTableE" SG_ 426 VSA_TRQ_CONTROL_MODE_1AA_1 "0: VSA/TCS control inactive (normal)

1: Request MSR?control

2: Request acceleration control (This value is set when engine control is required)

3: Inhibit VSA/TCS (VSA?failure)";
BA_ "DescriptionE" SG_ 426 VSA_TRQ_CONTROL_MODE_1AA_1 "Control mode

If the data has remained '3'?for 70 msec, the VSA is judged faulty and no request will be accepted from the VSA?until a reset is performed via IG?operation.";
BA_ "DescriptionE" SG_ 426 VSA_REQ_TRQ_1AA_1 "Indicates the crankshaft torque.

-32768 to 32767 Nm

Indicates the crankshaft torque. ";
BA_ "GenSigStartValue" SG_ 506 ACC_REQ_BRAKERELAY_ACT_1 1;
BA_ "GenSigStartValue" SG_ 506 ACC_TARGET_CALIPER_PRESSURE_FR_1 1020;
BA_ "GenSigStartValue" SG_ 506 ACC_TARGET_CALIPER_PRESSURE_FL_1 1020;
BA_ "GenSigInactiveValue" SG_ 316 ENG_IG1_10V_STATUS_1 10;
BA_ "GenSigInactiveValue" SG_ 316 ENG_CLUTCH_SW_SIL_1 10;
BA_ "ValueTableE" SG_ 316 ENG_NEUTRAL_SENSOR_FAIL_13C_1 "1: NEUTRAL SENSOR FAIL";
BA_ "ValueTableE" SG_ 316 ENG_SHFT_IN_NEUTRAL_13C_1 "*";
BA_ "DescriptionJ" SG_ 316 ENG_SHFT_IN_NEUTRAL_13C_1 "*";
BA_ "GenSigStartValue" SG_ 316 ENG_SHFT_IN_NEUTRAL_13C_1 1;
BA_ "GenSigStartValue" SG_ 316 ENG_SHFT_IN_REVERSE_13C_1 1;
BA_ "DescriptionJ" SG_ 316 ENG_SHFT_IN_REVERSE_13C_1 "*";
BA_ "ValueTableE" SG_ 316 ENG_SHFT_IN_REVERSE_13C_1 "*";
BA_ "ValueTableE" SG_ 316 ENG_CLUTCH_SW_CC_13C_1 "1: Clutch pedal is not depressed(SW ON)

0: Clutch pedal is depressed(SW OFF)";
BA_ "DescriptionE" SG_ 316 ENG_CLUTCH_SW_CC_13C_1 "Clutch sw signal for Cruise control";
BA_ "GenSigStartValue" SG_ 316 ENG_CLUTCH_SW_CC_13C_1 1;
BA_ "ValueTableE" SG_ 316 ENG_VSA_ACK1_13C_1 "0: No fuel/ignition control (THL?control only)

1: Ignition retard

2: ?All cylinders in the F/C mode";
BA_ "DescriptionE" SG_ 316 ENG_VSA_ACK1_13C_1 "Response to VSA fuel control request";
BA_ "ValueTableE" SG_ 316 ENG_VSA_PERMIT_PLUS_TRQ_13C_1 "1: Positive torque permitted";
BA_ "DescriptionE" SG_ 316 ENG_VSA_PERMIT_PLUS_TRQ_13C_1 "MSR?positive torque permission flag";
BA_ "DescriptionE" SG_ 316 ENG_ALIVE_COUNTER_13C_1 "Incremented by 1 every time a packet is refreshed.

(0 to 3 ring counters)";
BA_ "ValueTableE" SG_ 316 ENG_RECEIVE_ERROR_1AA_1 "1: Reception error detected";
BA_ "DescriptionE" SG_ 316 ENG_RECEIVE_ERROR_1AA_1 "Flag indicating whether or not a reception error is present

ID:?'1'?if at least one of the 1AAh alive counter refresh error, checksum error or timeout has continued for 60 msec.";
BA_ "ValueTableE" SG_ 316 ENG_VSA_INHIBIT_VSA_CONTRL_13C_1 "1: VSA F/Ccontrol temporarily stopped";
BA_ "DescriptionE" SG_ 316 ENG_VSA_INHIBIT_VSA_CONTRL_13C_1 "VSA control permission/inhibition information";
BA_ "ValueTableE" SG_ 316 ENG_VSA_REFUSED_VSA_CONTRL_13C_1 "1: Failure that disables VSA control is present";
BA_ "DescriptionE" SG_ 316 ENG_VSA_REFUSED_VSA_CONTRL_13C_1 "VSA control permission/inhibition information";
BA_ "DescriptionE" SG_ 316 ENG_SMART_ACCELE_PEDAL_POS_13C_1 "Acceleration pedal position (%)

( at the time of a Smart Pedal System Application )";
BA_ "DescriptionE" SG_ 316 ENG_DRIVER_REQ_TRQ_13C_1 "Indicates the driver-requested crankshaft driving torque.

Cruise-requested crankshaft driving torque during cruise control.";
BA_ "DescriptionE" SG_ 316 ENG_ENG_TRQ_13C_1 "Indicates the crankshaft torque.

-32768 to 32767 Nm";
BA_ "DescriptionE" SG_ 985 VSA_ALIVE_COUNTER_3D9_1 "Incremented by 1 every time a packet is refreshed.

(0 to 3 ring counters)";
BA_ "ValueTableE" SG_ 985 VSA_STABILITY_CTRL1_DSABLE_EDR_1 "0: STABILITY CONTROL1 ENABLE

1: STABILITY CONTROL1 DISABLE";
BA_ "ValueTableE" SG_ 985 VSA_STABILITY_CTRL2_DSABLE_EDR_1 "0: STABILITY CONTROL2 ENABLE

1: STABILITY CONTROL2 DISABLE";
BA_ "DescriptionE" SG_ 2564550641 HDS_HDC_CAN_1 "Data frame for failure diagnosis/reprogramming

Refer to 'Function Request for ECU Not Implementing HDC_CAN Protocol.'";
BA_ "DescriptionE" SG_ 808 ENG_ALIVE_COUNTER_328_1 "Incremented by 1 every time a packet is refreshed.

(0 to 3 ring counters)";
BA_ "DescriptionE" SG_ 808 ENG_STRNNEND_1 "Engine complete combustion judgment flag";
BA_ "ValueTableE" SG_ 808 ENG_STRNNEND_1 "1: Complete combustion";
BA_ "GenSigInactiveValue" SG_ 804 ENG_ENG_COOLANT_TEMP_1 100;
BA_ "GenSigStartValue" SG_ 804 ENG_ENG_COOLANT_TEMP_1 255;
BA_ "DescriptionE" SG_ 804 ENG_ALIVE_COUNTER_324_1 "Incremented by 1 every time a packet is refreshed.

(0 to 3 ring counters)";
BA_ "ValueTableE" SG_ 804 ENG_SW_STATUS_SCS_1 "1: SCS SW ON";
BA_ "DescriptionJ" SG_ 472 SS30_SYSTEM_ACT_1 "*";
BA_ "DescriptionE" SG_ 472 SS30_SYSTEM_ACT_1 "0";
BA_ "DescriptionE" SG_ 472 SS30_ALIVE_COUNTER_1D8_1 "Incremented by 1 every time a packet is refreshed.

(0 to 3 ring counters)";
BA_ "DescriptionE" SG_ 472 SS30_STATUS_FAIL_1 "0";
BA_ "GenSigInactiveValue" SG_ 388 ESB_IG_ON_1 10;
BA_ "GenSigInactiveValue" SG_ 450 EPB_FAIL_1 20;
BA_ "GenSigInactiveValue" SG_ 356 METER_SW_STATUS_BHOLD_SENKOSYA_1 10;
BA_ "DescriptionE" SG_ 356 METER_ALIVE_COUNTER_164_1 "Incremented by 1 every time a packet is refreshed.

(0 to 3 ring counters)";
BA_ "ValueTableE" SG_ 356 METER_SW_STATUS_PARK_BRAKE_1 "1: Parking brake SW ON";
BA_ "ValueTableE" SG_ 356 METER_SW_STATUS_BRAKE_FLUID_1 "1: Brake fluid level SW ON";
BA_ "ValueTableE" SG_ 356 METER_SW_STATUS_VSA_OFF_1 "1: VSA-off SW ON";
BA_ "GenSigInactiveValue" SG_ 392 EAT_SW_STATUS_SMODE 10;
BA_ "ValueTableE" SG_ 392 EAT_SHFT_IN_PARKING_1 "1: 'P'";
BA_ "ValueTableE" SG_ 392 EAT_SHFT_IN_REVERSE_1 "1: 'R'";
BA_ "ValueTableE" SG_ 392 EAT_SHFT_IN_NEUTRAL_1 "1: 'N'";
BA_ "ValueTableE" SG_ 392 EAT_SHFT_IN_D_1 "1: 'D'";
BA_ "ValueTableE" SG_ 392 EAT_SHFT_IN_D4_1 "1: 'D4'";
BA_ "ValueTableE" SG_ 392 EAT_SHFT_IN_D3_1 "1: 'D3'";
BA_ "ValueTableE" SG_ 392 EAT_SHFT_IN_2_1 "1: '2' or 'L'";
BA_ "ValueTableE" SG_ 392 EAT_SHFT_IN_1_1 "1: '1'";
BA_ "ValueTableE" SG_ 392 EAT_FAILURE_FOR_VSA_1 "1: AT failure that disables VSA control is present";
BA_ "ValueTableE" SG_ 392 EAT_GEAR_POSITION_TARGET_1 "0: Neutral

1: 1st

2: 2nd

3: 3rd

4: 4th

5: 5th

6: Reverse

7: 6th";
BA_ "ValueTableE" SG_ 392 EAT_GEAR_POSITION_ACTUAL_1 "0: Neutral

1: 1st

2: 2nd

3: 3rd

4: 4th

5: 5th

6: Reverse

7: Shifting 

8: 6th";
BA_ "GenSigStartValue" SG_ 401 CVT_SW_STATUS_SMODE_1 1;
BA_ "ValueTableE" SG_ 401 CVT_CAS_ON_1 "1: CAS_ONrequest to VSA";
BA_ "DescriptionE" SG_ 401 CVT_ALIVE_COUNTER_191_1 "Incremented by 1 every time a packet is refreshed.

(0 to 3 ring counters)";
BA_ "DescriptionE" SG_ 401 CVT_RATIO_TARGET_1 "Target ratio information";
BA_ "GenSigStartValue" SG_ 401 CVT_RATIO_TARGET_1 64;
BA_ "DescriptionE" SG_ 401 CVT_RATIO_INFO_191_1 "Ratio information";
BA_ "GenSigStartValue" SG_ 401 CVT_RATIO_INFO_191_1 64;
BA_ "ValueTableE" SG_ 401 CVT_REFUSE_VSA_CONTROL_1 "1: CVTfailure that disables VSA control is present";
BA_ "DescriptionE" SG_ 401 CVT_GEAR_POSITION_IND_CVT_1 "Shift position indication for S-Matic

For S-Matic LED indication

8-E: OFF";
BA_ "ValueTableE" SG_ 401 CVT_GEAR_POSITION_IND_CVT_1 "0: OFF

1: 1st

2: 2nd

3: 3rd

4: 4th

5: 5th

6: 6th

7: 7th

8: 8th

F: ?L range control active";
BA_ "DescriptionE" SG_ 401 CVT_SHFT_IN_PARKING_1 "Select lever position";
BA_ "ValueTableE" SG_ 401 CVT_SHFT_IN_PARKING_1 "1: Parking";
BA_ "DescriptionE" SG_ 401 CVT_SHFT_IN_REVERSE_1 "Select lever position";
BA_ "ValueTableE" SG_ 401 CVT_SHFT_IN_REVERSE_1 "1: Reverse";
BA_ "DescriptionE" SG_ 401 CVT_SHFT_IN_NEUTRAL_1 "Select lever position";
BA_ "ValueTableE" SG_ 401 CVT_SHFT_IN_NEUTRAL_1 "1: Neutral";
BA_ "DescriptionE" SG_ 401 CVT_SHFT_IN_D_1 "Select lever position";
BA_ "ValueTableE" SG_ 401 CVT_SHFT_IN_D_1 "1: 'D'";
BA_ "DescriptionE" SG_ 401 CVT_SHFT_IN_S_1 "Select lever position

Meter 'S' lighting information

* S lighting information under the following two specifications

- 'S range' on the shift lever

 - 'Sports mode (SPO-IND)' effected by the S SW?";
BA_ "ValueTableE" SG_ 401 CVT_SHFT_IN_S_1 "1: 'S'";
BA_ "DescriptionE" SG_ 401 CVT_SHFT_IN_L_1 "Select lever position";
BA_ "ValueTableE" SG_ 401 CVT_SHFT_IN_L_1 "1: 'L'";
BA_ "DescriptionE" SG_ 380 ENG_CRUISE_STATUS_CRUISE_INH_1 "Indicates inhibition of cruise control.";
BA_ "DescriptionE" SG_ 380 ENG_ALIVE_COUNTER_17C_1 "Incremented by 1 every time a packet is refreshed.

(0 to 3 ring counters)";
BA_ "ValueTableE" SG_ 380 ENG_IS_PROGRESS_1 "1: Idle stop control started or in progress";
BA_ "DescriptionE" SG_ 380 ENG_SW_STATUS_BRAKE_NO_1 "The brake switch NO indicates the brake mode.

(SW ON)";
BA_ "ValueTableE" SG_ 380 ENG_CRUISE_STATUS_CRUISE_LMP_1 "1: Cruise control lamp ON";
BA_ "DescriptionE" SG_ 380 ENG_ENG_SPEED_1 "Engine speed

0 to 15000 rpm";
BA_ "GenSigInactiveValue" SG_ 342 STR_TRIM_1 10;
BA_ "DescriptionE" SG_ 342 STR_ALIVE_COUNTER_156_1 "Incremented by 1 every time a packet is refreshed.

(0 to 3 ring counters)";
BA_ "DescriptionE" SG_ 342 STR_OK_1 "OK flag: Indicates that the sensor is normal.

- 1 is output when normal.";
BA_ "GenSigStartValue" SG_ 342 STR_OK_1 1;
BA_ "DescriptionE" SG_ 342 STR_CAL_1 "Calibration flag:?Indicates whether or not zero is set.

- 1 is output when set.

Becomes '1'?if zero is set after installation on the vehicle.";
BA_ "GenSigStartValue" SG_ 342 STR_CAL_1 1;
BA_ "DescriptionE" SG_ 342 STR_ANGLE_1 "Steering angle signal";
BA_ "ValueTableE" SG_ 342 STR_ANGLE_1 "E278: -756[deg]

0000: 0[deg]

1D88: +756[deg]

7FFF: Invalid";
BA_ "GenSigInactiveValue" SG_ 304 ENG_CLUTCH_SW_SIL_1 10;
BA_ "GenSigInactiveValue" SG_ 304 ENG_EV_DRIVE_STATE_1 10;
BA_ "GenSigStartValue" SG_ 304 ENG_SHFT_IN_REVERSE_1 1;
BA_ "DescriptionJ" SG_ 304 ENG_SHFT_IN_REVERSE_1 "*";
BA_ "DescriptionE" SG_ 304 ENG_SHFT_IN_REVERSE_1 "*";
BA_ "ValueTableE" SG_ 304 ENG_SHFT_IN_REVERSE_1 "*";
BA_ "DescriptionE" SG_ 304 ENG_ALIVE_COUNTER_130_1 "Incremented by 1 every time a packet is refreshed.

(0 to 3 ring counters)";
BA_ "ValueTableE" SG_ 304 ENG_NEUTRAL_SENSOR_FAIL_1 "1: NEUTRAL SENSOR FAIL";
BA_ "DescriptionE" SG_ 304 ENG_RECEIVE_ERROR_1AC_1 "Flag indicating whether or not a reception error is present

ID:?'1'?if at least one of the 1AAh alive counter refresh error, checksum error or timeout has continued for 60 msec.";
BA_ "ValueTableE" SG_ 304 ENG_RECEIVE_ERROR_1AC_1 "1: Reception error detected";
BA_ "ValueTableE" SG_ 304 ENG_SHFT_IN_NEUTRAL_1 "1: SHIFT LEVER IS IN NEUTRAL";
BA_ "DescriptionE" SG_ 304 ENG_CLUTCH_SW_CC_1 "Clutch sw signal for Cruise control";
BA_ "ValueTableE" SG_ 304 ENG_CLUTCH_SW_CC_1 "1: Clutch pedal is not depressed(SW ON)

0: Clutch pedal is depressed(SW OFF)";
BA_ "GenSigStartValue" SG_ 304 ENG_CLUTCH_SW_CC_1 1;
BA_ "DescriptionE" SG_ 304 ENG_VSA_ACK1_1 "Response to VSA fuel control request";
BA_ "ValueTableE" SG_ 304 ENG_VSA_ACK1_1 "0: No fuel/ignition control (THL?control only)

1: Ignition retard

2: ?All cylinders in the F/C mode";
BA_ "DescriptionE" SG_ 304 ENG_VSA_PERMIT_PLUS_TRQ_1 "MSR?positive torque permission flag";
BA_ "ValueTableE" SG_ 304 ENG_VSA_PERMIT_PLUS_TRQ_1 "1: Positive torque permitted";
BA_ "DescriptionE" SG_ 304 ENG_VSA_INHIBIT_VSA_CONTROL_1_1 "VSA control permission/inhibition information";
BA_ "ValueTableE" SG_ 304 ENG_VSA_INHIBIT_VSA_CONTROL_1_1 "1: VSA F/Ccontrol temporarily stopped";
BA_ "DescriptionE" SG_ 304 ENG_VSA_REFUSED_VSA_CONTROL_1_1 "VSA control permission/inhibition information";
BA_ "ValueTableE" SG_ 304 ENG_VSA_REFUSED_VSA_CONTROL_1_1 "1: Failure that disables VSA control is present";
BA_ "DescriptionE" SG_ 304 ENG_SMART_ACCELE_PEDAL_POS_1 "Acceleration pedal position (%)

( at the time of a Smart Pedal System Application )";
BA_ "DescriptionE" SG_ 304 ENG_DRIVER_REQ_TRQ_130_1 "Indicates the driver-requested crankshaft driving torque.

Cruise-requested crankshaft driving torque during cruise control.";
BA_ "GenSigStartValue" SG_ 304 ENG_DRIVER_REQ_TRQ_130_1 32767;
BA_ "DescriptionE" SG_ 304 ENG_ENG_TRQ_130_1 "Indicates the crankshaft torque.

-32768 to 32767 Nm";
BA_ "GenSigStartValue" SG_ 304 ENG_ENG_TRQ_130_1 32767;
BA_ "GenSigInactiveValue" SG_ 545 METER_ECONSW_ON_1 40;
BA_ "ValueTableE" SG_ 1934 VSA_COMMAND_CODE_1 "3: Calibration

5: Reset of the Calibration";
BA_ "DescriptionE" SG_ 1030 VSA_ALIVE_COUNTER_406_1 "Incremented by 1 every time a packet is refreshed.

(0 to 3 ring counters)";
BA_ "GenSigStartValue" SG_ 1030 VSA_SPECIFY_CODE_SYS_1 1;
BA_ "DescriptionE" SG_ 597 VSA_ABS_CHECKSUM_255_1 "CAN checksum for ESL?(255h)";
BA_ "DescriptionE" SG_ 597 VSA_ABS_ALIVE_COUNTER_255_1 "CAN alive counter for ESL";
BA_ "DescriptionE" SG_ 597 VSA_ABS_SPEED_FIXED_NUMBER2_1 "Fixed checksum value (ESL)

A fixed value of 0x55 is sent (also in the initial state).";
BA_ "GenSigStartValue" SG_ 597 VSA_ABS_SPEED_FIXED_NUMBER2_1 85;
BA_ "DescriptionE" SG_ 597 VSA_ABS_SPEED_FIXED_NUMBER1_1 "Fixed checksum value (ESL)

A fixed value of 0x55 is sent (also in the initial state).";
BA_ "GenSigStartValue" SG_ 597 VSA_ABS_SPEED_FIXED_NUMBER1_1 85;
BA_ "DescriptionE" SG_ 597 VSA_ABS_RR_WHEEL_SPEED_255_1 "Right rear wheel speed  If failure occurs value is converted directly to speed. 

FFh shall be sent if the measured value has overflowed due to an open failure.

If Noise causes high vehicle speed shall be sent but, upper limit is clipped at 250 km/h.";
BA_ "GenSigStartValue" SG_ 597 VSA_ABS_RR_WHEEL_SPEED_255_1 250;
BA_ "DescriptionE" SG_ 597 VSA_ABS_RL_WHEEL_SPEED_255_1 "Left rear wheel speed  If failure occurs value is converted directly to speed. 

FFh shall be sent if the measured value has overflowed due to an open failure.

If Noise causes high vehicle speed shall be sent but, upper limit is clipped at 250 km/h.";
BA_ "GenSigStartValue" SG_ 597 VSA_ABS_RL_WHEEL_SPEED_255_1 250;
BA_ "DescriptionE" SG_ 597 VSA_ABS_FR_WHEEL_SPEED_255_1 "Right front wheel speed If failure occurs value is converted directly to speed. 

FFh shall be sent if the measured value has overflowed due to an open failure.

If Noise causes high vehicle speed shall be sent but, upper limit is clipped at 250 km/h.";
BA_ "GenSigStartValue" SG_ 597 VSA_ABS_FR_WHEEL_SPEED_255_1 250;
BA_ "DescriptionE" SG_ 597 VSA_ABS_FL_WHEEL_SPEED_255_1 "Left front wheel speed If failure occurs value is converted directly to speed. 

FFh shall be sent if the measured value has overflowed due to an open failure.

If Noise causes high vehicle speed shall be sent but, upper limit is clipped at 250 km/h.

";
BA_ "GenSigStartValue" SG_ 597 VSA_ABS_FL_WHEEL_SPEED_255_1 250;
BA_ "DescriptionE" SG_ 490 VSA_ALIVE_COUNTER_1EA_1 "Incremented by 1 every time a packet is refreshed.

(0 to 3 ring counters)";
BA_ "DescriptionE" SG_ 490 VSA_MAEPS_REVERSE_F_1 "VSA status signal 1";
BA_ "ValueTableE" SG_ 490 VSA_MAEPS_REVERSE_F_1 "1: Reverse";
BA_ "DescriptionE" SG_ 490 VSA_SYSTEM_F_1 "VSA status signal 3";
BA_ "ValueTableE" SG_ 490 VSA_SYSTEM_F_1 "1: VSA system failure";
BA_ "DescriptionE" SG_ 490 VSA_MAEPS_MYU_VALUE_1 "m ratio signal";
BA_ "DescriptionE" SG_ 490 VSA_MAEPS_GX_VALUE_1 "Estimate vehicle front/rear G signal";
BA_ "DescriptionE" SG_ 490 VSA_MAEPS_US_VALUE_1 "Yaw rate deviation signal";
BA_ "GenSigInactiveValue" SG_ 819 TPMS_WARN_STATUS_SYSTEM_1 100;
BA_ "GenSigStartValue" SG_ 487 VSA_CALIPPER_PRESSURE_FR_1 102;
BA_ "GenSigStartValue" SG_ 487 VSA_CALIPPER_PRESSURE_FL_1 102;
BA_ "DescriptionE" SG_ 464 VSA_ABS_RR_WHEEL_SPEED_1 "Right rear wheel speed

0~300 km/h

CAN outputs failed value even when sensor failure occurs. 

When Open 0000h shall be sent in overflow condition. If noise causes high vehicle speed the measured vehicle speed shall be sent but, upper limit is 300 km/h.";
BA_ "DescriptionE" SG_ 464 VSA_ABS_RL_WHEEL_SPEED_1 "Left rear wheel speed

0~300 km/h

CAN outputs failed value even when sensor failure occurs. 

When Open 0000h shall be sent in overflow condition. If noise causes high vehicle speed the measured vehicle speed shall be sent but, upper limit is 300 km/h.";
BA_ "DescriptionE" SG_ 464 VSA_ABS_FR_WHEEL_SPEED_1 "Right front wheel speed

0~300 km/h

CAN outputs failed value even when sensor failure occurs. 

When Open 0000h shall be sent in overflow condition. If noise causes high vehicle speed the measured vehicle speed shall be sent but, upper limit is 300 km/h";
BA_ "DescriptionE" SG_ 464 VSA_ABS_FL_WHEEL_SPEED_1 "Left front wheel speed 

0~300 km/h

CAN outputs failed value even when sensor failure occurs. 

When Open 0000h shall be sent in overflow condition. If noise causes high vehicle speed the measured vehicle speed shall be sent but, upper limit is 300 km/h";
BA_ "GenSigInactiveValue" SG_ 432 VSA_PLANT_INSPECTION_STATUS_1 20;
BA_ "GenSigStartValue" SG_ 432 VSA_PLANT_INSPECTION_STATUS_1 1;
BA_ "GenSigInactiveValue" SG_ 432 VSA_ABS_BUSY_1 20;
BA_ "GenSigStartValue" SG_ 432 VSA_ABS_ENB_VW_SENSOR_ACT_1 1;
BA_ "ValueTableE" SG_ 432 VSA_FAIL_LONG_G_SENSOR_1 "1: Fail LON G";
BA_ "DescriptionE" SG_ 432 VSA_ALIVE_COUNTER_1B0_1 "Incremented by 1 every time a packet is refreshed.

(0 to 3 ring counters)";
BA_ "DescriptionE" SG_ 432 VSA_REQ_CVT_TCS_1 "CVT?control request

CVT?coordination control request signal";
BA_ "ValueTableE" SG_ 432 VSA_REQ_CVT_TCS_1 "1: ?TCS operation permitted";
BA_ "DescriptionE" SG_ 432 VSA_REQ_CVT_PRS_1 "CVT?control request

CVT?coordination control request signal";
BA_ "ValueTableE" SG_ 432 VSA_REQ_CVT_PRS_1 "1: ?Pressurizing";
BA_ "DescriptionE" SG_ 432 VSA_CONTROL_MODE_CVT_1 "CVT?coordination control mode

Dedicated CVT?coordination control mode";
BA_ "ValueTableE" SG_ 432 VSA_CONTROL_MODE_CVT_1 "0: VSA control ready

1: ?TCS active

2: Reserved

3: Reserved";
BA_ "ValueTableE" SG_ 432 VSA_ABS_STATUS_FR_ABS_EBD_ACT_1 "1: ?FR?wheel ABS, EBD active";
BA_ "ValueTableE" SG_ 432 VSA_ABS_STATUS_FL_ABS_EBD_ACT_1 "1: ?FL?wheel ABS, EBD active";
BA_ "ValueTableE" SG_ 432 VSA_ABS_STATUS_RR_ABS_EBD_ACT_1 "1: ?RR?wheel ABS, EBD active";
BA_ "ValueTableE" SG_ 432 VSA_ABS_STATUS_RL_ABS_EBD_ACT_1 "1: ?RL?wheel ABS, EBD active";
BA_ "ValueTableE" SG_ 432 VSA_FAIL_YAW_RATE_SENSOR_1 "1: Yaw rate sensor error";
BA_ "ValueTableE" SG_ 432 VSA_ABS_FAIL_FR_VW_SENSOR_1 "1: ?Wheel speed sensor; FR?wheel error";
BA_ "ValueTableE" SG_ 432 VSA_ABS_FAIL_FL_VW_SENSOR_1 "1: ?Wheel speed sensor; FL?wheel error";
BA_ "ValueTableE" SG_ 432 VSA_ABS_FAIL_RR_VW_SENSOR_1 "1: ?Wheel speed sensor; RR?wheel error";
BA_ "ValueTableE" SG_ 432 VSA_ABS_FAIL_RL_VW_SENSOR_1 "1: ?Wheel speed sensor; RL?wheel error";
BA_ "DescriptionE" SG_ 432 VSA_ACC_INHIBIT_CVRS_BRAKE_1 "ACC brake control inhibition information

The default value is sent if there is no ACC.";
BA_ "ValueTableE" SG_ 432 VSA_ACC_INHIBIT_CVRS_BRAKE_1 "1: Temporarily inhibit CVRS brake";
BA_ "GenSigStartValue" SG_ 432 VSA_ACC_INHIBIT_CVRS_BRAKE_1 1;
BA_ "DescriptionE" SG_ 432 VSA_ACC_REFUSE_CVRS_BRAKE_1 "ACC brake control inhibition information

The default value is sent if there is no ACC.";
BA_ "ValueTableE" SG_ 432 VSA_ACC_REFUSE_CVRS_BRAKE_1 "1: ?Failure that disables CVRS brake occurred";
BA_ "GenSigStartValue" SG_ 432 VSA_ACC_REFUSE_CVRS_BRAKE_1 1;
BA_ "DescriptionE" SG_ 432 VSA_VW_PULSE_CAPTURED_1 "Wheel speed pulse generation flag

The flag is set to '1' if a wheel speed pulse has generated at least once between the last transmission and this transmission.";
BA_ "ValueTableE" SG_ 432 VSA_VW_PULSE_CAPTURED_1 "1: Wheel speed pulse available";
BA_ "DescriptionE" SG_ 432 VSA_INHBIT_YAW_RATE_SENSOR_1 "When a side collision is detected, '1' is sent with each message which is output 10 times continuously.";
BA_ "GenSigStartValue" SG_ 150 VSA_YAW_2_1 512;
BA_ "GenSigInactiveValue" SG_ 428 VSA_IG_ON_1 20;
BA_ "GenSigInactiveValue" SG_ 428 VSA_EBB_FAILURE_FOR_IS_1 20;
BA_ "GenSigInactiveValue" SG_ 428 VSA_IDS_INHIBIT_DISABLED_STATE_1 20;
BA_ "GenSigInactiveValue" SG_ 428 VSA_IDS_INHIBIT_ACT_1 20;
BA_ "GenSigInactiveValue" SG_ 428 VSA_HAC_CUT_REQ_1 20;
BA_ "GenSigInactiveValue" SG_ 428 VSA_HBB_IS_REFUSE_REQ_1 20;
BA_ "GenSigInactiveValue" SG_ 428 VSA_LOW_VAC_IS_SHFT_INHBIT_REQ_1 20;
BA_ "GenSigInactiveValue" SG_ 428 VSA_MNTMODE_STATUS_1 20;
BA_ "GenSigInactiveValue" SG_ 428 VSA_REVERSE_SWITCH_FAIL_1 20;
BA_ "GenSigInactiveValue" SG_ 428 VSA_SHFT_IN_REVERSE_1 20;
BA_ "GenSigInactiveValue" SG_ 428 VSA_ECD_ACT_1 20;
BA_ "GenSigInactiveValue" SG_ 428 VSA_FAIL_FOR_EPB_1 20;
BA_ "GenSigInactiveValue" SG_ 428 VSA_REQUEST_EPB_ACT_1 20;
BA_ "GenSigInactiveValue" SG_ 428 VSA_EPB_INHIBIT_BRAKE_1 20;
BA_ "GenSigInactiveValue" SG_ 428 VSA_HBB_IS_SHIFT_INHIBIT_REQ_1 20;
BA_ "GenSigInactiveValue" SG_ 428 VSA_EPB_REFUSE_BRAKE_1 20;
BA_ "GenSigInactiveValue" SG_ 428 VSA_TSA_ACT_1 20;
BA_ "DescriptionE" SG_ 428 VSA_IS_SHIFT_INHIBIT_REQUEST_1_1 "When a side collision is detected, '1' is sent with each message which is output 10 times continuously.";
BA_ "DescriptionE" SG_ 428 VSA_SHIFT_REQ_1AC_1 "VSA shift control request

ID:?Valid only when the data of 1AAh 2.1-2.0 VSA_TRQ_CONTROL_MODE is '2.'";
BA_ "ValueTableE" SG_ 428 VSA_SHIFT_REQ_1AC_1 "0: No shift control request from VSA?(EAT?original control)

1: ?Request shift hold

2: Request upshift

3: Request downshift";
BA_ "DescriptionE" SG_ 428 VSA_ALIVE_COUNTER_1AC_1 "Incremented by 1 every time a packet is refreshed.

(0 to 3 ring counters)";
BA_ "DescriptionE" SG_ 428 VSA_REQ_TRQ_1AC_1 "Indicates the crankshaft torque.

-32768 to 32767 Nm

Indicates the crankshaft torque. ";
BA_ "GenSigStartValue" SG_ 428 VSA_REQ_TRQ_1AC_1 32767;
BA_ "DescriptionE" SG_ 428 VSA_REQ_MSR_PLUS_TRQ_1 "MSR?positive torque request flag";
BA_ "ValueTableE" SG_ 428 VSA_REQ_MSR_PLUS_TRQ_1 "1: ?Positive torque requested";
BA_ "DescriptionE" SG_ 428 VSA_TRQ_CONTROL_MODE_1 "Control mode

If the data has remained '3'?for 70 msec, the VSA is judged faulty and no request will be accepted from the VSA?until a reset is performed via IG?operation.";
BA_ "ValueTableE" SG_ 428 VSA_TRQ_CONTROL_MODE_1 "0: VSA/TCS control inactive (normal)

1: Request MSR?control

2: Request acceleration control (This value is set when engine control is required)

3: Inhibit VSA/TCS (VSA?failure)";
BA_ "DescriptionE" SG_ 428 VSA_TRQ_DOWN_REQ_FUEL_CUT_1 "Fuel control request signal

ID:?Valid only when the data of 1AAh 2.1-2.0 VSA_TRQ_CONTROL_MODE is '2.'";
BA_ "ValueTableE" SG_ 428 VSA_TRQ_DOWN_REQ_FUEL_CUT_1 "0: No fuel/ignition control (THL?control only)

1: Ignition retard

2: ?All cylinders F/C + Ignition?retard";
BA_ "GenSigInactiveValue" SG_ 420 VSA_VSA_OS_CTRL_1 20;
BA_ "GenSigInactiveValue" SG_ 420 VSA_ESB_INCREASE_PRESS_ACT_1 20;
BA_ "ValueTableE" SG_ 420 VSA_LAMP_STATUS_VSA_OFF_TFT_1 "1: TSA warning is illuminated";
BA_ "ValueTableE" SG_ 420 VSA_WARN_STATUS_BRAKESYSTEM_1 "1: Brakesystem Warning Lamp ON";
BA_ "DescriptionE" SG_ 420 VSA_WARN_STATUS_BRAKESYSTEM_1 "Brakesystem Warning Lamp Status";
BA_ "ValueTableE" SG_ 420 VSA_LAMP_STATUS_HDC_1 "1: HDC Standby";
BA_ "DescriptionE" SG_ 420 VSA_LAMP_STATUS_HDC_1 "HDC Control Status";
BA_ "GenSigStartValue" SG_ 420 VSA_LAMP_STATUS_HDC_1 1;
BA_ "ValueTableE" SG_ 420 VSA_WARN_STATUS_HDC_1 "1: HDC MID warning ON";
BA_ "DescriptionE" SG_ 420 VSA_WARN_STATUS_HDC_1 "HDC Warn Status";
BA_ "ValueTableE" SG_ 420 VSA_AHA_CTRL_1 "1: DWTB CTRL Active";
BA_ "DescriptionE" SG_ 420 VSA_AHA_CTRL_1 "DWTB Control Active";
BA_ "GenSigStartValue" SG_ 420 VSA_AHA_CTRL_1 1;
BA_ "ValueTableE" SG_ 420 VSA_WARN_STATUS_PUNCTURE_1 "1: ABS control active";
BA_ "ValueTableE" SG_ 420 VSA_WARN_STATUS_DWS_1 "1: ABS control active";
BA_ "ValueTableE" SG_ 420 VSA_ANSWER_DWS_INIT_REQ_1 "1: ABS control active";
BA_ "ValueTableE" SG_ 420 VSA_L_MODE_ABS_EBD_1 "1: ABS, EBD L-MODE";
BA_ "DescriptionE" SG_ 420 VSA_ALIVE_COUNTER_1A4_1 "Incremented by 1 every time a packet is refreshed.

(0 to 3 ring counters)";
BA_ "ValueTableE" SG_ 420 VSA_ABS_CTRL_1 "1: ABS control active";
BA_ "ValueTableE" SG_ 420 VSA_VSA_CTRL_1 "1: VSA control active";
BA_ "ValueTableE" SG_ 420 VSA_WARN_STATUS_HSA_1 "1: HSA warning is illuminated";
BA_ "DescriptionE" SG_ 420 VSA_ESS_ACT4_1 "When a head-on collision is detected, '1' is sent with each message which is output 10 times continuously.";
BA_ "ValueTableE" SG_ 420 VSA_ESS_ACT4_1 "0: The continuation of an operation of ESS by ABS full cycle is forbidden.

1: The continuation of an operation of ESS by ABS full cycle is permitted.";
BA_ "ValueTableE" SG_ 420 VSA_ESS_ACT3_1 "0: The operation start of ESS by  ABS full cycle is forbidden.

1: The operation start of ESS by  ABS full cycle is permitted.";
BA_ "DescriptionE" SG_ 420 VSA_REWRITE_START_1 "VSA ECU reprogramming start flag";
BA_ "ValueTableE" SG_ 420 VSA_REWRITE_START_1 "1: Start VSA reprogramming at dealer";
BA_ "ValueTableE" SG_ 420 VSA_BUZZER_STATUS_1 "0: Buzzer OFF

1: Buzzer ON";
BA_ "DescriptionE" SG_ 420 VSA_MID_REQUEST_VSA_1 "VSA MID enlarged warning output flag ";
BA_ "ValueTableE" SG_ 420 VSA_MID_REQUEST_VSA_1 "1: Display VSA MID enlarged warning";
BA_ "ValueTableE" SG_ 420 VSA_LAMP_STATUS_VSA_OFF_1 "1: VSA OFF lamp ON";
BA_ "GenSigStartValue" SG_ 420 VSA_LAMP_STATUS_VSA_OFF_1 1;
BA_ "ValueTableE" SG_ 420 VSA_WARN_STATUS_VSA_1 "1: VSA warning lamp ON";
BA_ "GenSigStartValue" SG_ 420 VSA_WARN_STATUS_VSA_1 1;
BA_ "ValueTableE" SG_ 420 VSA_WARN_STATUS_ABS_1 "1: ABS warning lamp ON";
BA_ "GenSigStartValue" SG_ 420 VSA_WARN_STATUS_ABS_1 1;
BA_ "ValueTableE" SG_ 420 VSA_WARN_STATUS_BRAKE_1 "1: Brake warning lamp ON";
BA_ "GenSigStartValue" SG_ 420 VSA_WARN_STATUS_BRAKE_1 1;
BA_ "DescriptionE" SG_ 420 VSA_VSA_TCS_ACT_1 "If the TSA?becomes active and the brake lamp turns ON, the bit must be turned 1.";
BA_ "ValueTableE" SG_ 420 VSA_VSA_TCS_ACT_1 "1: VSA, TCS active";
BA_ "ValueTableE" SG_ 420 VSA_ABS_EBD_ACT_1 "1: ABS, EBD active";
BA_ "ValueTableE" SG_ 420 VSA_VSA_TCS_MIL_1 "1: VSA, TCS failure";
BA_ "ValueTableE" SG_ 420 VSA_ABS_EBD_MIL_1 "1: ABS, EBD failure";
BA_ "ValueTableE" SG_ 420 VSA_CASEN_1 "1: Permit CAS operation";
BA_ "ValueTableE" SG_ 420 VSA_CAS_ACT_1 "1:  CAS active";
BA_ "ValueTableE" SG_ 420 VSA_BA_ACT_1 "1: BA active ";
BA_ "ValueTableE" SG_ 420 VSA_MASTER_CYLINDER_PRESSURE_1 "0066: 0kPa

0399: 19623.24kPa";
BA_ "GenSigStartValue" SG_ 420 VSA_MASTER_CYLINDER_PRESSURE_1 4095;
BA_ "ValueTableE" SG_ 420 VSA_ESS_ACT2_1 "0: The continuation of an operation of ESS by deceleration is forbidden.

1: The continuation of an operation of ESS by deceleration is permitted.";
BA_ "ValueTableE" SG_ 420 VSA_ESS_ACT1_1 "0: The operation start of ESS by deceleration is forbidden.

1: The operation start of ESS by deceleration is permitted.";
BA_ "DescriptionE" SG_ 145 VSA_ALIVE_COUNTER_091_1 "Incremented by 1 every time a packet is refreshed.

(0 to 3 ring counters)";
BA_ "DescriptionE" SG_ 145 VSA_SENSOR_START_UP_1 "During start-up process";
BA_ "GenSigStartValue" SG_ 145 VSA_SENSOR_START_UP_1 1;
BA_ "DescriptionE" SG_ 145 VSA_SENSOR_ERR_MC_1 "Abnormal CPU";
BA_ "DescriptionE" SG_ 145 VSA_SENSOR_STATE_IG_1 "Abnormal supply voltage";
BA_ "DescriptionE" SG_ 145 VSA_P_ERR_YAW1_1 "YAW 1 failure";
BA_ "DescriptionE" SG_ 145 VSA_T_ERR_YAW1_1 "Temporarily abnormal YAW1";
BA_ "GenSigStartValue" SG_ 145 VSA_LON_G_1 511.99999465;
BA_ "GenSigStartValue" SG_ 145 VSA_LAT_G_1 511.99999465;
BA_ "GenSigStartValue" SG_ 145 VSA_DEGC_1 103;
BA_ "DescriptionE" SG_ 145 VSA_YAW_1_1 "YAW1 data

* Refer to the attachment for the definition of the output.

* Refer to SPEC for the guarantee range.";
BA_ "GenSigStartValue" SG_ 145 VSA_YAW_1_1 512;
VAL_ 3221225472 VSA_ACC_INHBIT_ACC_BRK_PAD_TMP_1 1 "Temp above target  point." 0 "Temp below  target  point." ;
VAL_ 3221225472 VSA_INH_MODE6_1 1 "Mode prohibited for VSA" 0 "Mode available for VSA" ;
VAL_ 3221225472 VSA_INH_MODE5_1 1 "Mode prohibited for VSA" 0 "Mode available for VSA" ;
VAL_ 3221225472 VSA_INH_MODE4_1 1 "Mode prohibited for VSA" 0 "Mode available for VSA" ;
VAL_ 3221225472 VSA_INH_MODE_CHANGE_1 1 "Mode change prohibited for VSA" 0 "Mode change allowed for VSA" ;
VAL_ 3221225472 VSA_INH_MODE0_1 1 "Mode prohibited for VSA" 0 "Mode available for VSA" ;
VAL_ 3221225472 VSA_INH_MODE1_1 1 "Mode prohibited for VSA" 0 "Mode available for VSA" ;
VAL_ 3221225472 VSA_INH_MODE2_1 1 "Mode prohibited for VSA" 0 "Mode available for VSA" ;
VAL_ 3221225472 VSA_INH_MODE3_1 1 "Mode prohibited for VSA" 0 "Mode available for VSA" ;
VAL_ 3221225472 VSA_INH_MODE7_1 1 "Mode prohibited for VSA" 0 "Mode available for VSA" ;
VAL_ 3221225472 ENG_CAS_REQ_1 1 "CAS is requested" 0 "CAS is NOT requested" ;
VAL_ 2209174799 VSA_MAC_stRegMacKey_1 7 "Reserved" 6 "Reserved" 5 "Reserved" 4 "Failed" 3 "Pre-Failed" 2 "Pre-Passed" 1 "Passed" 0 "Initial" ;
VAL_ 2209174799 VSA_MAC_stGenMac_1 7 "Reserved" 6 "Reserved" 5 "Reserved" 4 "Failed" 3 "Pre-Failed" 2 "Pre-Passed" 1 "Passed" 0 "Initial" ;
VAL_ 2209174799 VSA_MAC_stCompMacCont_1 7 "Passed" 6 "Pre-Passed" 5 "Reserved" 4 "Initial" 3 "Reserved" 2 "Pre-Failed" 1 "Failed" 0 "Reserved" ;
VAL_ 2209174799 VSA_MAC_stCompMacAccum_1 3 "Failed" 2 "Pre-Failed" 1 "Not-Failed" 0 "Initial" ;
VAL_ 777 METER_SPEED_UNIT_1 1 "km/h" 0 "mph" ;
VAL_ 1619 VSA_DTC_SYSTEM_DESIGNATOR_BIT_1 1 "Honda DTC" 0 "SAE code" ;
VAL_ 1619 VSA_DTC_STORAGE_STATUS_1 1 "When confirmed DTC is stored" 0 "When confirmed DTC is not stored" ;
VAL_ 1619 VSA_FTB_STATUS_BIT_1 1 " FTB used" 0 "Do not use FTB" ;
VAL_ 546 METER_IDS_MODE_1 3 "Sport +

" 2 "Comfort

" 1 "Sport

" 0 "Normal

" ;
VAL_ 845 VSA_VSA_MODE_STATUS_1 7 "Diagnostic Mode Active

" 6 "Dyno Mode 2 Active

" 5 "Dyno Mode 1 Active

" 4 "OFF Prohibition Mode Active

" 3 "VSA OFF Active

" 2 "TCS OFF Active

" 1 "Maintenance Mode Active

" 0 "VSA Mode Not Active

" ;
VAL_ 489 RTC_T_FAIL_STATUS_1 1 "No reliability" 0 "Reliable" ;
VAL_ 489 RTC_P_FAIL_STATUS_1 1 "RTC system fault determination" 0 "RTC system normal" ;
VAL_ 489 RTC_STATUS_INVALID_1 1 "RTC fault status invalid" 0 "RTC fault status valid" ;
VAL_ 489 RTC_OFF_STATUS_1 1 "RTC OFF state" 0 "RTC ON state" ;
VAL_ 446 EBB_BRAKE_PEDAL_ON_STATUS 3 "Reserved" 2 "Failure" 1 "Normal" 0 "Initialization" ;
VAL_ 446 EBB_BRAKE_PEDAL_ON 1 "Driver is operating brake pedal." 0 "Except the above" ;
VAL_ 446 EBB_STATUS_1BE_1 7 "Normal" 6 "Post running" 5 "Torq limit in low volt/high temp" 4 "CAN signal failure" 3 "Reserved" 2 "Diagnosis mode" 1 "Failure" 0 "Initialization" ;
VAL_ 131 IMG_BRKMODE_HLD_STATUS_1 3 "Reserved" 2 "Reserved" 1 "Switch ISAB" 0 "Switch IMG Not Control" ;
VAL_ 424 BRK_HDC_ACT_1A8_1 1 "HDC Control is Active" 0 "HDC Control is NOT Active" ;
VAL_ 424 BRK_HDC_FAIL_1A8_1 1 "HDC Control Request is Refused" 0 "HDC Control Request is Permitted" ;
VAL_ 424 BRK_HDC_WAIT_1A8_1 1 "HDC Control Request is inhibited" 0 "HDC Control Request is Permitted" ;
VAL_ 262 VSA_HDC_REQ_ACT_1 1 "Description for the value '0x1'" 0 "HDC Control is NOT required" ;
VAL_ 1108 ENG_FAIL_PA_1 1 "PA sensor fails. 

" 0 "PA sensor does NOT fail. " ;
VAL_ 1571 VSA_ID_1 1 "Valid" 0 "Invalid" ;
VAL_ 1302 METER_UNDER10V_516_1 1 "Less than 10V" 0 "10V or more" ;
VAL_ 1568 BCM_ID_REQ_VSA_REC_1 1 "Tx fr immobilizer authnticatn" ;
VAL_ 1568 BCM_ID_REQ_VSA_1 1 "Tx fr immobilizer authnticatn" ;
VAL_ 231 EBB_EXTREQ_CTRL_STATUS_1 7 "Description for the value '0x7'" 6 "Reserved" 5 "Reserved" 4 "In control( functional limit)" 3 "In control" 2 "Operation possible" 1 "Operation impossible" 0 "Initialization" ;
VAL_ 231 EBB_WARN_STATUS_BRAKESYSTEM_1 1 "BRAKE SYSTEM warning lamp is ON" 0 "BRAKE SYSTEM warning lamp is OFF" ;
VAL_ 231 EBB_OUTPUTROD_STATUS_1 3 "Reserved" 2 "Failure" 1 "Normal" 0 "Initialization" ;
VAL_ 231 EBB_EXTREQ_CTRL_1 1 "In external brake control" 0 "Not in external brake control" ;
VAL_ 929 METER_DWS_INIT_REQ_SW_1 1 "DWS initialization req" 0 "No DWS initialization req" ;
VAL_ 929 METER_DWS_INIT_REQ_1 1 "Req for DWS initializtn" 0 "No Req for DWS initializtn" ;
VAL_ 806 METER_R_SCROLL_PUSH_1 1 "Steering switch ON" 0 "Steering switch OFF" ;
VAL_ 806 METER_SW_STATUS_VSA_1 1 "VSA ON request" 0 "VSA OFF request" ;
VAL_ 806 METER_SW_STATUS_PARK_BRAKE_1 1 "Parking Brake ON" 0 "Parking Brake OFF" ;
VAL_ 806 METER_SW_STATUS_BRAKE_FLUID_1 1 "Brake fluid level ON" 0 "Brake fluid level OFF" ;
VAL_ 806 METER_SW_STATUS_VSA_OFF_1 1 "VSA OFF switch ON" 0 "VSA OFF switch OFF" ;
VAL_ 806 METER_RL_STATUS_1 1 "Backlight switch ON" 0 "Backlight switch OFF" ;
VAL_ 806 METER_SW_STATUS_BHOLD_1 3 "Description for the value '0x3'" 2 "Brake hold switch disconnection" 1 "Brake hold switch ON" 0 "Brake hold switch OFF" ;
VAL_ 469 EBB_STATUS_1 7 "Normal" 6 "Post running" 5 "Torq limit in low volt/high temp" 4 "CAN signal failure" 3 "Reserved" 2 "Diagnosis mode" 1 "Failure" 0 "Initialization" ;
VAL_ 469 EBB_BRAKE_PEDAL_ON_1 1 "Driver is operating brake pedal." 0 "Except the above" ;
VAL_ 469 EBB_BRAKE_PEDAL_ON_STATUS_1 3 "Reserved" 2 "Failure" 1 "Normal" 0 "Initialization" ;
VAL_ 469 EBB_RUNOUT_STATUS_1 3 "Reserved" 2 "Failure" 1 "Normal" 0 "Initialization" ;
VAL_ 232 VSA_EXTERNAL_PRESSURE_ACTIVE_1 3 "Reserved" 2 "AEB in progress" 1 "Automatic brake in progress" 0 "External brake not under control" ;
VAL_ 232 VSA_VEHICLE_SPEED_STATUS_1 3 "Reserved" 2 "Failure" 1 "Normal" 0 "Initialization" ;
VAL_ 199 VSA_MAX_PRESSURE_STATUS_0C7_1 3 "Reserved" 2 "Failure" 1 "Normal" 0 "initialization" ;
VAL_ 199 VSA_IG_ON_0C7_1 1 "on" 0 "off" ;
VAL_ 199 VSA_DIAG_STATUS_0C7_1 1 "Into diagnosis mode" 0 "Except the above" ;
VAL_ 199 VSA_ABS_CTRL_0C7_1 1 "In ABS control" 0 "Not in ABS control" ;
VAL_ 199 VSA_FAIL_MC_PRESSRE_SENSOR_0C7_1 1 "Sensor is faulty" 0 "Sensor is normal" ;
VAL_ 479 IDAS_CRUISE_ACTIVE 1 "active" 0 "Not active

" ;
VAL_ 479 IDASB_INFO_IND_WARNING_1 3 "Reserved" 2 "Reserved" 1 "BRAKE’ is lit

" 0 "No display

" ;
VAL_ 479 IDAS_REQ_EPB_ACT_1 1 "EPB actuation requested

" 0 "Not requested

" ;
VAL_ 479 IDAS_STATUS_FAIL_AEB_1 1 "CMBS status faulty

" 0 "CMBS control normal

" ;
VAL_ 479 IDAS_STATUS_FAIL_ACC_1 1 "ACC/LSF/RDM faulty

" 0 "ACC/LSF/RDM control normal" ;
VAL_ 479 IDAS_REQ_BRAKE_RELEASE_1 1 "Brake release requested

" 0 "Not requested

" ;
VAL_ 479 IDAS_REQ_STOP_BRAKE_1 1 "Stop requested

" 0 "Not requested

" ;
VAL_ 479 IDAS_REQ_ACC_BRAKE_CTRL_1 1 "ACC control requested

" 0 "Not requested

" ;
VAL_ 479 IDAS_REQ_AEB_BRAKE_CTRL_1 1 "CMBS control requested

" 0 "Not requested

" ;
VAL_ 479 IDAS_REQ_PREFILL_1 1 "Prefill control requested

" 0 "Not requested

" ;
VAL_ 423 EAT_FAILURE_FOR_EPB_1 1 "fault affecting EPB" 0 "No failure" ;
VAL_ 423 EAT_ATRVS_SW_STATUS_1 1 "RVS switch ON" 0 "RVS switch OFF" ;
VAL_ 423 EAT_ATFWD_SW_STATUS_1 1 "FWD switch ON" 0 "FWD switch OFF" ;
VAL_ 57 SRS_CDS_REAR_1 1 "Collision ON" 0 "Collision OFF" ;
VAL_ 57 SRS_CDS_SIDE_1 1 "Collision ON" 0 "Collision OFF" ;
VAL_ 57 SRS_CDS_FRONT_1 1 "Collision ON" 0 "Collision OFF" ;
VAL_ 773 SRS_DR_BELT_STATUS_1 3 "Drivr seat belt switch fail

" 2 "Driver seat belt buckled  

" 1 "Driver seat belt not buckled" 0 "Drivr belt cant determined  " ;
VAL_ 773 SRS_DR_BELT_1 1 "Driver-side seat belt warning

" 0 "No driver seat belt warning  

" ;
VAL_ 320 ENG_REQUEST_EPB_ACT 1 "EPB operation request ON" 0 "EPB operation request OFF" ;
VAL_ 320 ENG_DEC_NSS_BHOLD_1 1 "shift position is neutral" 0 "shift position is not neutral" ;
VAL_ 1928 VSA_CAL_YAWG_CANCEL_1 1 "Calibration cancel requested" 0 "Calibration cancel not requested" ;
VAL_ 1928 VSA_CAL_YAW_START_1 1 "Calibration is requested" 0 "Calibration not requested" ;
VAL_ 1928 VSA_CAL_YAW_CLEAR_1 1 "Calibration is requested" 0 "Calibration not requested" ;
VAL_ 1928 VSA_CAL_LONG_START_1 1 "Calibration is requested" 0 "Calibration not requested" ;
VAL_ 1928 VSA_CAL_LONG_CLEAR_1 1 "Calibration is requested" 0 "Calibration not requested" ;
VAL_ 1928 VSA_CAL_LATG_START_1 1 "Calibration is requested" 0 "Calibration not requested" ;
VAL_ 1928 VSA_CAL_LATG_CLEAR_1 1 "Calibration is requested" 0 "Calibration not requested" ;
VAL_ 148 SRS_POST_COLLISION_BRK_FAILURE_1 1 "Collision detection func fail" 0 "Collision detection func normal" ;
VAL_ 148 SRS_POST_COLLISION_BRK_1 3 "COLLISION_HI" 2 "COLLISION_MID" 1 "COLLISION_LO" 0 "OFF" ;
VAL_ 148 SRS_SENSOR_STATE_IG_1 1 "volt cant protect func of sensor" 0 "Normal time" ;
VAL_ 148 SRS_SENSOR_START_UP_1 1 "During start check" 0 "start check normal" ;
VAL_ 148 SRS_SENSOR_ERR_MC_1 1 "Fault confirmed by diag" 0 "Normal time" ;
VAL_ 148 SRS_T_ERR_YAW1_1 1 "YAW1 cannot be guaranteed" 0 "Normal Time" ;
VAL_ 148 SRS_T_ERR_LON_G_1 1 "Acceleratn cant be guaranteed" 0 "Normal time" ;
VAL_ 148 SRS_T_ERR_LAT_G_1 1 "Acceleratn cant be guaranteed" 0 "Normal time" ;
VAL_ 148 SRS_T_ERR_DEGC_1 1 "Temp data cant be guaranteed" 0 "Normal time" ;
VAL_ 148 SRS_P_ERR_YAW1_1 1 "failure of yaw rate is fixed" 0 "Normal time" ;
VAL_ 148 SRS_P_ERR_LON_G_1 1 "front/rear G accelratn confirmed" 0 "Normal time" ;
VAL_ 148 SRS_P_ERR_LAT_G_1 1 "lateral G acceleration is fixed" 0 "Normal time" ;
VAL_ 148 SRS_P_ERR_DEGC_1 1 "temp data is fixed" 0 "Normal time" ;
VAL_ 148 SRS_CAL_YAW_1 1 "sensor calib complete." 0 "sensor calib not complete." ;
VAL_ 148 SRS_CAL_LON_G_1 1 "sensor calib complete." 0 "sensor calib not complete." ;
VAL_ 148 SRS_CAL_LAT_G_1 1 "sensor calib complete." 0 "sensor calib not complete." ;
VAL_ 486 RTC_T_FAIL_STATUS_1 1 "No reliability" 0 "Reliable" ;
VAL_ 486 RTC_P_FAIL_STATUS_1 1 "RTC system fault determination" 0 "RTC system normal" ;
VAL_ 486 RTC_STATUS_INVALID_1 1 "RTC fault status invalid" 0 "RTC fault status valid" ;
VAL_ 330 EPS_STR_START_UP_1 1 "During initialization" 0 "Initialization is completed" ;
VAL_ 795 VSA_MID_WARN_STATUS_DWS_INIT_1 1 "DWS/iDWS MID is enabled" 0 "DWS/iDWS MID is disabled" ;
VAL_ 795 VSA_REJECT_OFF_SW_OPTN_MID_1 1 "Reject OFF SW Operation MID is enabled" 0 "Reject OFF SW Operation MID is disabled" ;
VAL_ 795 VSA_DWS_AUTOJUDGE_1 1 "DWS/iDWS function is applied" 0 "DWS/iDWS function is not applied" ;
VAL_ 795 VSA_MID_REQ_HDC_SW_STATUS_1 3 "HDC control state is active" 2 "HDC control state is standby" 1 "HDC control state is OFF" 0 "Non-Display" ;
VAL_ 795 VSA_HDC_CONTROL_STATUS_1 2 "HDC Control state is active" 1 "HDC Control state is standby" 0 "HDC Control state is OFF" ;
VAL_ 795 VSA_HDC_SPEED_UNIT_1 1 "km/h" 0 "mph" ;
VAL_ 795 VSA_MID_HDC_OP_GUIDE_1 5 "Reserve" 4 "HDC is stand by " 3 "HDC OFF due to vehicle speed" 2 "HDC can't due to vehicle speed" 1 "HDC can't due to ACC/LFC active" 0 "No display" ;
VAL_ 795 VSA_MID_REQUEST_IDS_1 5 "Reserved" 4 "TRAIL MID enabled

" 3 "TRACK MID enabled

" 2 "MUD MID enabled

" 1 "SAND MID enabled

" 0 "IDS MID disabled

" ;
VAL_ 795 VSA_MID_REQUEST_VSA_OFF_1 1 "MID Warning Enabled" 0 "MID Warning Disabled" ;
VAL_ 795 VSA_MID_REQUEST_TCS_OFF_1 1 "MID Warning Enabled" 0 "MID Warning Disabled" ;
VAL_ 795 VSA_MID_REQ_EPB_MISOP_GUIDE_1 3 "Reserved" 2 "Brake pedal is NOT pressed" 1 "Seatbelt is NOT fastened" 0 "No display " ;
VAL_ 795 VSA_MID_LMP_STATS_OPRTE_BHOLD_1 1 "MID Warning Enabled" 0 "MID Warning Disabled" ;
VAL_ 795 VSA_MID_LAMP_STATUS_HDC_OFF_1 1 "MID Warning Enabled" 0 "MID Warning Disabled" ;
VAL_ 795 VSA_WARN_STATUS_HDC_1 1 "MID Warning Enabled" 0 "MID Warning Disabled" ;
VAL_ 795 VSA_MID_WARN_STATUS_TSA_1 1 "MID Warning Enabled" 0 "MID Warning Disabled" ;
VAL_ 795 VSA_MID_WARN_STATUS_BRAKESYSTM_1 1 "MID Warning Enabled" 0 "MID Warning Disabled" ;
VAL_ 795 VSA_WARN_STATUS_HSA_31B_1 1 "MID Warning Enabled" 0 "MID Warning Disabled" ;
VAL_ 795 VSA_MID_WARN_STATUS_BRAKE_1 1 "MID Warning Enabled" 0 "MID Warning Disabled" ;
VAL_ 795 VSA_MID_WARN_STATUS_ABS_1 1 "MID Warning Enabled" 0 "MID Warning Disabled" ;
VAL_ 795 VSA_MID_REQUEST_VSA_31B_1 1 "MID Warning Enabled" 0 "MID Warning Disabled" ;
VAL_ 795 VSA_MID_LAMP_STATUS_VSA_OFF_1 1 "MID Warning Enabled" 0 "MID Warning Disabled" ;
VAL_ 795 VSA_MID_REQ_BHOLD_STANDBY_1 1 "Brake hold in standby mode

" 0 "Brake hold NOT in standby mode" ;
VAL_ 795 VSA_MID_REQ_BHOLD_EPB_OP_INFO_1 1 "BHOLD transtn to EPB MID

" 0 "Do not display. " ;
VAL_ 795 VSA_MID_REQ_BHOLD_MISOP_GUIDE_1 3 "Description for the value '3'" 2 "Bhold exit condtn unsatisfied " 1 "Bhold enter condtn unsatisfied " 0 "No Display" ;
VAL_ 795 VSA_MID_REQ_BHOLD_APPLY_BRAKE_1 1 "Brake pedal apply request is ON" 0 "No Display" ;
VAL_ 795 VSA_WARN_STATUS_BHOLD_1 1 "MID Warning Enabled" 0 "MID Warning Disabled" ;
VAL_ 795 VSA_MID_WARN_STATUS_DWS_1 1 "MID Warning Enabled" 0 "MID Warning Disabled" ;
VAL_ 795 VSA_MID_WARN_STATUS_PUNCTURE_1 1 "MID Warning Enabled" 0 "MID Warning Disabled" ;
VAL_ 387 ESB_REQ_BRAKERELAY_ACT_1 1 "Relay operation required" 0 "No Relay operation required" ;
VAL_ 387 AHB_WARN_STATUS_SYSTEM_1 1 "Brk sys warn light frm ESB req" 0 "No Brk warn light frm ESB req" ;
VAL_ 387 AHB_HBC_REQ_1 1 "HBC ctrl for VSA is requested" 0 "No HBC ctrl for VSA is requested" ;
VAL_ 387 AHB_VSACHG_FAIL_1 1 "VSA cooperative ctrl impossible" 0 "VSA cooperative ctrl possible" ;
VAL_ 387 AHB_BPS_FAIL_1 1 "Stroke sensor error" 0 "Stroke sensor Normal" ;
VAL_ 387 AHB_VSA_INCREASE_PRESS_ACT_1 1 "ESB on automatic press ctrl" 0 "ESB not on automatic press ctrl" ;
VAL_ 419 TM_BRAKE_HOLD_REQ_VSA_1 1 "Parking Assist brk required " 0 "Parking Assist brk NOT required " ;
VAL_ 419 TM_SW_STATUS_SMODE_1 1 "SMODE

" 0 "NORMAL MODE" ;
VAL_ 419 TM_FAILURE_FOR_VSA_1 1 "TM failure." 0 "TM normal" ;
VAL_ 419 TM_GEAR_POSITION_TARGET_1 15 "Invalid" 14 "Unknown" 13 "Unknown" 12 "Unknown" 11 "Unknown" 10 "Reverse" 9 "9th" 8 "8th" 7 "7th" 6 "6th" 5 "5th" 4 "4th" 3 "3rd" 2 "2nd" 1 "1st" 0 "Neutral" ;
VAL_ 419 TM_GEAR_POSITION_IND_1 15 "Unknown" 14 "Unknown" 13 "Unknown" 12 "Unknown" 11 "Unknown" 10 "Unknown" 9 "9th" 8 "8th" 7 "7th" 6 "6th" 5 "5th" 4 "4th" 3 "3rd" 2 "2nd" 1 "1st" 0 "Neutral" ;
VAL_ 419 TM_GEAR_POSITION_ACTUAL_1 15 "Invalid" 14 "Unknown" 13 "Unknown" 12 "Unknown" 11 "Shifting" 10 "Reverse" 9 "9th" 8 "8th" 7 "7th" 6 "6th" 5 "5th" 4 "4th" 3 "3rd" 2 "2nd" 1 "1st" 0 "Neutral

" ;
VAL_ 538 VSA_REQ_BRAKERELAY_ACT 1 "Brake Lamp Relay Request active" 0 "Brke Lamp Relay Request inactive" ;
VAL_ 538 VSA_ESB_LON_G_FAIL_1 1 "Longitudinal G sensor is failed" 0 "Longitudinal G sensor NOT failed" ;
VAL_ 538 VSA_ESB_LON_G_INH2_1 1 "Long G sensor cant be guaranteed" 0 "Long G sensor can be guaranteed" ;
VAL_ 538 VSA_ESB_LON_G_INH1_1 1 "Long G sensor cant be guaranteed" 0 "Long G sensor can be guaranteed" ;
VAL_ 538 VSA_INHIBIT_BRKRLY_DIAG_ESB_1 1 "Brke Lmp Relay Failsafe inactive" 0 "Brake Lmp Relay Failsafe active" ;
VAL_ 470 ENG_ISAB_REQUEST_1D6_1 1 " ISAB activation required

" 0 "ISAB activation NOT required

" ;
VAL_ 422 METER_SW_STATUS_HIL_CONTRL_1A6_1 3 "Switch ground fault" 2 "Switch disconnection" 1 "Switch ON" 0 "Switch OFF" ;
VAL_ 422 METER_SW_STATUS_BHOLD_1A6_1 3 "Description for the value '0x3'" 2 "Brake hold switch disconnection" 1 "Brake hold switch ON" 0 "Brake hold switch OFF" ;
VAL_ 422 METER_RL_STATUS_1A6_1 1 "Backlight switch ON" 0 "Backlight switch OFF" ;
VAL_ 422 METER_SW_STATUS_VSA_OFF_1A6_1 1 "VSA OFF switch ON" 0 "VSA OFF switch OFF" ;
VAL_ 422 METER_SW_STATUS_PARK_BRAKE_1A6_1 1 "Parking Brake ON" 0 "Parking Brake OFF" ;
VAL_ 422 METER_SW_STATUS_BRKE_FLUID_1A6_1 1 "Brake fluid level ON" 0 "Brake fluid level OFF" ;
VAL_ 1424 VSA_FTB_STATUS_BIT_1 1 " FTB used" 0 "Do not use FTB" ;
VAL_ 1424 VSA_DTC_SYSTEM_DESIGNATOR_BIT_1 1 "Honda DTC" 0 "SAE code" ;
VAL_ 1424 VSA_DTC_STORAGE_STATUS_1 1 "When confirmed DTC is stored" 0 "When confirmed DTC is not stored" ;
VAL_ 661 METER_SW_STATUS_HIL_CONTRL_295_1 3 "Switch ground fault" 2 "Switch disconnection" 1 "Switch ON" 0 "Switch OFF" ;
VAL_ 661 METER_DWS_INIT_REQ_SW_1 1 "DWS init req with init switch" 0 "No DWS init req with init switch" ;
VAL_ 661 METER_DWS_INIT_REQ_1 1 "Req for DWS initializtn" 0 "No Req for DWS initializtn" ;
VAL_ 488 VSA_HDC_REQ_ACT_1E8_1 1 "Description for the value '0x1'" 0 "HDC Control is NOT required" ;
VAL_ 488 VSA_EPB_MAC_1E8_1 1 "Mode prohibited for VSA" 0 "Mode available for VSA" ;
VAL_ 488 VSA_EPB_MESSAGE_COUNTER_1E8_1 1 "Mode prohibited for VSA" 0 "Mode available for VSA" ;
VAL_ 488 VSA_EPB_RESET_FLAG_1E8_1 1 "Mode prohibited for VSA" 0 "Mode available for VSA" ;
VAL_ 426 VSA_IG_ON_1 1 "VSA IG ON" 0 "VSA IG OFF

" ;
VAL_ 426 VSA_IDS_INHIBIT_DISABLED_STATE_1 1 "VSA function is disabled

" 0 "VSA function is enabled

" ;
VAL_ 426 VSA_IDS_INHIBIT_ACT_1 1 "functions under activation" 0 "other" ;
VAL_ 426 VSA_EBB_FAILURE_FOR_IS_1 1 "EBB CPU failure 

" 0 "Normal" ;
VAL_ 426 VSA_HAC_CUT_REQ_1 1 "AC cut Request 

" 0 "No request

" ;
VAL_ 426 VSA_HBB_IS_REFUSE_REQ_1 1 "Idle Stp Prohibitn Req" 0 "No request" ;
VAL_ 426 VSA_LOW_VAC_IS_SHFT_INHBIT_REQ_1 1 "Idle Stp Prohibitn Req" 0 "No request" ;
VAL_ 426 VSA_HBB_IS_SHIFT_INHIBIT_REQ_1 1 "Idle Stp Prohibitn Req" 0 "No request" ;
VAL_ 426 VSA_MNTMODE_STATUS_1 1 "VSA maintenance mode

" 0 "NOT in  VSA maintenance mode

" ;
VAL_ 426 VSA_REVERSE_SWITCH_FAIL_1 1 "Back light switch fails" 0 "Back light switch does NOT fail" ;
VAL_ 426 VSA_SHFT_IN_REVERSE_1 1 "Back light switch is ON. " 0 "Back light switch is OFF" ;
VAL_ 426 VSA_ECD_ACT_1 1 "EPB fluid pres ctrl ongoing 

" 0 "ctrl not ongoing 

" ;
VAL_ 426 VSA_FAIL_FOR_EPB_1 1 "Abnormal" 0 "Normal" ;
VAL_ 426 VSA_REQUEST_EPB_ACT_1 1 "EPB activation request ON " 0 "EPB activation request OFF " ;
VAL_ 426 VSA_EPB_INHIBIT_BRAKE_1 1 "Temporarily prohibited" 0 "Permitted" ;
VAL_ 426 VSA_EPB_REFUSE_BRAKE_1 1 "Prohibited" 0 "Permitted" ;
VAL_ 426 VSA_TM_SUPPORT_BRKE_REFUSE_1AA_1 1 "TM supprt brk req not accepted

" 0 "TM support brk req is accepted

" ;
VAL_ 426 VSA_IS_RESTART_INHIBIT_REQ_1AA_1 1 "Idle Stp Prohibitn Req" 0 "No request" ;
VAL_ 426 VSA_ISAB_ACT_1AA_1 1 "In ISAB control

" 0 "NOT in ISAB control" ;
VAL_ 426 VSA_BTCS_ACT_1AA_1 1 "Brake-TCS is active

" 0 "Brake-TCS is NOT active

" ;
VAL_ 426 VSA_ISAB_ENABLE_1AA_1 1 "permitted" 0 "prohibited" ;
VAL_ 426 VSA_IS_SHFT_INHBIT_REQUEST_1AA_1 1 "Idle Stp Prohibitn Req" 0 "No request" ;
VAL_ 426 VSA_SHIFT_REQ_1AA_1 3 "Description for the value '0x3'" 2 "Shift up request 

" 1 "Shift hold request

" 0 "No shift ctrl request from VSA " ;
VAL_ 426 VSA_TRQ_DOWN_REQ_FUEL_CUT_1AA_1 3 "Reserved" 2 "All-cylinders F/C + ig retard 

" 1 "Ignition retard 

" 0 "No fuel/ignition control " ;
VAL_ 426 VSA_REQ_MSR_PLUS_TRQ_1AA_1 1 "Plus torque is requested

" 0 "No request" ;
VAL_ 426 VSA_TRQ_CONTROL_MODE_1AA_1 3 "VSA/TCS prohibited " 2 "Acceleration control ongoing 

" 1 "MSR control ongoing " 0 "No VSA/TCS control 

" ;
VAL_ 506 ACC_REQ_BRAKERELAY_ACT_1 1 "Relay operation required" 0 "No relay operation request" ;
VAL_ 506 ACC_LSF_BHOLD_ACT_1 1 "Stop hold control in progress" 0 "Stop hold ctrl not in progress" ;
VAL_ 506 ACC_REWRITE_START_1 1 "ACC_ECU rewrite start" 0 "ACC_ECU not being rewritten" ;
VAL_ 506 ACC_STATUS_FAIL_ACC_1 1 "ACC fail" 0 "ACC operation normal" ;
VAL_ 506 ACC_STATUS_FAIL_CVRS_BRAKE_1 1 "Collision reduction brking fail" 0 "Colision reduction brking normal" ;
VAL_ 506 ACC_TARGET_MOT_LEVEL_1 7 "Reserved" 6 "Req frm rear-end reduction brk" 5 "Reserved" 4 "Reserved" 3 "Reserved" 2 "Request from ACC(B)" 1 "Request from ACC(A)" 0 "No request from ACC" ;
VAL_ 506 ACC_EPB_ACT_REQ_1 1 "Request foe EPB operation" 0 "No request" ;
VAL_ 506 ACC_STATUS_REQ_ACC_BRAKE_1 1 "ACC control requested" 0 "No ACC control request" ;
VAL_ 506 ACC_STATUS_REQ_CVRS_BRAKE_1 1 "Colision reductn brk ctrl req" 0 "No rearend colision brk ctrl req" ;
VAL_ 316 ENG_IG1_10V_STATUS_1 1 "ENG IG1>=10V" 0 "ENG IG1 < 10V" ;
VAL_ 316 ENG_CLUTCH_SW_SIL_1 1 "Clutch pedal is NOT depressed" 0 "Clutch pedal is depressed" ;
VAL_ 316 ENG_BRK_ACCELE_PEDAL_ON_13C_1 1 "accele pedal stepped on." 0 "accele pedal not stepped on." ;
VAL_ 316 ENG_CAS_REQ_13C_1 1 "CAS is requested" 0 "CAS is NOT requested" ;
VAL_ 316 ENG_NEUTRAL_SENSOR_FAIL_13C_1 1 "NEUTRAL SENSOR failure" 0 "NEUTRAL SENSOR normal" ;
VAL_ 316 ENG_SHFT_IN_NEUTRAL_13C_1 1 "Shift lever at the neutral pos." 0 "Shift lever not at neutral pos." ;
VAL_ 316 ENG_SHFT_IN_REVERSE_13C_1 1 "Shift lever at reverse position." 0 "Shift lever not at reverse pos." ;
VAL_ 316 ENG_CLUTCH_SW_CC_13C_1 1 "Clutch pedal is applied." 0 "Clutch pedal is NOT applied." ;
VAL_ 316 ENG_VSA_ACK1_13C_1 15 "Reserved" 14 "Reserved" 13 "Reserved" 12 "Reserved" 11 "Reserved" 10 "Reserved" 9 "Reserved" 8 "Reserved" 7 "Reserved" 6 "Reserved" 5 "Reserved" 4 "Reserved" 3 "Reserved" 2 "All-cylinder F/C" 1 "Ignition retard" 0 "No fuel/ignition control" ;
VAL_ 316 ENG_VSA_PERMIT_PLUS_TRQ_13C_1 1 "MSR+ torq req frm VSA permitted" 0 "MSR+ torq req frm VSA rejected" ;
VAL_ 316 ENG_RECEIVE_ERROR_1AA_1 1 "receiving error" 0 "No receiving error" ;
VAL_ 316 ENG_VSA_INHIBIT_VSA_CONTRL_13C_1 1 "ENG fail-refuse vsa ctrl" 0 "VSA control permitted" ;
VAL_ 316 ENG_VSA_REFUSED_VSA_CONTRL_13C_1 1 "ENG fail-refuse vsa ctrl" 0 "VSA control permitted" ;
VAL_ 985 VSA_ABS_DISABLE_EDR_1 1 "ABS control is prohibited" 0 "Disable ABS control" ;
VAL_ 985 VSA_STABILITY_CTRL1_DSABLE_EDR_1 1 "Atleast 1 ctrl prohibited" 0 "All stability ctrl prohibited " ;
VAL_ 985 VSA_STABILITY_CTRL2_DSABLE_EDR_1 1 "Atleast 1 ctrl prohibited" 0 "All stability ctrl prohibited " ;
VAL_ 985 VSA_VSA_EQUIPPED_EDR_1 1 "Description for the value '1'" 0 "VSA unit is not equipped " ;
VAL_ 985 VSA_ABS_ACT_EDR_1 1 "ABS control is activated" 0 "ABS control not in operation" ;
VAL_ 985 VSA_STABILITY_CTRL_ACT_EDR_1 1 "Atleast one control operating" 0 "All stabilty ctrls not operation" ;
VAL_ 985 VSA_VSA_OFF_STATUS_EDR_1 1 "ESC function is turned off" 0 "ESC function is not turned off" ;
VAL_ 808 ENG_STRNNEND_1 1 "Eng cranking completed" 0 "Except above" ;
VAL_ 804 ENG_SW_STATUS_SCS_1 1 "Description for the value '0x1'" 0 "Normal time" ;
VAL_ 388 ESB_IG_ON_1 1 "ON" 0 "OFF" ;
VAL_ 388 ESB_BHOLD_STATUS_ACT_1 1 "Vehicle hold by ESB is operating" 0 "Vehicle hld by ESB not operating" ;
VAL_ 388 ESB_REQUEST_EPB_ACT_1 1 "EPB activation request ON" 0 "EPB activation request OFF" ;
VAL_ 388 ESB_HBC_REQ_184_1 1 "HBC Control is required" 0 "HBC Control is NOT required" ;
VAL_ 388 ESB_ACT_BRAKERELAY_1 1 "ESB unit driving brk lamp relay" 0 "Except above" ;
VAL_ 388 ESB_INHIBIT_BRAKERELAY_1 1 "Brk lamp relay temp disabled" 0 "Except below" ;
VAL_ 388 ESB_FAIL_BRAKERELAY_1 1 "Brk lamp relay failure confirmed" 0 "Except below" ;
VAL_ 388 ESB_VSA_INCREASE_PRESSURE_ACT2_1 1 "ESB Auto Pressurization Active" 0 "ESB Auto Pressurization Inactive" ;
VAL_ 388 ESB_VSA_CONTROL_LIMIT_1 1 "VSA Control Limit exist" 0 "VSA Control Limit does NOT exist" ;
VAL_ 388 ESB_EPB_INHBIT_BRAKE_1 1 "EPB Press Ctrl Req inh temporily" 0 "EPB Pressure Ctrl Req Permitted" ;
VAL_ 388 ESB_EPB_REFUSE_BRAKE_1 1 "EPB Pressure Ctrl Req Refused" 0 "EPB Pressure Ctrl Req permit" ;
VAL_ 388 ESB_ECD_ACT_1 1 "EPB Pressure Ctrl Active" 0 "EPB Pressure Ctrl not Active" ;
VAL_ 450 VSA_EPB_DAR_DISABLE_1 1 "DAR function disabled" 0 "Expect below" ;
VAL_ 450 EPB_FAIL_1 1 "EPB operation Normal" 0 "EPB Fail" ;
VAL_ 450 VSA_EPB_WARN_LAMP_1 1 "Warn Lamp ON" 0 "Warn Lamp OFF" ;
VAL_ 450 VSA_EPB_PARK_BUSY_1 1 "EPB Operation complete" 0 "EPB operation not complete" ;
VAL_ 450 VSA_EPB_REQ_INFO_WARNING_1 1 "Display ON" 0 "Display OFF" ;
VAL_ 450 VSA_EPB_REQ_INFO_MANREL_1 1 "Display ON" 0 "Display OFF" ;
VAL_ 450 VSA_EPB_REQ_INFO_AUTOREL_1 1 "Display ON" 0 "Display OFF" ;
VAL_ 450 VSA_EPB_INHIBIT_ACT_1 1 "EPB operation temp inhibition" 0 "EPB operation enabled

" ;
VAL_ 450 VSA_EPB_REFUSE_ACT_1 1 "EPB_Operation Enabled" 0 "EPB_Operation Disabled" ;
VAL_ 450 VSA_EPB_STAY_AWAKE_REQ_VSA_1 1 "Stay Awake ON" 0 "Stay Awake OFF" ;
VAL_ 450 VSA_EPB_REQ_BRAKE_CTRL_1 1 "Fluid_Pressure_ctrl_request_ON" 0 "Fluid_Pressure_ctrl_request_OFF" ;
VAL_ 274 VSA_EPB_CLUTCH_PEDAL_FAIL_1 1 "Pedal stroke sensor failure" 0 "Pedal stroke sensor normal" ;
VAL_ 356 METER_SW_STATUS_BHOLD_SENKOSYA_1 1 "Brake hold ON" 0 "Brake hold switch OFF" ;
VAL_ 356 METER_SW_STATUS_PARK_BRAKE_1 1 "Parking Brake ON" 0 "Parking Brake OFF" ;
VAL_ 356 METER_SW_STATUS_BRAKE_FLUID_1 1 "Brake fluid level ON" 0 "Brake fluid level OFF" ;
VAL_ 356 METER_SW_STATUS_VSA_OFF_1 1 "VSA OFF switch ON" 0 "VSA OFF switch OFF" ;
VAL_ 392 EAT_SW_STATUS_SMODE 1 "SMODE" 0 "Normal Mode" ;
VAL_ 392 EAT_FAILURE_FOR_VSA_1 1 "refuse vsa ctrl at outbrk" 0 "vsa ctrl normal time" ;
VAL_ 392 EAT_GEAR_POSITION_TARGET_1 7 "6th" 6 "Reverse" 5 "5th" 4 "4th" 3 "3rd" 2 "2nd" 1 "1st" 0 "Neutral" ;
VAL_ 392 EAT_GEAR_POSITION_ACTUAL_1 15 "Reserved" 14 "Reserved" 13 "Reserved" 12 "Reserved" 11 "Reserved" 10 "Reserved" 9 "Reserved" 8 "6th" 7 "During Speed change" 6 "Reserve" 5 "5th" 4 "4th" 3 "3rd" 2 "2nd" 1 "1st" 0 "Neutral" ;
VAL_ 401 CVT_SW_STATUS_SMODE_1 1 "SMODE" 0 "Normal Mode" ;
VAL_ 401 CVT_REFUSE_VSA_CONTROL_1 1 "refuse vsa ctrl at outbrk" 0 "vsa ctrl normal time" ;
VAL_ 401 CVT_GEAR_POSITION_IND_CVT_1 10 "Reserved" 9 "Reserved" 8 "Reserved" 7 "7th" 6 "6th" 5 "5th" 4 "4th" 3 "3rd" 2 "2nd" 1 "1st" 0 "OFF" ;
VAL_ 380 ENG_ACCELE_FAIL_INFORMATION_1 1 "Acceleration pedal failure" 0 "Acceleration pedal normal" ;
VAL_ 380 ENG_CRUISE_STATUS_CRUISE_INH_1 1 "Cruise control prohibited" 0 "Cruise control permitted" ;
VAL_ 380 ENG_IS_PRE_RESTART_1 1 "Advnce notifictin of re-crankin" 0 "Except above" ;
VAL_ 380 ENG_IS_PROGRESS_1 1 "Idle Stp Ctrl started & ongoing" 0 "Except above" ;
VAL_ 380 ENG_SW_STATUS_BRAKE_NO_1 1 "Brake switch ON" 0 "Brake switch OFF" ;
VAL_ 380 ENG_CRUISE_STATUS_CRUISE_LMP_1 1 "Cruise control lamp ON" 0 "Cruise control lamp OFF" ;
VAL_ 304 ENG_PP_DISABLE_1 1 "Vehicle is  not running" 0 "Vehicle is running" ;
VAL_ 304 ENG_CLUTCH_SW_SIL_1 1 "Clutch pedal is NOT depressed" 0 "Clutch pedal is depressed" ;
VAL_ 304 ENG_EV_DRIVE_STATE_1 1 "EV drive" 0 "ENG drive" ;
VAL_ 304 ENG_BRK_ACCELE_PEDAL_ON_1 1 "accele pedal stepped on." 0 "accele pedal not stepped on." ;
VAL_ 304 ENG_SHFT_IN_REVERSE_1 1 "Shift lever at reverse position." 0 "Shift lever not at reverse pos." ;
VAL_ 304 ENG_NEUTRAL_SENSOR_FAIL_1 1 "NEUTRAL SENSOR failure" 0 "NEUTRAL SENSOR normal" ;
VAL_ 304 ENG_RECEIVE_ERROR_1AC_1 1 "receiving error" 0 "No receiving error" ;
VAL_ 304 ENG_SHFT_IN_NEUTRAL_1 1 "Shift lever at the neutral pos." 0 "Shift lever not at neutral pos." ;
VAL_ 304 ENG_CLUTCH_SW_CC_1 1 "Clutch pedal is applied." 0 "Clutch pedal is NOT applied." ;
VAL_ 304 ENG_VSA_ACK1_1 15 "Reserved" 14 "Reserved" 13 "Reserved" 12 "Reserved" 11 "Reserved" 10 "Reserved" 9 "Reserved" 8 "Reserved" 7 "Reserved" 6 "Reserved" 5 "Reserved" 4 "Reserved" 3 "Reserved" 2 "All-cylinder F/C" 1 "Ignition retard" 0 "No fuel/ignition control" ;
VAL_ 304 ENG_VSA_PERMIT_PLUS_TRQ_1 1 "MSR+ torq req frm VSA permitted" 0 "MSR+ torq req frm VSA rejected" ;
VAL_ 304 ENG_VSA_INHIBIT_VSA_CONTROL_1_1 1 "ENG fail-refuse vsa ctrl" 0 "VSA control permitted" ;
VAL_ 304 ENG_VSA_REFUSED_VSA_CONTROL_1_1 1 "ENG fail-refuse vsa ctrl" 0 "VSA control permitted" ;
VAL_ 545 METER_ECONSW_ON_1 1 "ECON SW ON" 0 "ECON SW OFF" ;
VAL_ 545 METER_SW_STATUS_MODE_1 6 "Reserved" 5 "+R" 4 "SNOW" 3 "ECON" 2 "COMFORT" 1 "SPORT" 0 "NORMAL" ;
VAL_ 578 E4WD_REAR_DISTRIBUTION_242_1 10 "500" 9 "450" 8 "400" 7 "350" 6 "300" 5 "250" 4 "200" 3 "150" 2 "100" 1 "50" 0 "0" ;
VAL_ 476 ENG_IDS_MODE_TARGET_1 15 "Mode 15" 14 "Mode 14" 13 "Mode 13" 12 "Mode 12" 11 "Mode 11" 10 "Mode 10" 9 "Mode 9" 8 "Mode 8" 7 "Mode 7" 6 "Mode 6" 5 "Mode 5" 4 "Mode 4" 3 "Mode 3" 2 "Mode 2" 1 "Mode 1" 0 "Mode 0" ;
VAL_ 476 ENG_IDS_MODE_CONTROL_1 8 "Reserved" 7 "TRUCK" 6 "+R

" 5 "TOW" 4 "SNOW" 3 "ECON" 2 "COMFORT" 1 "SPORT" 0 "NORMAL" ;
VAL_ 334 E4WD_ERROR_STATUS_14E_1 1 "E4WD failure has occurred

" 0 "E4WD is operating normally

" ;
VAL_ 1029 METER_WARN_STATUS_TIRE_PRESS_1 1 "Tire Press lit" 0 "Tire press goes off" ;
VAL_ 1029 METER_WARN_STATUS_TPMS_SYSTEM_1 1 "TPMS lit" 0 "TPMS goes off" ;
VAL_ 819 TPMS_WARN_STATUS_ISO_1 1 "ISO_W / L lighting" 0 "ISO_W / L off" ;
VAL_ 819 TPMS_WARN_STATUS_SYSTEM_1 1 "TPMS_W / L lit" 0 "Description for the value '0x0'" ;
VAL_ 487 VSA_HSA_STATUS_ACT_1E7_1 1 "HSA operating" 0 "HSA inactive" ;
VAL_ 487 VSA_INHBIT_CALIPPER_PRESSRE_FR_1 1 "Cal fluid pres sensor not normal" 0 "Cal fluid pres sensor normal" ;
VAL_ 487 VSA_FAIL_CALIPPER_PRESSURE_FR_1 1 "Calip pressure sensor abnormal" 0 "Caliper pressure sensor normal" ;
VAL_ 487 VSA_INHBIT_CALIPPER_PRESSRE_FL_1 1 "Cal fluid pres sensor not normal" 0 "Cal fluid pres sensor normal" ;
VAL_ 487 VSA_FAIL_CALIPPER_PRESSURE_FL_1 1 "Calip pressure sensor abnormal" 0 "Caliper pressure sensor normal" ;
VAL_ 432 VSA_ABS_BUSY_1 1 "Brk regenratn end reqst 

" 0 "Other" ;
VAL_ 432 VSA_EPT_COMFORT_TRIG_1 1 "E-PT is ON

" 0 "Description for the value '0x0'" ;
VAL_ 432 VSA_EPT_PRECRASH_TRIG_1 1 "E-PT is ON

" 0 "Description for the value '0x0'" ;
VAL_ 432 VSA_ABS_ENB_VW_SENSOR_ACT_1 1 "Normal operation of  wss " 0 "other" ;
VAL_ 432 VSA_INHBIT_LONG_G_SENSOR_1 1 "sensor normalcy not confirmed

" 0 "sensor normalcy confirmed" ;
VAL_ 432 VSA_FAIL_LONG_G_SENSOR_1 1 "Sensor failed" 0 "Sensor normal" ;
VAL_ 432 VSA_ACC_REFUSE_ACC_BRAKE_1 1 "CMBS is prohibited. 

" 0 "CMBS enabled 

" ;
VAL_ 432 VSA_ACC_INHIBIT_ACC_BRAKE_1 1 "CMBS temporarily disabled 

" 0 "CMBS enabled " ;
VAL_ 432 VSA_ABS_VW_SENSOR_START_UP_1 1 "Wheel speed sensor started " 0 "other" ;
VAL_ 432 VSA_INHIBIT_BRAKERELAY_1 1 "Brk lamp relay temporary dsble

" 0 "other" ;
VAL_ 432 VSA_INHBIT_LAT_G_SENSOR_1 1 "sensor normalcy not confirmed

" 0 "sensor normalcy confirmed" ;
VAL_ 432 VSA_FAIL_LAT_G_SENSOR_1 2 "Sensor normal" 1 "Sensor failed" ;
VAL_ 432 VSA_ACT_BRAKERELAY_1 1 "VSA activates the brk lamp relay" 0 "other" ;
VAL_ 432 VSA_REQ_CVT_TCS_1 1 "TCS or MSR oprtn permitted 

" 0 "TCS & MSR oprtn prohibited 

" ;
VAL_ 432 VSA_REQ_CVT_PRS_1 1 "Func at brk OFF are controlled  " 0 "other" ;
VAL_ 432 VSA_CONTROL_MODE_CVT_1 3 "Reserved" 2 "Reserved" 1 "TCS/MSR is operating 

" 0 "Normal" ;
VAL_ 432 VSA_ABS_STATUS_FR_ABS_EBD_ACT_1 1 "Wheel ABS operating" 0 "Wheel ABS not operating" ;
VAL_ 432 VSA_ABS_STATUS_FL_ABS_EBD_ACT_1 1 "Wheel ABS operating" 0 "Wheel ABS not operating" ;
VAL_ 432 VSA_ABS_STATUS_RR_ABS_EBD_ACT_1 1 "Wheel ABS operating" 0 "Wheel ABS not operating" ;
VAL_ 432 VSA_ABS_STATUS_RL_ABS_EBD_ACT_1 1 "Wheel ABS operating" 0 "Wheel ABS not operating" ;
VAL_ 432 VSA_FAIL_STEERING_SENSOR_1 1 "Sensor is faulty 

" 0 "Sensor is normal

" ;
VAL_ 432 VSA_FAIL_YAW_RATE_SENSOR_1 1 "Sensor is faulty 

" 0 "Sensor is normal

" ;
VAL_ 432 VSA_FAIL_MC_PRESSRE_SENSOR_1B0_1 1 "Sensor is faulty 

" 0 "Sensor is normal

" ;
VAL_ 432 VSA_ABS_FAIL_FR_VW_SENSOR_1 1 "Sensor is faulty 

" 0 "Sensor is normal

" ;
VAL_ 432 VSA_ABS_FAIL_FL_VW_SENSOR_1 1 "Sensor is faulty 

" 0 "Sensor is normal

" ;
VAL_ 432 VSA_ABS_FAIL_RR_VW_SENSOR_1 1 "Sensor is faulty 

" 0 "Sensor is normal

" ;
VAL_ 432 VSA_ABS_FAIL_RL_VW_SENSOR_1 1 "Sensor is faulty 

" 0 "Sensor is normal

" ;
VAL_ 432 VSA_ABS_INHBIT_VW_SENSOR_1 1 "sensor normalcy not confirmed

" 0 "sensor normalcy confirmed" ;
VAL_ 432 VSA_ACC_INHIBIT_CVRS_BRAKE_1 1 "CMBS temporarily disabled 

" 0 "CMBS enabled " ;
VAL_ 432 VSA_INHBIT_STEERING_SENSOR_1 1 "sensor normalcy not confirmed

" 0 "sensor normalcy confirmed" ;
VAL_ 432 VSA_ACC_REFUSE_CVRS_BRAKE_1 1 "CMBS is prohibited. 

" 0 "CMBS enabled 

" ;
VAL_ 432 VSA_VW_PULSE_CAPTURED_1 1 "Description for the value '0x1'" 0 "No wheel speed pulse 

" ;
VAL_ 432 VSA_INHBIT_YAW_RATE_SENSOR_1 1 "sensor normalcy not confirmed

" 0 "sensor normalcy confirmed" ;
VAL_ 432 VSA_FAIL_BRAKERELAY_1 1 "Brake lamp relay being failed

" 0 "other" ;
VAL_ 432 VSA_SS30_BRAKE_ACT_1 1 "CTBA uppr limt speed or less

" 0 "CTBA uppr limt speed or more" ;
VAL_ 428 VSA_BTCS_ACT_1AC_1 1 "BTCS is active" 0 "BTCS is not active" ;
VAL_ 428 VSA_IG_ON_1 1 "VSA IG ON" 0 "VSA IG OFF

" ;
VAL_ 428 VSA_EBB_FAILURE_FOR_IS_1 1 "EBB CPU failure 

" 0 "Normal" ;
VAL_ 428 VSA_IDS_INHIBIT_DISABLED_STATE_1 1 "VSA function is disabled

" 0 "VSA function is enabled

" ;
VAL_ 428 VSA_IDS_INHIBIT_ACT_1 1 "functions under activation" 0 "other" ;
VAL_ 428 VSA_HAC_CUT_REQ_1 1 "AC cut Request 

" 0 "No request

" ;
VAL_ 428 VSA_HBB_IS_REFUSE_REQ_1 1 "Idle Stp Prohibitn Req" 0 "No request" ;
VAL_ 428 VSA_LOW_VAC_IS_SHFT_INHBIT_REQ_1 1 "Idle Stp Prohibitn Req" 0 "No request" ;
VAL_ 428 VSA_MNTMODE_STATUS_1 1 "VSA maintenance mode

" 0 "NOT in  VSA maintenance mode

" ;
VAL_ 428 VSA_REVERSE_SWITCH_FAIL_1 1 "Back light switch fails" 0 "Back light switch does NOT fail" ;
VAL_ 428 VSA_SHFT_IN_REVERSE_1 1 "Back light switch is ON. " 0 "Back light switch is OFF" ;
VAL_ 428 VSA_ECD_ACT_1 1 "EPB fluid pres ctrl ongoing 

" 0 "ctrl not ongoing 

" ;
VAL_ 428 VSA_FAIL_FOR_EPB_1 1 "Abnormal" 0 "Normal" ;
VAL_ 428 VSA_REQUEST_EPB_ACT_1 1 "EPB activation request ON " 0 "EPB activation request OFF " ;
VAL_ 428 VSA_EPB_INHIBIT_BRAKE_1 1 "Temporarily prohibited" 0 "Permitted" ;
VAL_ 428 VSA_HBB_IS_SHIFT_INHIBIT_REQ_1 1 "Idle Stp Prohibitn Req" 0 "No request" ;
VAL_ 428 VSA_TSA_ACT_1 1 "TSA Control is Active

" 0 "TSA Control is NOT Active

" ;
VAL_ 428 VSA_ISAB_ACT_1 1 "In ISAB control

" 0 "NOT in ISAB control" ;
VAL_ 428 VSA_IS_RESTART_INHIBIT_REQUEST_1 1 "Idle Stp Prohibitn Req" 0 "No request" ;
VAL_ 428 VSA_ISAB_ENABLE_1 1 "permitted" 0 "prohibited" ;
VAL_ 428 VSA_IS_SHIFT_INHIBIT_REQUEST_1_1 1 "Idle Stp Prohibitn Req" 0 "No request" ;
VAL_ 428 VSA_SHIFT_REQ_1AC_1 3 "Description for the value '0x3'" 2 "Shift up request 

" 1 "Shift hold request

" 0 "No shift ctrl request from VSA " ;
VAL_ 428 VSA_REQ_MSR_PLUS_TRQ_1 1 "Plus torque is requested

" 0 "No request" ;
VAL_ 428 VSA_TRQ_CONTROL_MODE_1 3 "VSA/TCS prohibited " 2 "Acceleration control ongoing 

" 1 "MSR control ongoing " 0 "No VSA/TCS control 

" ;
VAL_ 428 VSA_TRQ_DOWN_REQ_FUEL_CUT_1 3 "Reserved" 2 "All-cylinders F/C + ig retard 

" 1 "Ignition retard 

" 0 "No fuel/ignition control " ;
VAL_ 420 VSA_VSA_OS_CTRL_1 1 "steer suppress ctrl in progress" 0 "steer suppress ctrl not in prog" ;
VAL_ 420 VSA_ESB_INCREASE_PRESS_ACT_1 1 "Req for switch to hold is ON

" 0 " No display 

" ;
VAL_ 420 VSA_WARN_STATUS_BHOLD_1 1 "MID Warning Enabled" 0 "MID Warning Disabled" ;
VAL_ 420 VSA_MID_REQ_BHOLD_STANDBY_1 1 "Brake hold in standby mode

" 0 "Brake hold NOT in standby mode" ;
VAL_ 420 VSA_MID_REQ_BHOLD_MISOP_GUIDE_1 3 "Description for the value '3'" 2 "Bhold exit condtn unsatisfied " 1 "Bhold enter condtn unsatisfied " 0 "No Display" ;
VAL_ 420 VSA_MID_REQ_BHOLD_EPB_OP_INFO_1 1 "BHOLD transtn to EPB MID

" 0 "Do not display. " ;
VAL_ 420 VSA_MID_REQ_BHOLD_APPLY_BRAKE_1 1 "Brake pedal apply request is ON" 0 "No Display" ;
VAL_ 420 VSA_WARN_STATUS_BRAKESYSTEM_1 1 "Lamp is ON

" 0 "Lamp is OFF

" ;
VAL_ 420 VSA_LAMP_BHOLD_APPLY_BRAKE_1 1 "Lamp is ON

" 0 "Lamp is OFF

" ;
VAL_ 420 VSA_BHOLD_STATUS_ACT_1 1 "Brk hold by LSF operating " 0 "Brk hold by LSF not operating " ;
VAL_ 420 VSA_LAMP_STATUS_HDC_1 1 "Lamp is ON

" 0 "Lamp is OFF

" ;
VAL_ 420 VSA_WARN_STATUS_HDC_1 1 "ON request" 0 "OFF request" ;
VAL_ 420 VSA_LAMP_STATUS_OPERATE_BHOLD_1 1 "Lamp is ON

" 0 "Lamp is OFF

" ;
VAL_ 420 VSA_LAMP_STATUS_STANBY_BHOLD_1 1 "Lamp is ON

" 0 "Lamp is OFF

" ;
VAL_ 420 VSA_AHA_CTRL_1 1 "AHA operating " 0 "AHA not operating " ;
VAL_ 420 VSA_ACC_BRAKE_ACT_1 1 "rear end brk /ACC controlled

" 0 "rearend brk/ACC not controlled

" ;
VAL_ 420 VSA_WARN_STATUS_PUNCTURE_1 1 "Lamp is ON

" 0 "Lamp is OFF

" ;
VAL_ 420 VSA_WARN_STATUS_DWS_1 1 "Lamp is ON

" 0 "Lamp is OFF

" ;
VAL_ 420 VSA_ANSWER_DWS_INIT_REQ_1 1 "Received DWS init req

" 0 "--" ;
VAL_ 420 VSA_L_MODE_ABS_EBD_1 1 "ABS/EBD is in L-MODE

" 0 "ABS/EBD is in non-L-MODE

" ;
VAL_ 420 VSA_ABS_CTRL_1 1 "ABS is operating

" 0 "ABS is not operating

" ;
VAL_ 420 VSA_VSA_CTRL_1 1 "VSA is operating

" 0 "VSA is not operating

" ;
VAL_ 420 VSA_WARN_STATUS_HSA_1 1 "HSA warning (MID) enabled" 0 "HSA warning (MID) disabled

" ;
VAL_ 420 VSA_HSA_STATUS_ACT_1 1 "HSA is operating

" 0 "HSA is not operating" ;
VAL_ 420 VSA_ESS_ACT4_1 1 "Continue of ESS operatn enabled" 0 "Continue of ESS operatn disabled" ;
VAL_ 420 VSA_ESS_ACT3_1 1 "Start of ESS operation enabled " 0 "Start of ESS operation disabled " ;
VAL_ 420 VSA_REWRITE_START_1 1 "VSA rewriting start" 0 "Normal" ;
VAL_ 420 VSA_BUZZER_STATUS_1 1 "Lamp is ON

" 0 "Lamp is OFF

" ;
VAL_ 420 VSA_MID_REQUEST_VSA_1 1 "VSA MID warning disp enabled

" 0 "VSA MID warning disp disabled

" ;
VAL_ 420 VSA_LAMP_STATUS_VSA_OFF_1 1 "Lamp is ON

" 0 "Lamp is OFF

" ;
VAL_ 420 VSA_WARN_STATUS_VSA_1 1 "Lamp is ON

" 0 "Lamp is OFF

" ;
VAL_ 420 VSA_WARN_STATUS_ABS_1 1 "Lamp is ON

" 0 "Lamp is OFF

" ;
VAL_ 420 VSA_WARN_STATUS_BRAKE_1 1 "Lamp is ON

" 0 "Lamp is OFF

" ;
VAL_ 420 VSA_VSA_TCS_ACT_1 1 "VSA or TCS is operating

" 0 "VSA and TCS are not operating

" ;
VAL_ 420 VSA_ABS_EBD_ACT_1 1 "ABS or EBD is operating

" 0 "ABS and EBD are not operating

" ;
VAL_ 420 VSA_VSA_TCS_MIL_1 1 "VSA or TCS failure is detected

" 0 "VSA and TCS are normal

" ;
VAL_ 420 VSA_ABS_EBD_MIL_1 1 "Detecting ABS or EBD failure

" 0 "ABS and EBD are normal

" ;
VAL_ 420 VSA_CASEN_1 1 "CAS control is possible

" 0 "CAS control is not possible

" ;
VAL_ 420 VSA_CAS_ACT_1 1 "In CAS control

" 0 "Not In CAS control" ;
VAL_ 420 VSA_BA_ACT_1 1 "BA is being controlled

" 0 "BA is not being controlled" ;
VAL_ 420 VSA_FAIL_MC_PRESSURE_SENSOR_1_1 1 "Sensor is faulty" 0 "Sensor is normal" ;
VAL_ 420 VSA_INHBIT_MC_PRESSURE_SENSOR_1 1 " mc pres sensr norml:not confirm" 0 " mc pres sensr norml:confirm" ;
VAL_ 420 VSA_ESS_ACT2_1 1 "Continue of ESS operatn enabled" 0 "Continue of ESS operatn disabled" ;
VAL_ 420 VSA_ESS_ACT1_1 1 "Start of ESS operation enabled " 0 "Start of ESS operation disabled " ;
VAL_ 145 VSA_SENSOR_START_UP_1 1 "During start check" 0 "start check normal" ;
VAL_ 145 VSA_SENSOR_ERR_MC_1 1 "Fault confirmed by diag" 0 "Normal time" ;
VAL_ 145 VSA_SENSOR_STATE_IG_1 1 "volt cant protect func of sensor" 0 "Normal time" ;
VAL_ 145 VSA_P_ERR_LON_G_1 1 "front/rear G accelratn confirmed" 0 "Normal time" ;
VAL_ 145 VSA_P_ERR_LAT_G_1 1 "lateral G acceleration is fixed" 0 "Normal time" ;
VAL_ 145 VSA_P_ERR_DEGC_1 1 "temp data is fixed" 0 "Normal time" ;
VAL_ 145 VSA_P_ERR_YAW1_1 1 "failure of yaw rate is fixed" 0 "Normal time" ;
VAL_ 145 VSA_T_ERR_LON_G_1 1 "Acceleratn cant be guaranteed" 0 "Normal time" ;
VAL_ 145 VSA_T_ERR_LAT_G_1 1 "Acceleratn cant be guaranteed" 0 "Normal time" ;
VAL_ 145 VSA_T_ERR_DEGC_1 1 "Temp data cant be guaranteed" 0 "Normal time" ;
VAL_ 145 VSA_T_ERR_YAW1_1 1 "YAW1 cannot be guaranteed" 0 "Normal Time" ;
